VERSION ""

NS_ :

BS_:

BU_:

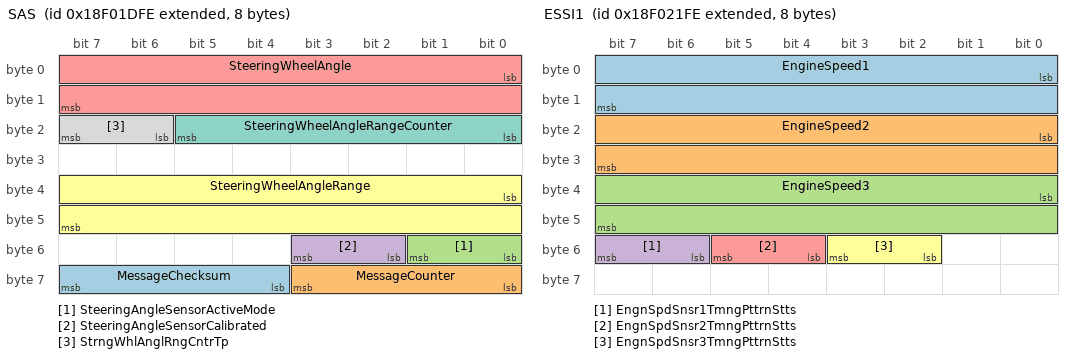
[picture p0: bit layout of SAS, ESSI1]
BO_ 2565873150 SAS: 8 Vector__XXX
 SG_ MessageChecksum : 60|4@1+ (1,0) [0|15] "count" Vector__XXX
 SG_ MessageCounter : 56|4@1+ (1,0) [0|15] "count" Vector__XXX
 SG_ SteeringAngleSensorActiveMode : 48|2@1+ (1,0) [0|3] "" Vector__XXX
 SG_ SteeringAngleSensorCalibrated : 50|2@1+ (1,0) [0|3] "" Vector__XXX
 SG_ SteeringWheelAngle : 0|16@1+ (0.0009765625,-31.374) [-31.374|31.374] "rad" Vector__XXX
 SG_ SteeringWheelAngleRange : 32|16@1+ (0.0009765625,-31.374) [-31.374|31.374] "rad" Vector__XXX
 SG_ SteeringWheelAngleRangeCounter : 16|6@1+ (1,-32) [-32|29] "range" Vector__XXX
 SG_ StrngWhlAnglRngCntrTp : 22|2@1+ (1,0) [0|3] "" Vector__XXX

BO_ 2565874174 ESSI1: 8 Vector__XXX
 SG_ EngineSpeed1 : 0|16@1+ (0.5,0) [0|32127.5] "rpm" Vector__XXX
 SG_ EngineSpeed2 : 16|16@1+ (0.5,0) [0|32127.5] "rpm" Vector__XXX
 SG_ EngineSpeed3 : 32|16@1+ (0.5,0) [0|32127.5] "rpm" Vector__XXX
 SG_ EngnSpdSnsr1TmngPttrnStts : 54|2@1+ (1,0) [0|3] "" Vector__XXX
 SG_ EngnSpdSnsr2TmngPttrnStts : 52|2@1+ (1,0) [0|3] "" Vector__XXX
 SG_ EngnSpdSnsr3TmngPttrnStts : 50|2@1+ (1,0) [0|3] "" Vector__XXX

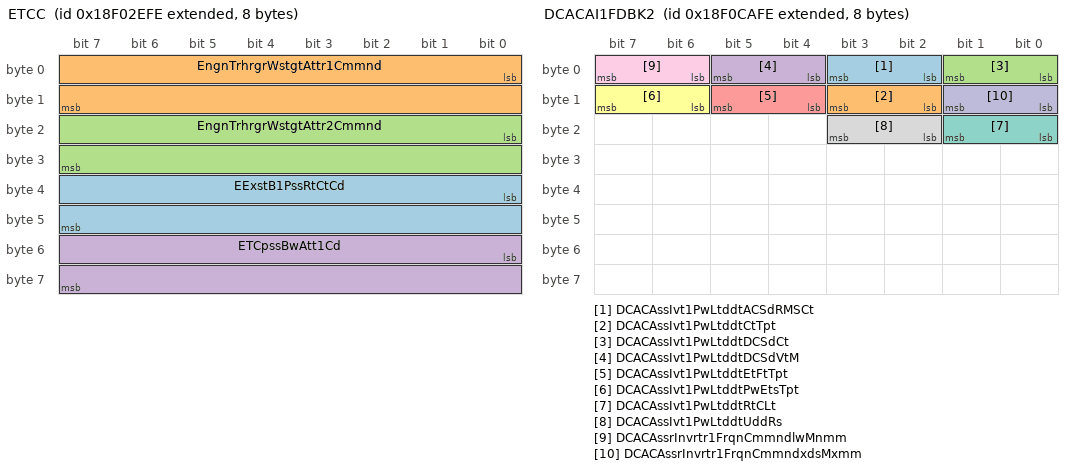
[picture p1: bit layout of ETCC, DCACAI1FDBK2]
BO_ 2565877502 ETCC: 8 Vector__XXX
 SG_ EExstB1PssRtCtCd : 32|16@1+ (0.0025,0) [0|160.6375] "%" Vector__XXX
 SG_ EngnTrhrgrWstgtAttr1Cmmnd : 0|16@1+ (0.0025,0) [0|160.6375] "%" Vector__XXX
 SG_ EngnTrhrgrWstgtAttr2Cmmnd : 16|16@1+ (0.0025,0) [0|160.6375] "%" Vector__XXX
 SG_ ETCpssBwAtt1Cd : 48|16@1+ (0.0025,0) [0|160.6375] "%" Vector__XXX

BO_ 2565917438 DCACAI1FDBK2: 8 Vector__XXX
 SG_ DCACAssIvt1PwLtddtACSdRMSCt : 2|2@1+ (1,0) [0|3] "" Vector__XXX
 SG_ DCACAssIvt1PwLtddtCtTpt : 10|2@1+ (1,0) [0|3] "" Vector__XXX
 SG_ DCACAssIvt1PwLtddtDCSdCt : 0|2@1+ (1,0) [0|3] "" Vector__XXX
 SG_ DCACAssIvt1PwLtddtDCSdVtM : 4|2@1+ (1,0) [0|3] "" Vector__XXX
 SG_ DCACAssIvt1PwLtddtEtFtTpt : 12|2@1+ (1,0) [0|3] "" Vector__XXX
 SG_ DCACAssIvt1PwLtddtPwEtsTpt : 14|2@1+ (1,0) [0|3] "" Vector__XXX
 SG_ DCACAssIvt1PwLtddtRtCLt : 16|2@1+ (1,0) [0|3] "" Vector__XXX
 SG_ DCACAssIvt1PwLtddtUddRs : 18|2@1+ (1,0) [0|3] "" Vector__XXX
 SG_ DCACAssrInvrtr1FrqnCmmndlwMnmm : 6|2@1+ (1,0) [0|3] "" Vector__XXX
 SG_ DCACAssrInvrtr1FrqnCmmndxdsMxmm : 8|2@1+ (1,0) [0|3] "" Vector__XXX

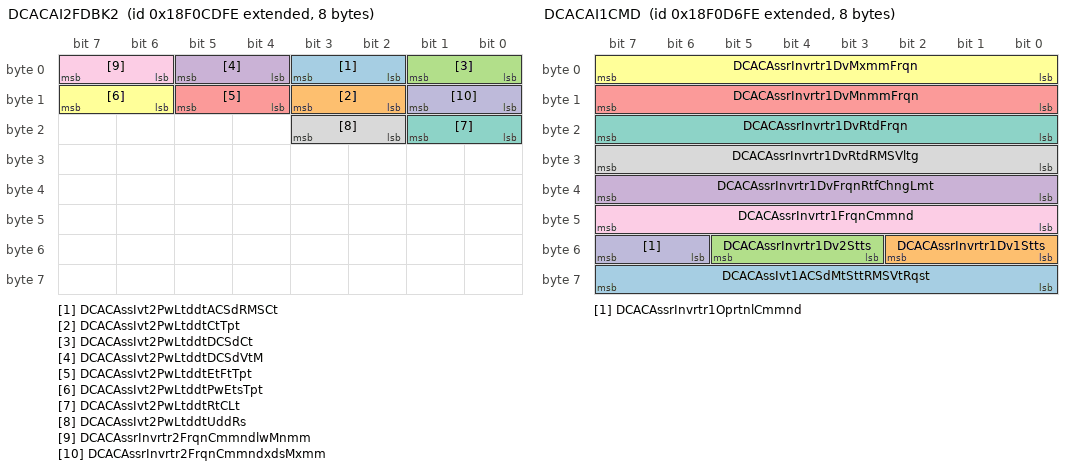
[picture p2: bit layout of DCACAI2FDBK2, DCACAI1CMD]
BO_ 2565918206 DCACAI2FDBK2: 8 Vector__XXX
 SG_ DCACAssIvt2PwLtddtACSdRMSCt : 2|2@1+ (1,0) [0|3] "" Vector__XXX
 SG_ DCACAssIvt2PwLtddtCtTpt : 10|2@1+ (1,0) [0|3] "" Vector__XXX
 SG_ DCACAssIvt2PwLtddtDCSdCt : 0|2@1+ (1,0) [0|3] "" Vector__XXX
 SG_ DCACAssIvt2PwLtddtDCSdVtM : 4|2@1+ (1,0) [0|3] "" Vector__XXX
 SG_ DCACAssIvt2PwLtddtEtFtTpt : 12|2@1+ (1,0) [0|3] "" Vector__XXX
 SG_ DCACAssIvt2PwLtddtPwEtsTpt : 14|2@1+ (1,0) [0|3] "" Vector__XXX
 SG_ DCACAssIvt2PwLtddtRtCLt : 16|2@1+ (1,0) [0|3] "" Vector__XXX
 SG_ DCACAssIvt2PwLtddtUddRs : 18|2@1+ (1,0) [0|3] "" Vector__XXX
 SG_ DCACAssrInvrtr2FrqnCmmndlwMnmm : 6|2@1+ (1,0) [0|3] "" Vector__XXX
 SG_ DCACAssrInvrtr2FrqnCmmndxdsMxmm : 8|2@1+ (1,0) [0|3] "" Vector__XXX

BO_ 2565920510 DCACAI1CMD: 8 Vector__XXX
 SG_ DCACAssIvt1ACSdMtSttRMSVtRqst : 56|8@1+ (2,0) [0|500] "V" Vector__XXX
 SG_ DCACAssrInvrtr1Dv1Stts : 48|3@1+ (1,0) [0|7] "" Vector__XXX
 SG_ DCACAssrInvrtr1Dv2Stts : 51|3@1+ (1,0) [0|7] "" Vector__XXX
 SG_ DCACAssrInvrtr1DvFrqnRtfChngLmt : 32|8@1+ (2,0) [0|500] "Hz/s" Vector__XXX
 SG_ DCACAssrInvrtr1DvMnmmFrqn : 8|8@1+ (1,0) [0|250] "Hz" Vector__XXX
 SG_ DCACAssrInvrtr1DvMxmmFrqn : 0|8@1+ (1,0) [0|250] "Hz" Vector__XXX
 SG_ DCACAssrInvrtr1DvRtdFrqn : 16|8@1+ (1,0) [0|250] "Hz" Vector__XXX
 SG_ DCACAssrInvrtr1DvRtdRMSVltg : 24|8@1+ (2,0) [0|500] "V" Vector__XXX
 SG_ DCACAssrInvrtr1FrqnCmmnd : 40|8@1+ (1,0) [0|250] "Hz" Vector__XXX
 SG_ DCACAssrInvrtr1OprtnlCmmnd : 54|2@1+ (1,0) [0|3] "" Vector__XXX

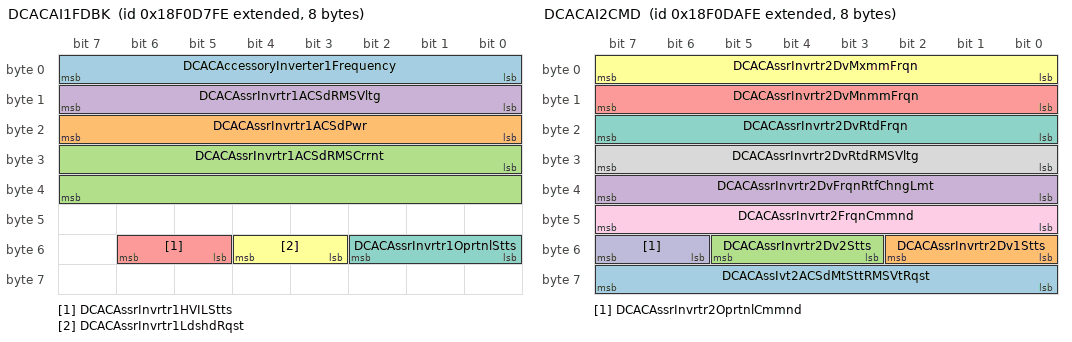
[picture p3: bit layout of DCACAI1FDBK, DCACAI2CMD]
BO_ 2565920766 DCACAI1FDBK: 8 Vector__XXX
 SG_ DCACAccessoryInverter1Frequency : 0|8@1+ (1,0) [0|250] "Hz" Vector__XXX
 SG_ DCACAssrInvrtr1ACSdPwr : 16|8@1+ (0.1,0) [0|25] "kW" Vector__XXX
 SG_ DCACAssrInvrtr1ACSdRMSCrrnt : 24|16@1+ (0.03125,0) [0|2007.96875] "A" Vector__XXX
 SG_ DCACAssrInvrtr1ACSdRMSVltg : 8|8@1+ (2,0) [0|500] "V" Vector__XXX
 SG_ DCACAssrInvrtr1HVILStts : 53|2@1+ (1,0) [0|3] "" Vector__XXX
 SG_ DCACAssrInvrtr1LdshdRqst : 51|2@1+ (1,0) [0|3] "" Vector__XXX
 SG_ DCACAssrInvrtr1OprtnlStts : 48|3@1+ (1,0) [0|7] "" Vector__XXX

BO_ 2565921534 DCACAI2CMD: 8 Vector__XXX
 SG_ DCACAssIvt2ACSdMtSttRMSVtRqst : 56|8@1+ (2,0) [0|500] "V" Vector__XXX
 SG_ DCACAssrInvrtr2Dv1Stts : 48|3@1+ (1,0) [0|7] "" Vector__XXX
 SG_ DCACAssrInvrtr2Dv2Stts : 51|3@1+ (1,0) [0|7] "" Vector__XXX
 SG_ DCACAssrInvrtr2DvFrqnRtfChngLmt : 32|8@1+ (2,0) [0|500] "Hz/s" Vector__XXX
 SG_ DCACAssrInvrtr2DvMnmmFrqn : 8|8@1+ (1,0) [0|250] "Hz" Vector__XXX
 SG_ DCACAssrInvrtr2DvMxmmFrqn : 0|8@1+ (1,0) [0|250] "Hz" Vector__XXX
 SG_ DCACAssrInvrtr2DvRtdFrqn : 16|8@1+ (1,0) [0|250] "Hz" Vector__XXX
 SG_ DCACAssrInvrtr2DvRtdRMSVltg : 24|8@1+ (2,0) [0|500] "V" Vector__XXX
 SG_ DCACAssrInvrtr2FrqnCmmnd : 40|8@1+ (1,0) [0|250] "Hz" Vector__XXX
 SG_ DCACAssrInvrtr2OprtnlCmmnd : 54|2@1+ (1,0) [0|3] "" Vector__XXX

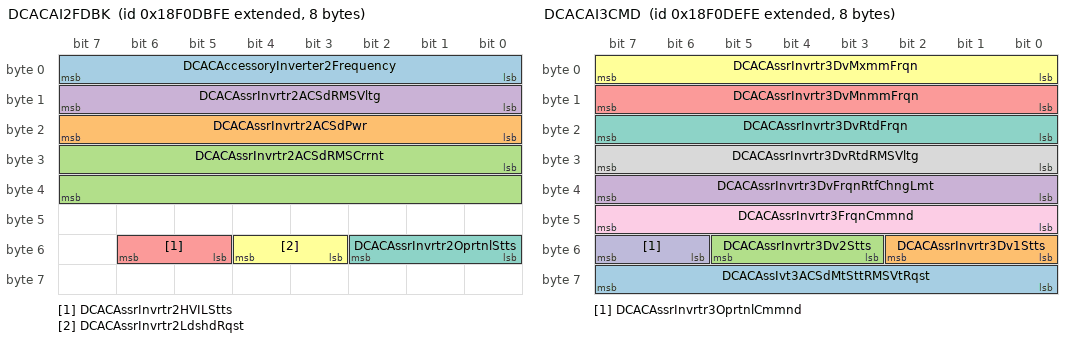
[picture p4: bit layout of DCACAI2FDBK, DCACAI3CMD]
BO_ 2565921790 DCACAI2FDBK: 8 Vector__XXX
 SG_ DCACAccessoryInverter2Frequency : 0|8@1+ (1,0) [0|250] "Hz" Vector__XXX
 SG_ DCACAssrInvrtr2ACSdPwr : 16|8@1+ (0.1,0) [0|25] "kW" Vector__XXX
 SG_ DCACAssrInvrtr2ACSdRMSCrrnt : 24|16@1+ (0.03125,0) [0|2007.96875] "A" Vector__XXX
 SG_ DCACAssrInvrtr2ACSdRMSVltg : 8|8@1+ (2,0) [0|500] "V" Vector__XXX
 SG_ DCACAssrInvrtr2HVILStts : 53|2@1+ (1,0) [0|3] "" Vector__XXX
 SG_ DCACAssrInvrtr2LdshdRqst : 51|2@1+ (1,0) [0|3] "" Vector__XXX
 SG_ DCACAssrInvrtr2OprtnlStts : 48|3@1+ (1,0) [0|7] "" Vector__XXX

BO_ 2565922558 DCACAI3CMD: 8 Vector__XXX
 SG_ DCACAssIvt3ACSdMtSttRMSVtRqst : 56|8@1+ (2,0) [0|500] "V" Vector__XXX
 SG_ DCACAssrInvrtr3Dv1Stts : 48|3@1+ (1,0) [0|7] "" Vector__XXX
 SG_ DCACAssrInvrtr3Dv2Stts : 51|3@1+ (1,0) [0|7] "" Vector__XXX
 SG_ DCACAssrInvrtr3DvFrqnRtfChngLmt : 32|8@1+ (2,0) [0|500] "Hz/s" Vector__XXX
 SG_ DCACAssrInvrtr3DvMnmmFrqn : 8|8@1+ (1,0) [0|250] "Hz" Vector__XXX
 SG_ DCACAssrInvrtr3DvMxmmFrqn : 0|8@1+ (1,0) [0|250] "Hz" Vector__XXX
 SG_ DCACAssrInvrtr3DvRtdFrqn : 16|8@1+ (1,0) [0|250] "Hz" Vector__XXX
 SG_ DCACAssrInvrtr3DvRtdRMSVltg : 24|8@1+ (2,0) [0|500] "V" Vector__XXX
 SG_ DCACAssrInvrtr3FrqnCmmnd : 40|8@1+ (1,0) [0|250] "Hz" Vector__XXX
 SG_ DCACAssrInvrtr3OprtnlCmmnd : 54|2@1+ (1,0) [0|3] "" Vector__XXX

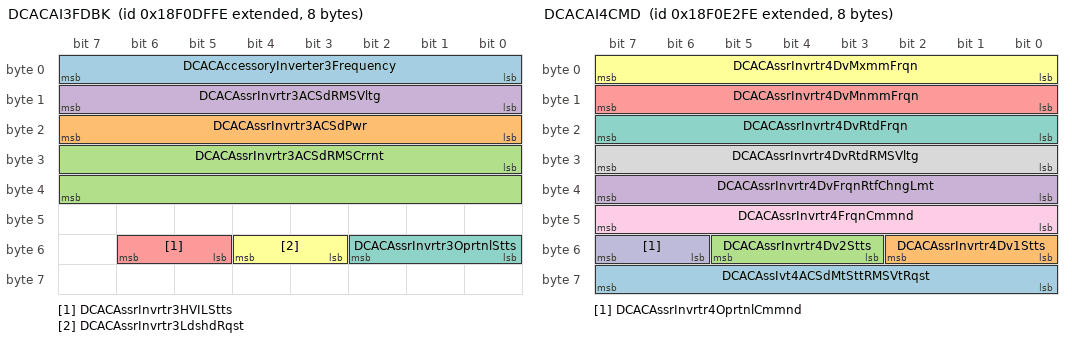
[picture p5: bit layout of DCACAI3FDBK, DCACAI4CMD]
BO_ 2565922814 DCACAI3FDBK: 8 Vector__XXX
 SG_ DCACAccessoryInverter3Frequency : 0|8@1+ (1,0) [0|250] "Hz" Vector__XXX
 SG_ DCACAssrInvrtr3ACSdPwr : 16|8@1+ (0.1,0) [0|25] "kW" Vector__XXX
 SG_ DCACAssrInvrtr3ACSdRMSCrrnt : 24|16@1+ (0.03125,0) [0|2007.96875] "A" Vector__XXX
 SG_ DCACAssrInvrtr3ACSdRMSVltg : 8|8@1+ (2,0) [0|500] "V" Vector__XXX
 SG_ DCACAssrInvrtr3HVILStts : 53|2@1+ (1,0) [0|3] "" Vector__XXX
 SG_ DCACAssrInvrtr3LdshdRqst : 51|2@1+ (1,0) [0|3] "" Vector__XXX
 SG_ DCACAssrInvrtr3OprtnlStts : 48|3@1+ (1,0) [0|7] "" Vector__XXX

BO_ 2565923582 DCACAI4CMD: 8 Vector__XXX
 SG_ DCACAssIvt4ACSdMtSttRMSVtRqst : 56|8@1+ (2,0) [0|500] "V" Vector__XXX
 SG_ DCACAssrInvrtr4Dv1Stts : 48|3@1+ (1,0) [0|7] "" Vector__XXX
 SG_ DCACAssrInvrtr4Dv2Stts : 51|3@1+ (1,0) [0|7] "" Vector__XXX
 SG_ DCACAssrInvrtr4DvFrqnRtfChngLmt : 32|8@1+ (2,0) [0|500] "Hz/s" Vector__XXX
 SG_ DCACAssrInvrtr4DvMnmmFrqn : 8|8@1+ (1,0) [0|250] "Hz" Vector__XXX
 SG_ DCACAssrInvrtr4DvMxmmFrqn : 0|8@1+ (1,0) [0|250] "Hz" Vector__XXX
 SG_ DCACAssrInvrtr4DvRtdFrqn : 16|8@1+ (1,0) [0|250] "Hz" Vector__XXX
 SG_ DCACAssrInvrtr4DvRtdRMSVltg : 24|8@1+ (2,0) [0|500] "V" Vector__XXX
 SG_ DCACAssrInvrtr4FrqnCmmnd : 40|8@1+ (1,0) [0|250] "Hz" Vector__XXX
 SG_ DCACAssrInvrtr4OprtnlCmmnd : 54|2@1+ (1,0) [0|3] "" Vector__XXX

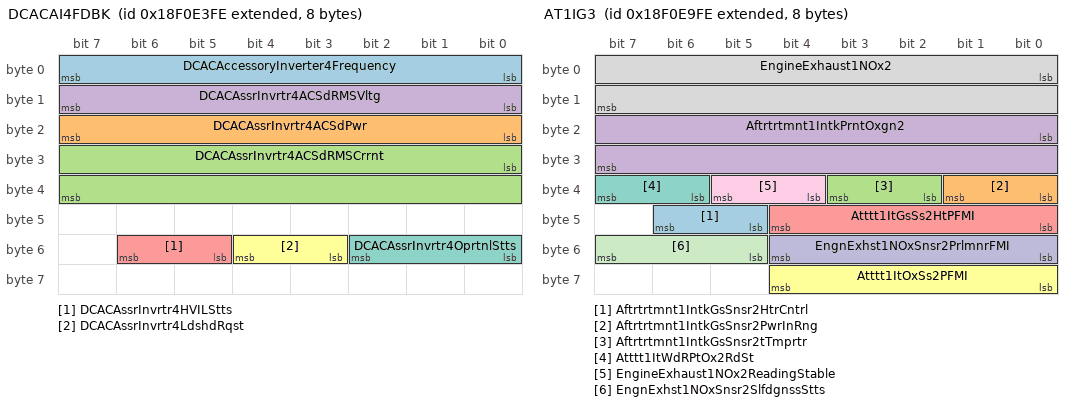
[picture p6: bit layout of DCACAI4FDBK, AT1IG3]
BO_ 2565923838 DCACAI4FDBK: 8 Vector__XXX
 SG_ DCACAccessoryInverter4Frequency : 0|8@1+ (1,0) [0|250] "Hz" Vector__XXX
 SG_ DCACAssrInvrtr4ACSdPwr : 16|8@1+ (0.1,0) [0|25] "kW" Vector__XXX
 SG_ DCACAssrInvrtr4ACSdRMSCrrnt : 24|16@1+ (0.03125,0) [0|2007.96875] "A" Vector__XXX
 SG_ DCACAssrInvrtr4ACSdRMSVltg : 8|8@1+ (2,0) [0|500] "V" Vector__XXX
 SG_ DCACAssrInvrtr4HVILStts : 53|2@1+ (1,0) [0|3] "" Vector__XXX
 SG_ DCACAssrInvrtr4LdshdRqst : 51|2@1+ (1,0) [0|3] "" Vector__XXX
 SG_ DCACAssrInvrtr4OprtnlStts : 48|3@1+ (1,0) [0|7] "" Vector__XXX

BO_ 2565925374 AT1IG3: 8 Vector__XXX
 SG_ Aftrtrtmnt1IntkGsSnsr2HtrCntrl : 45|2@1+ (1,0) [0|3] "" Vector__XXX
 SG_ Aftrtrtmnt1IntkGsSnsr2PwrInRng : 32|2@1+ (1,0) [0|3] "" Vector__XXX
 SG_ Aftrtrtmnt1IntkGsSnsr2tTmprtr : 34|2@1+ (1,0) [0|3] "" Vector__XXX
 SG_ Aftrtrtmnt1IntkPrntOxgn2 : 16|16@1+ (0.000514,-12) [-12|21.02707] "%" Vector__XXX
 SG_ Atttt1ItGsSs2HtPFMI : 40|5@1+ (1,0) [0|31] "binary" Vector__XXX
 SG_ Atttt1ItOxSs2PFMI : 56|5@1+ (1,0) [0|31] "binary" Vector__XXX
 SG_ Atttt1ItWdRPtOx2RdSt : 38|2@1+ (1,0) [0|3] "" Vector__XXX
 SG_ EngineExhaust1NOx2 : 0|16@1+ (0.05,-200) [-200|3012.75] "ppm" Vector__XXX
 SG_ EngineExhaust1NOx2ReadingStable : 36|2@1+ (1,0) [0|3] "" Vector__XXX
 SG_ EngnExhst1NOxSnsr2PrlmnrFMI : 48|5@1+ (1,0) [0|31] "binary" Vector__XXX
 SG_ EngnExhst1NOxSnsr2SlfdgnssStts : 53|3@1+ (1,0) [0|7] "" Vector__XXX

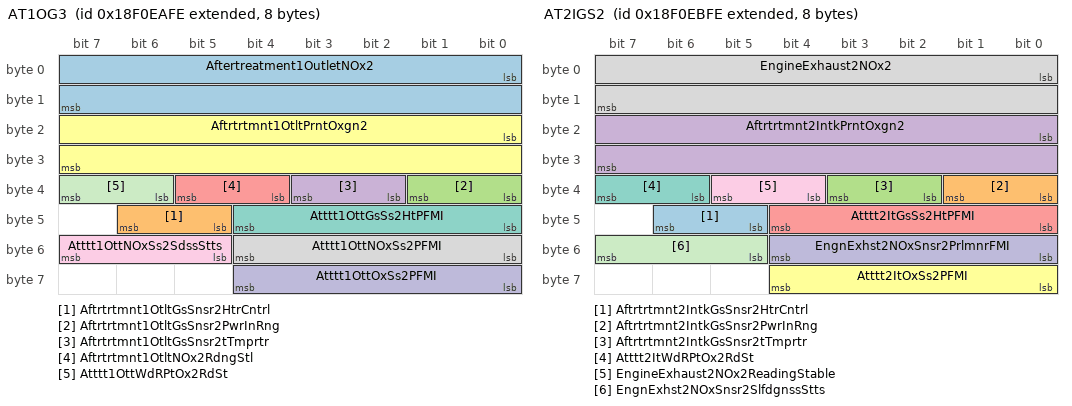
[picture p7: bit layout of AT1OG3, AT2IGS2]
BO_ 2565925630 AT1OG3: 8 Vector__XXX
 SG_ Aftertreatment1OutletNOx2 : 0|16@1+ (0.05,-200) [-200|3012.75] "ppm" Vector__XXX
 SG_ Aftrtrtmnt1OtltGsSnsr2HtrCntrl : 45|2@1+ (1,0) [0|3] "" Vector__XXX
 SG_ Aftrtrtmnt1OtltGsSnsr2PwrInRng : 32|2@1+ (1,0) [0|3] "" Vector__XXX
 SG_ Aftrtrtmnt1OtltGsSnsr2tTmprtr : 34|2@1+ (1,0) [0|3] "" Vector__XXX
 SG_ Aftrtrtmnt1OtltNOx2RdngStl : 36|2@1+ (1,0) [0|3] "" Vector__XXX
 SG_ Aftrtrtmnt1OtltPrntOxgn2 : 16|16@1+ (0.000514,-12) [-12|21.02707] "%" Vector__XXX
 SG_ Atttt1OttGsSs2HtPFMI : 40|5@1+ (1,0) [0|31] "binary" Vector__XXX
 SG_ Atttt1OttNOxSs2PFMI : 48|5@1+ (1,0) [0|31] "binary" Vector__XXX
 SG_ Atttt1OttNOxSs2SdssStts : 53|3@1+ (1,0) [0|7] "" Vector__XXX
 SG_ Atttt1OttOxSs2PFMI : 56|5@1+ (1,0) [0|31] "binary" Vector__XXX
 SG_ Atttt1OttWdRPtOx2RdSt : 38|2@1+ (1,0) [0|3] "" Vector__XXX

BO_ 2565925886 AT2IGS2: 8 Vector__XXX
 SG_ Aftrtrtmnt2IntkGsSnsr2HtrCntrl : 45|2@1+ (1,0) [0|3] "" Vector__XXX
 SG_ Aftrtrtmnt2IntkGsSnsr2PwrInRng : 32|2@1+ (1,0) [0|3] "" Vector__XXX
 SG_ Aftrtrtmnt2IntkGsSnsr2tTmprtr : 34|2@1+ (1,0) [0|3] "" Vector__XXX
 SG_ Aftrtrtmnt2IntkPrntOxgn2 : 16|16@1+ (0.000514,-12) [-12|21.02707] "%" Vector__XXX
 SG_ Atttt2ItGsSs2HtPFMI : 40|5@1+ (1,0) [0|31] "binary" Vector__XXX
 SG_ Atttt2ItOxSs2PFMI : 56|5@1+ (1,0) [0|31] "binary" Vector__XXX
 SG_ Atttt2ItWdRPtOx2RdSt : 38|2@1+ (1,0) [0|3] "" Vector__XXX
 SG_ EngineExhaust2NOx2 : 0|16@1+ (0.05,-200) [-200|3012.75] "ppm" Vector__XXX
 SG_ EngineExhaust2NOx2ReadingStable : 36|2@1+ (1,0) [0|3] "" Vector__XXX
 SG_ EngnExhst2NOxSnsr2PrlmnrFMI : 48|5@1+ (1,0) [0|31] "binary" Vector__XXX
 SG_ EngnExhst2NOxSnsr2SlfdgnssStts : 53|3@1+ (1,0) [0|7] "" Vector__XXX

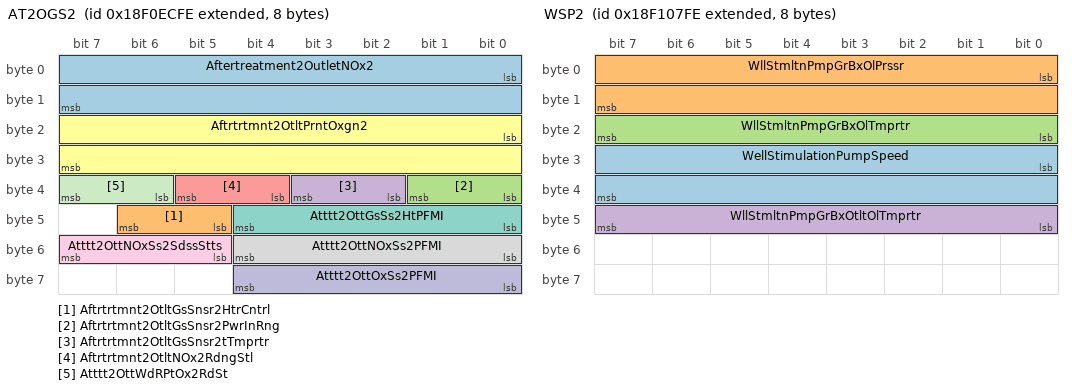
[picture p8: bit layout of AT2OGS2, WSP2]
BO_ 2565926142 AT2OGS2: 8 Vector__XXX
 SG_ Aftertreatment2OutletNOx2 : 0|16@1+ (0.05,-200) [-200|3012.75] "ppm" Vector__XXX
 SG_ Aftrtrtmnt2OtltGsSnsr2HtrCntrl : 45|2@1+ (1,0) [0|3] "" Vector__XXX
 SG_ Aftrtrtmnt2OtltGsSnsr2PwrInRng : 32|2@1+ (1,0) [0|3] "" Vector__XXX
 SG_ Aftrtrtmnt2OtltGsSnsr2tTmprtr : 34|2@1+ (1,0) [0|3] "" Vector__XXX
 SG_ Aftrtrtmnt2OtltNOx2RdngStl : 36|2@1+ (1,0) [0|3] "" Vector__XXX
 SG_ Aftrtrtmnt2OtltPrntOxgn2 : 16|16@1+ (0.000514,-12) [-12|21.02707] "%" Vector__XXX
 SG_ Atttt2OttGsSs2HtPFMI : 40|5@1+ (1,0) [0|31] "binary" Vector__XXX
 SG_ Atttt2OttNOxSs2PFMI : 48|5@1+ (1,0) [0|31] "binary" Vector__XXX
 SG_ Atttt2OttNOxSs2SdssStts : 53|3@1+ (1,0) [0|7] "" Vector__XXX
 SG_ Atttt2OttOxSs2PFMI : 56|5@1+ (1,0) [0|31] "binary" Vector__XXX
 SG_ Atttt2OttWdRPtOx2RdSt : 38|2@1+ (1,0) [0|3] "" Vector__XXX

BO_ 2565932286 ESSI2: 8 Vector__XXX
 SG_ EngineSpeed4 : 0|16@1+ (0.5,0) [0|32127.5] "rpm" Vector__XXX

BO_ 2565932798 WSP1: 8 Vector__XXX
 SG_ WllStmltnPmpDshrgPrssr : 16|16@1+ (5,0) [0|321275] "kPa" Vector__XXX
 SG_ WllStmltnPmpStnPrssr : 0|16@1+ (0.1,-3212.7) [-3212.7|3212.8] "kPa" Vector__XXX

BO_ 2565933054 WSP2: 8 Vector__XXX
 SG_ WellStimulationPumpSpeed : 24|16@1+ (0.125,0) [0|8031.875] "rpm" Vector__XXX
 SG_ WllStmltnPmpGrBxOlPrssr : 0|16@1+ (0.1,0) [0|6425.5] "kPa" Vector__XXX
 SG_ WllStmltnPmpGrBxOlTmprtr : 16|8@1+ (1,-40) [-40|210] "degC" Vector__XXX
 SG_ WllStmltnPmpGrBxOtltOlTmprtr : 40|8@1+ (1,-40) [-40|210] "degC" Vector__XXX

BO_ 2565934590 GFI6: 8 Vector__XXX
 SG_ EngnFlVlv2DffrntlPrssr : 0|16@1+ (0.1,0) [0|6425.5] "kPa" Vector__XXX

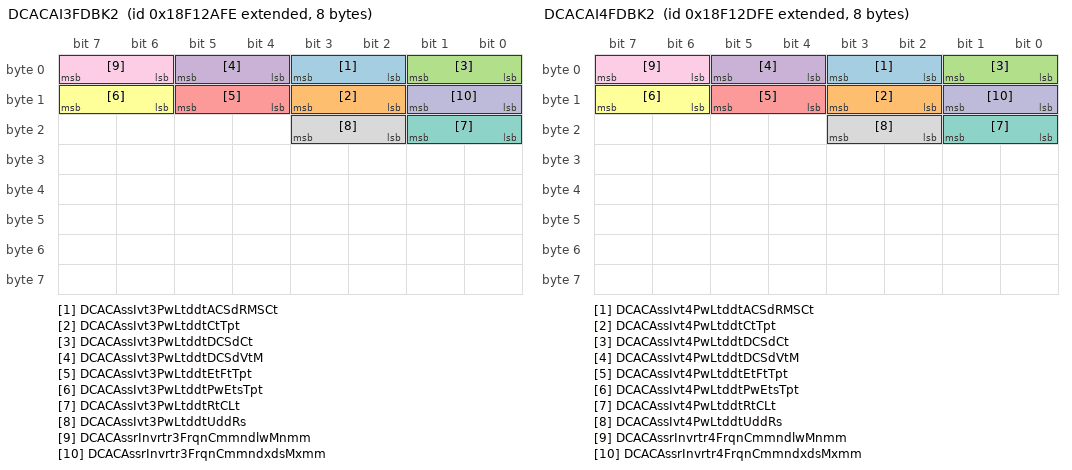
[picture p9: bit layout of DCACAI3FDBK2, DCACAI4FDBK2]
BO_ 2565942014 DCACAI3FDBK2: 8 Vector__XXX
 SG_ DCACAssIvt3PwLtddtACSdRMSCt : 2|2@1+ (1,0) [0|3] "" Vector__XXX
 SG_ DCACAssIvt3PwLtddtCtTpt : 10|2@1+ (1,0) [0|3] "" Vector__XXX
 SG_ DCACAssIvt3PwLtddtDCSdCt : 0|2@1+ (1,0) [0|3] "" Vector__XXX
 SG_ DCACAssIvt3PwLtddtDCSdVtM : 4|2@1+ (1,0) [0|3] "" Vector__XXX
 SG_ DCACAssIvt3PwLtddtEtFtTpt : 12|2@1+ (1,0) [0|3] "" Vector__XXX
 SG_ DCACAssIvt3PwLtddtPwEtsTpt : 14|2@1+ (1,0) [0|3] "" Vector__XXX
 SG_ DCACAssIvt3PwLtddtRtCLt : 16|2@1+ (1,0) [0|3] "" Vector__XXX
 SG_ DCACAssIvt3PwLtddtUddRs : 18|2@1+ (1,0) [0|3] "" Vector__XXX
 SG_ DCACAssrInvrtr3FrqnCmmndlwMnmm : 6|2@1+ (1,0) [0|3] "" Vector__XXX
 SG_ DCACAssrInvrtr3FrqnCmmndxdsMxmm : 8|2@1+ (1,0) [0|3] "" Vector__XXX

BO_ 2565942782 DCACAI4FDBK2: 8 Vector__XXX
 SG_ DCACAssIvt4PwLtddtACSdRMSCt : 2|2@1+ (1,0) [0|3] "" Vector__XXX
 SG_ DCACAssIvt4PwLtddtCtTpt : 10|2@1+ (1,0) [0|3] "" Vector__XXX
 SG_ DCACAssIvt4PwLtddtDCSdCt : 0|2@1+ (1,0) [0|3] "" Vector__XXX
 SG_ DCACAssIvt4PwLtddtDCSdVtM : 4|2@1+ (1,0) [0|3] "" Vector__XXX
 SG_ DCACAssIvt4PwLtddtEtFtTpt : 12|2@1+ (1,0) [0|3] "" Vector__XXX
 SG_ DCACAssIvt4PwLtddtPwEtsTpt : 14|2@1+ (1,0) [0|3] "" Vector__XXX
 SG_ DCACAssIvt4PwLtddtRtCLt : 16|2@1+ (1,0) [0|3] "" Vector__XXX
 SG_ DCACAssIvt4PwLtddtUddRs : 18|2@1+ (1,0) [0|3] "" Vector__XXX
 SG_ DCACAssrInvrtr4FrqnCmmndlwMnmm : 6|2@1+ (1,0) [0|3] "" Vector__XXX
 SG_ DCACAssrInvrtr4FrqnCmmndxdsMxmm : 8|2@1+ (1,0) [0|3] "" Vector__XXX

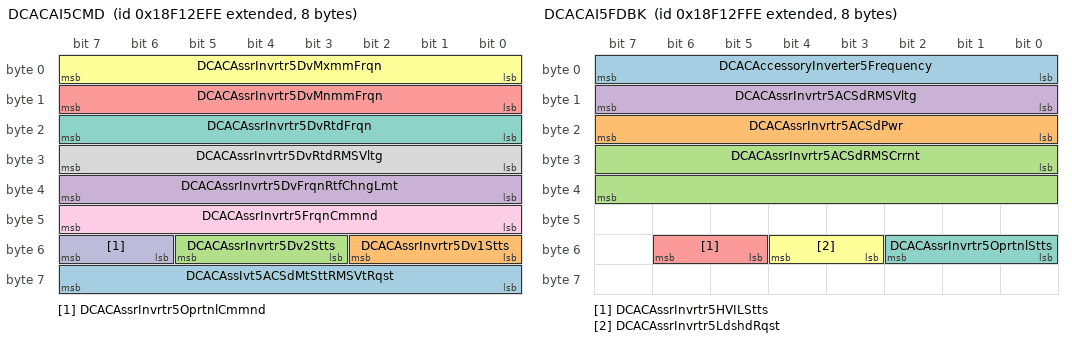
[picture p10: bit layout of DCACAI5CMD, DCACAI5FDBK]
BO_ 2565943038 DCACAI5CMD: 8 Vector__XXX
 SG_ DCACAssIvt5ACSdMtSttRMSVtRqst : 56|8@1+ (2,0) [0|500] "V" Vector__XXX
 SG_ DCACAssrInvrtr5Dv1Stts : 48|3@1+ (1,0) [0|7] "" Vector__XXX
 SG_ DCACAssrInvrtr5Dv2Stts : 51|3@1+ (1,0) [0|7] "" Vector__XXX
 SG_ DCACAssrInvrtr5DvFrqnRtfChngLmt : 32|8@1+ (2,0) [0|500] "Hz/s" Vector__XXX
 SG_ DCACAssrInvrtr5DvMnmmFrqn : 8|8@1+ (1,0) [0|250] "Hz" Vector__XXX
 SG_ DCACAssrInvrtr5DvMxmmFrqn : 0|8@1+ (1,0) [0|250] "Hz" Vector__XXX
 SG_ DCACAssrInvrtr5DvRtdFrqn : 16|8@1+ (1,0) [0|250] "Hz" Vector__XXX
 SG_ DCACAssrInvrtr5DvRtdRMSVltg : 24|8@1+ (2,0) [0|500] "V" Vector__XXX
 SG_ DCACAssrInvrtr5FrqnCmmnd : 40|8@1+ (1,0) [0|250] "Hz" Vector__XXX
 SG_ DCACAssrInvrtr5OprtnlCmmnd : 54|2@1+ (1,0) [0|3] "" Vector__XXX

BO_ 2565943294 DCACAI5FDBK: 8 Vector__XXX
 SG_ DCACAccessoryInverter5Frequency : 0|8@1+ (1,0) [0|250] "Hz" Vector__XXX
 SG_ DCACAssrInvrtr5ACSdPwr : 16|8@1+ (0.1,0) [0|25] "kW" Vector__XXX
 SG_ DCACAssrInvrtr5ACSdRMSCrrnt : 24|16@1+ (0.03125,0) [0|2007.96875] "A" Vector__XXX
 SG_ DCACAssrInvrtr5ACSdRMSVltg : 8|8@1+ (2,0) [0|500] "V" Vector__XXX
 SG_ DCACAssrInvrtr5HVILStts : 53|2@1+ (1,0) [0|3] "" Vector__XXX
 SG_ DCACAssrInvrtr5LdshdRqst : 51|2@1+ (1,0) [0|3] "" Vector__XXX
 SG_ DCACAssrInvrtr5OprtnlStts : 48|3@1+ (1,0) [0|7] "" Vector__XXX

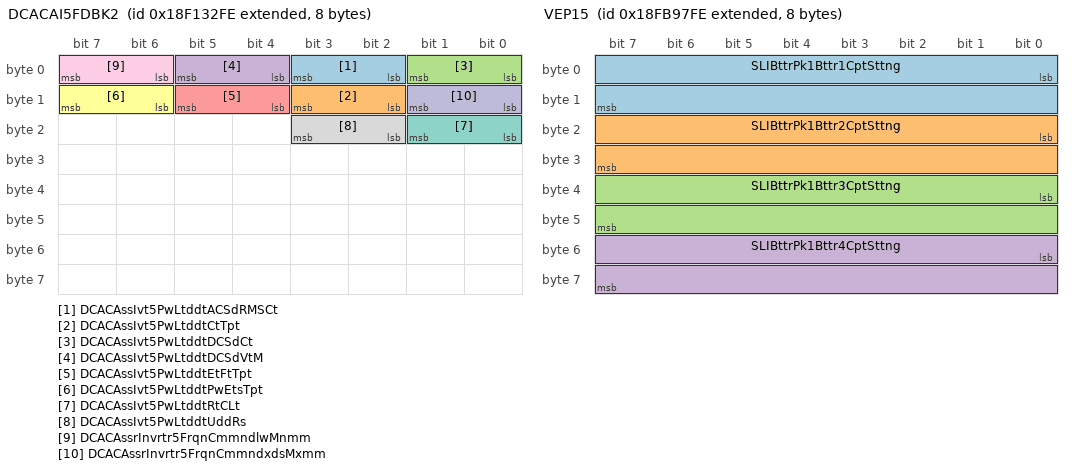
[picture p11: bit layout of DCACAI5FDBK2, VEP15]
BO_ 2565944062 DCACAI5FDBK2: 8 Vector__XXX
 SG_ DCACAssIvt5PwLtddtACSdRMSCt : 2|2@1+ (1,0) [0|3] "" Vector__XXX
 SG_ DCACAssIvt5PwLtddtCtTpt : 10|2@1+ (1,0) [0|3] "" Vector__XXX
 SG_ DCACAssIvt5PwLtddtDCSdCt : 0|2@1+ (1,0) [0|3] "" Vector__XXX
 SG_ DCACAssIvt5PwLtddtDCSdVtM : 4|2@1+ (1,0) [0|3] "" Vector__XXX
 SG_ DCACAssIvt5PwLtddtEtFtTpt : 12|2@1+ (1,0) [0|3] "" Vector__XXX
 SG_ DCACAssIvt5PwLtddtPwEtsTpt : 14|2@1+ (1,0) [0|3] "" Vector__XXX
 SG_ DCACAssIvt5PwLtddtRtCLt : 16|2@1+ (1,0) [0|3] "" Vector__XXX
 SG_ DCACAssIvt5PwLtddtUddRs : 18|2@1+ (1,0) [0|3] "" Vector__XXX
 SG_ DCACAssrInvrtr5FrqnCmmndlwMnmm : 6|2@1+ (1,0) [0|3] "" Vector__XXX
 SG_ DCACAssrInvrtr5FrqnCmmndxdsMxmm : 8|2@1+ (1,0) [0|3] "" Vector__XXX

BO_ 2566624510 EEC22: 8 Vector__XXX
 SG_ EngnExhstGsRrltn1ClrIntkPrssr : 0|16@1+ (5,0) [0|321275] "kPa" Vector__XXX

BO_ 2566624766 HOURS2: 8 Vector__XXX
 SG_ EngnIdlMngmntAtvTtlTm : 0|32@1+ (0.05,0) [0|210554060.75] "h" Vector__XXX

BO_ 2566625022 EI3: 8 Vector__XXX
 SG_ InstntnsEstmtdEngnPwrRtLmt : 0|16@1+ (0.125,0) [0|8031.875] "kW/s" Vector__XXX

BO_ 2566625278 VEP15: 8 Vector__XXX
 SG_ SLIBttrPk1Bttr1CptSttng : 0|16@1+ (1,0) [0|64255] "Ah" Vector__XXX
 SG_ SLIBttrPk1Bttr2CptSttng : 16|16@1+ (1,0) [0|64255] "Ah" Vector__XXX
 SG_ SLIBttrPk1Bttr3CptSttng : 32|16@1+ (1,0) [0|64255] "Ah" Vector__XXX
 SG_ SLIBttrPk1Bttr4CptSttng : 48|16@1+ (1,0) [0|64255] "Ah" Vector__XXX

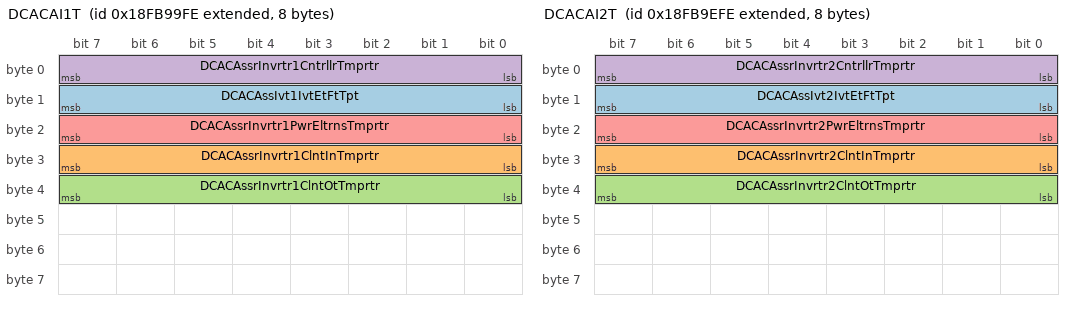
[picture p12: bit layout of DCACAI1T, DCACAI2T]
BO_ 2566625790 DCACAI1T: 8 Vector__XXX
 SG_ DCACAssIvt1IvtEtFtTpt : 8|8@1+ (1,-40) [-40|210] "degC" Vector__XXX
 SG_ DCACAssrInvrtr1ClntInTmprtr : 24|8@1+ (1,-40) [-40|210] "degC" Vector__XXX
 SG_ DCACAssrInvrtr1ClntOtTmprtr : 32|8@1+ (1,-40) [-40|210] "degC" Vector__XXX
 SG_ DCACAssrInvrtr1CntrllrTmprtr : 0|8@1+ (1,-40) [-40|210] "degC" Vector__XXX
 SG_ DCACAssrInvrtr1PwrEltrnsTmprtr : 16|8@1+ (1,-40) [-40|210] "degC" Vector__XXX

BO_ 2566626558 DCACAI1CFG1: 13 Vector__XXX
 SG_ DCACAssIvt1ACSdDtFqCdStt : 96|8@1+ (1,0) [0|250] "Hz" Vector__XXX
 SG_ DCACAssIvt1ACSdRMSCtMxLtStt : 48|16@1+ (0.03125,0) [0|2007.96875] "A" Vector__XXX
 SG_ DCACAssIvt1ACSdRMSVtMxLtStt : 32|16@1+ (0.03125,0) [0|2007.96875] "V" Vector__XXX
 SG_ DCACAssIvt1DCSdCtMLtStt : 80|16@1+ (0.05,-3212.75) [-3212.75|0] "A" Vector__XXX
 SG_ DCACAssIvt1DCSdCtMxLtStt : 16|16@1+ (0.05,0) [0|3212.75] "A" Vector__XXX
 SG_ DCACAssIvt1DCSdVtMLtStt : 0|16@1+ (0.05,0) [0|3212.75] "V" Vector__XXX
 SG_ DCACAssIvt1DCSdVtMxLtStt : 64|16@1+ (0.05,0) [0|3212.75] "V" Vector__XXX

BO_ 2566626814 DCACAI1LD: 8 Vector__XXX
 SG_ DCACAssrInvrtr1TtlDCInptChrg : 0|32@1+ (100,0) [0|421108121500] "Ah" Vector__XXX
 SG_ DCACAssrInvrtr1TtlDCInptEnrg : 32|32@1+ (100,0) [0|421108121500] "Watt-hour" Vector__XXX

BO_ 2566627070 DCACAI2T: 8 Vector__XXX
 SG_ DCACAssIvt2IvtEtFtTpt : 8|8@1+ (1,-40) [-40|210] "degC" Vector__XXX
 SG_ DCACAssrInvrtr2ClntInTmprtr : 24|8@1+ (1,-40) [-40|210] "degC" Vector__XXX
 SG_ DCACAssrInvrtr2ClntOtTmprtr : 32|8@1+ (1,-40) [-40|210] "degC" Vector__XXX
 SG_ DCACAssrInvrtr2CntrllrTmprtr : 0|8@1+ (1,-40) [-40|210] "degC" Vector__XXX
 SG_ DCACAssrInvrtr2PwrEltrnsTmprtr : 16|8@1+ (1,-40) [-40|210] "degC" Vector__XXX

BO_ 2566627838 DCACAI2CFG1: 13 Vector__XXX
 SG_ DCACAssIvt2ACSdDtFqCdStt : 96|8@1+ (1,0) [0|250] "Hz" Vector__XXX
 SG_ DCACAssIvt2ACSdRMSCtMxLtStt : 48|16@1+ (0.03125,0) [0|2007.96875] "A" Vector__XXX
 SG_ DCACAssIvt2ACSdRMSVtMxLtStt : 32|16@1+ (0.03125,0) [0|2007.96875] "V" Vector__XXX
 SG_ DCACAssIvt2DCSdCtMLtStt : 80|16@1+ (0.05,-3212.75) [-3212.75|0] "A" Vector__XXX
 SG_ DCACAssIvt2DCSdCtMxLtStt : 16|16@1+ (0.05,0) [0|3212.75] "A" Vector__XXX
 SG_ DCACAssIvt2DCSdVtMLtStt : 0|16@1+ (0.05,0) [0|3212.75] "V" Vector__XXX
 SG_ DCACAssIvt2DCSdVtMxLtStt : 64|16@1+ (0.05,0) [0|3212.75] "V" Vector__XXX

BO_ 2566628094 DCACAI2LD: 8 Vector__XXX
 SG_ DCACAssrInvrtr2TtlDCInptChrg : 0|32@1+ (100,0) [0|421108121500] "Ah" Vector__XXX
 SG_ DCACAssrInvrtr2TtlDCInptEnrg : 32|32@1+ (100,0) [0|421108121500] "Watt-hour" Vector__XXX

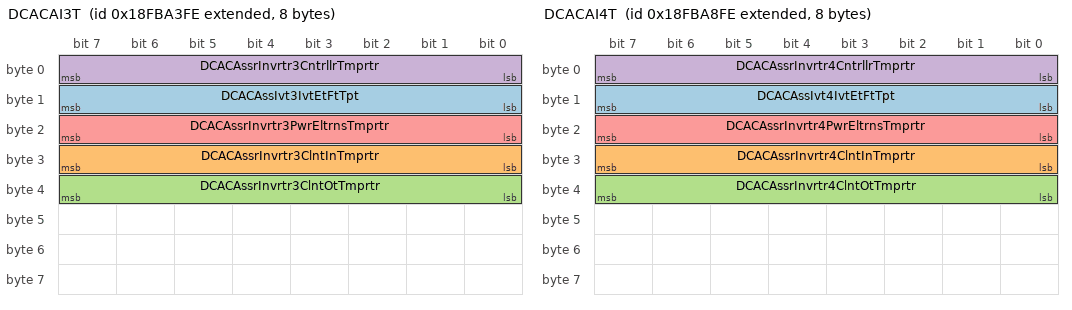
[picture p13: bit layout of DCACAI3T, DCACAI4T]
BO_ 2566628350 DCACAI3T: 8 Vector__XXX
 SG_ DCACAssIvt3IvtEtFtTpt : 8|8@1+ (1,-40) [-40|210] "degC" Vector__XXX
 SG_ DCACAssrInvrtr3ClntInTmprtr : 24|8@1+ (1,-40) [-40|210] "degC" Vector__XXX
 SG_ DCACAssrInvrtr3ClntOtTmprtr : 32|8@1+ (1,-40) [-40|210] "degC" Vector__XXX
 SG_ DCACAssrInvrtr3CntrllrTmprtr : 0|8@1+ (1,-40) [-40|210] "degC" Vector__XXX
 SG_ DCACAssrInvrtr3PwrEltrnsTmprtr : 16|8@1+ (1,-40) [-40|210] "degC" Vector__XXX

BO_ 2566629118 DCACAI3CFG1: 13 Vector__XXX
 SG_ DCACAssIvt3ACSdDtFqCdStt : 96|8@1+ (1,0) [0|250] "Hz" Vector__XXX
 SG_ DCACAssIvt3ACSdRMSCtMxLtStt : 48|16@1+ (0.03125,0) [0|2007.96875] "A" Vector__XXX
 SG_ DCACAssIvt3ACSdRMSVtMxLtStt : 32|16@1+ (0.03125,0) [0|2007.96875] "V" Vector__XXX
 SG_ DCACAssIvt3DCSdCtMLtStt : 80|16@1+ (0.05,-3212.75) [-3212.75|0] "A" Vector__XXX
 SG_ DCACAssIvt3DCSdCtMxLtStt : 16|16@1+ (0.05,0) [0|3212.75] "A" Vector__XXX
 SG_ DCACAssIvt3DCSdVtMLtStt : 0|16@1+ (0.05,0) [0|3212.75] "V" Vector__XXX
 SG_ DCACAssIvt3DCSdVtMxLtStt : 64|16@1+ (0.05,0) [0|3212.75] "V" Vector__XXX

BO_ 2566629374 DCACAI3LD: 8 Vector__XXX
 SG_ DCACAssrInvrtr3TtlDCInptChrg : 0|32@1+ (100,0) [0|421108121500] "Ah" Vector__XXX
 SG_ DCACAssrInvrtr3TtlDCInptEnrg : 32|32@1+ (100,0) [0|421108121500] "Watt-hour" Vector__XXX

BO_ 2566629630 DCACAI4T: 8 Vector__XXX
 SG_ DCACAssIvt4IvtEtFtTpt : 8|8@1+ (1,-40) [-40|210] "degC" Vector__XXX
 SG_ DCACAssrInvrtr4ClntInTmprtr : 24|8@1+ (1,-40) [-40|210] "degC" Vector__XXX
 SG_ DCACAssrInvrtr4ClntOtTmprtr : 32|8@1+ (1,-40) [-40|210] "degC" Vector__XXX
 SG_ DCACAssrInvrtr4CntrllrTmprtr : 0|8@1+ (1,-40) [-40|210] "degC" Vector__XXX
 SG_ DCACAssrInvrtr4PwrEltrnsTmprtr : 16|8@1+ (1,-40) [-40|210] "degC" Vector__XXX

BO_ 2566630398 DCACAI4CFG1: 13 Vector__XXX
 SG_ DCACAssIvt4ACSdDtFqCdStt : 96|8@1+ (1,0) [0|250] "Hz" Vector__XXX
 SG_ DCACAssIvt4ACSdRMSCtMxLtStt : 48|16@1+ (0.03125,0) [0|2007.96875] "A" Vector__XXX
 SG_ DCACAssIvt4ACSdRMSVtMxLtStt : 32|16@1+ (0.03125,0) [0|2007.96875] "V" Vector__XXX
 SG_ DCACAssIvt4DCSdCtMLtStt : 80|16@1+ (0.05,-3212.75) [-3212.75|0] "A" Vector__XXX
 SG_ DCACAssIvt4DCSdCtMxLtStt : 16|16@1+ (0.05,0) [0|3212.75] "A" Vector__XXX
 SG_ DCACAssIvt4DCSdVtMLtStt : 0|16@1+ (0.05,0) [0|3212.75] "V" Vector__XXX
 SG_ DCACAssIvt4DCSdVtMxLtStt : 64|16@1+ (0.05,0) [0|3212.75] "V" Vector__XXX

BO_ 2566630654 DCACAI4LD: 8 Vector__XXX
 SG_ DCACAssrInvrtr4TtlDCInptChrg : 0|32@1+ (100,0) [0|421108121500] "Ah" Vector__XXX
 SG_ DCACAssrInvrtr4TtlDCInptEnrg : 32|32@1+ (100,0) [0|421108121500] "Watt-hour" Vector__XXX

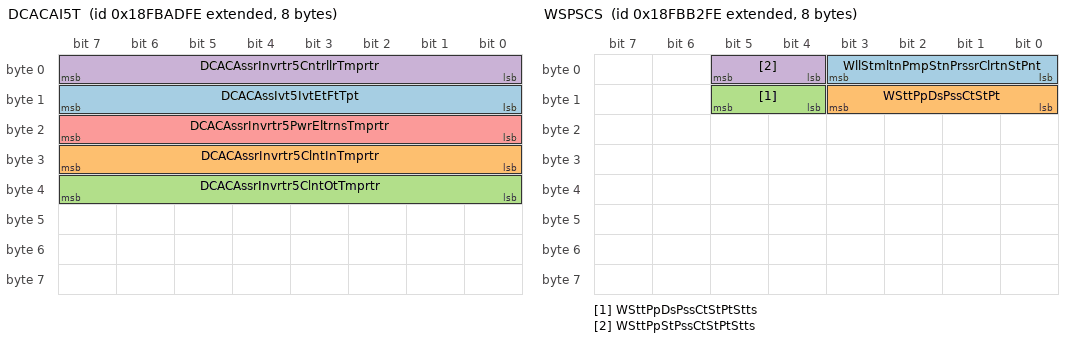
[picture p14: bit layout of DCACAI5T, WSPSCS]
BO_ 2566630910 DCACAI5T: 8 Vector__XXX
 SG_ DCACAssIvt5IvtEtFtTpt : 8|8@1+ (1,-40) [-40|210] "degC" Vector__XXX
 SG_ DCACAssrInvrtr5ClntInTmprtr : 24|8@1+ (1,-40) [-40|210] "degC" Vector__XXX
 SG_ DCACAssrInvrtr5ClntOtTmprtr : 32|8@1+ (1,-40) [-40|210] "degC" Vector__XXX
 SG_ DCACAssrInvrtr5CntrllrTmprtr : 0|8@1+ (1,-40) [-40|210] "degC" Vector__XXX
 SG_ DCACAssrInvrtr5PwrEltrnsTmprtr : 16|8@1+ (1,-40) [-40|210] "degC" Vector__XXX

BO_ 2566631678 DCACAI5CFG1: 13 Vector__XXX
 SG_ DCACAssIvt5ACSdDtFqCdStt : 96|8@1+ (1,0) [0|250] "Hz" Vector__XXX
 SG_ DCACAssIvt5ACSdRMSCtMxLtStt : 48|16@1+ (0.03125,0) [0|2007.96875] "A" Vector__XXX
 SG_ DCACAssIvt5ACSdRMSVtMxLtStt : 32|16@1+ (0.03125,0) [0|2007.96875] "V" Vector__XXX
 SG_ DCACAssIvt5DCSdCtMLtStt : 80|16@1+ (0.05,-3212.75) [-3212.75|0] "A" Vector__XXX
 SG_ DCACAssIvt5DCSdCtMxLtStt : 16|16@1+ (0.05,0) [0|3212.75] "A" Vector__XXX
 SG_ DCACAssIvt5DCSdVtMLtStt : 0|16@1+ (0.05,0) [0|3212.75] "V" Vector__XXX
 SG_ DCACAssIvt5DCSdVtMxLtStt : 64|16@1+ (0.05,0) [0|3212.75] "V" Vector__XXX

BO_ 2566631934 DCACAI5LD: 8 Vector__XXX
 SG_ DCACAssrInvrtr5TtlDCInptChrg : 0|32@1+ (100,0) [0|421108121500] "Ah" Vector__XXX
 SG_ DCACAssrInvrtr5TtlDCInptEnrg : 32|32@1+ (100,0) [0|421108121500] "Watt-hour" Vector__XXX

BO_ 2566632190 WSPSCS: 8 Vector__XXX
 SG_ WllStmltnPmpStnPrssrClrtnStPnt : 0|4@1+ (1,0) [0|15] "" Vector__XXX
 SG_ WSttPpDsPssCtStPt : 8|4@1+ (1,0) [0|15] "" Vector__XXX
 SG_ WSttPpDsPssCtStPtStts : 12|2@1+ (1,0) [0|3] "" Vector__XXX
 SG_ WSttPpStPssCtStPtStts : 4|2@1+ (1,0) [0|3] "" Vector__XXX

BO_ 2566632446 WSPFV: 8 Vector__XXX
 SG_ WllStmltnPmpTrpFldPmpd : 32|32@1+ (0.5,0) [0|2105540607.5] "l" Vector__XXX
 SG_ WllStmltnPmpTtlFldPmpd : 0|32@1+ (0.5,0) [0|2105540607.5] "l" Vector__XXX

BO_ 2566632702 WSPSN: 200 Vector__XXX
 SG_ WllStmltnPmpFldEndSrlNmr : 8|8@1+ (1,0) [0|255] "ASCII" Vector__XXX
 SG_ WllStmltnPmpPwrEndSrlNmr : 0|8@1+ (1,0) [0|255] "ASCII" Vector__XXX

BO_ 2566632958 WSPH2: 8 Vector__XXX
 SG_ WllStmltnPmpFldEndTrpHrs : 0|32@1+ (1,0) [0|4211081215] "s" Vector__XXX
 SG_ WllStmltnPmpPwrEndTrpHrs : 32|32@1+ (1,0) [0|4211081215] "s" Vector__XXX

BO_ 2566633214 AT1OG4: 8 Vector__XXX
 SG_ Aftrtrtmnt1OtltOxgnPmpngCrrnt : 0|16@1+ (0.001,-32.127) [-32.127|32.128] "mA" Vector__XXX
 SG_ Atttt1OttNOxSsPttAPssAst : 16|16@1+ (0.1,0) [0|6425.5] "kPa" Vector__XXX

BO_ 2566633470 AT1IG4: 8 Vector__XXX
 SG_ Aftrtrtmnt1IntkOxgnPmpngCrrnt : 0|16@1+ (0.001,-32.127) [-32.127|32.128] "mA" Vector__XXX
 SG_ Atttt1ItNOxSsPttAPssAst : 16|16@1+ (0.1,0) [0|6425.5] "kPa" Vector__XXX

BO_ 2566633726 DCDC4LD: 16 Vector__XXX
 SG_ DCDC4TotalHighSideCharge : 64|32@1+ (100,0) [0|421108121500] "Ah" Vector__XXX
 SG_ DCDC4TotalHighSideEnergy : 0|32@1+ (100,0) [0|421108121500] "Watt-hour" Vector__XXX
 SG_ DCDC4TotalLowSideCharge : 96|32@1+ (100,0) [0|421108121500] "Ah" Vector__XXX
 SG_ DCDC4TotalLowSideEnergy : 32|32@1+ (100,0) [0|421108121500] "Watt-hour" Vector__XXX

BO_ 2566633982 DCDC4CFG1: 19 Vector__XXX
 SG_ DCDC4HghSdCrrntMxmmLmtSttng : 32|16@1+ (0.05,0) [0|3212.75] "A" Vector__XXX
 SG_ DCDC4HghSdVltgMnmmLmtSttng : 0|16@1+ (0.05,0) [0|3212.75] "V" Vector__XXX
 SG_ DCDC4HghSdVltgMxmmLmtSttng : 16|16@1+ (0.05,0) [0|3212.75] "V" Vector__XXX
 SG_ DCDC4LwSdCrrntMxmmLmtSttng : 80|16@1+ (0.05,0) [0|3212.75] "A" Vector__XXX
 SG_ DCDC4LwSdVltgBkDfltSttng : 136|16@1+ (0.01,0) [0|642.55] "V" Vector__XXX
 SG_ DCDC4LwSdVltgMnmmLmtSttng : 48|16@1+ (0.01,0) [0|642.55] "V" Vector__XXX
 SG_ DCDC4LwSdVltgMxmmLmtSttng : 64|16@1+ (0.01,0) [0|642.55] "V" Vector__XXX
 SG_ DCDC4SLIBttrTmprtrMxmmLmtSttng : 128|8@1+ (1,-40) [-40|210] "degC" Vector__XXX
 SG_ DCDC4SLIBttTCCtMxLtStt : 112|16@1+ (0.05,0) [0|3212.75] "A" Vector__XXX
 SG_ DCDC4SLIBttTVtMxLtStt : 96|16@1+ (0.01,0) [0|642.55] "V" Vector__XXX

BO_ 2566635262 DCDC3LD: 16 Vector__XXX
 SG_ DCDC3TotalHighSideCharge : 64|32@1+ (100,0) [0|421108121500] "Ah" Vector__XXX
 SG_ DCDC3TotalHighSideEnergy : 0|32@1+ (100,0) [0|421108121500] "Watt-hour" Vector__XXX
 SG_ DCDC3TotalLowSideCharge : 96|32@1+ (100,0) [0|421108121500] "Ah" Vector__XXX
 SG_ DCDC3TotalLowSideEnergy : 32|32@1+ (100,0) [0|421108121500] "Watt-hour" Vector__XXX

BO_ 2566635518 DCDC3CFG1: 19 Vector__XXX
 SG_ DCDC3HghSdCrrntMxmmLmtSttng : 32|16@1+ (0.05,0) [0|3212.75] "A" Vector__XXX
 SG_ DCDC3HghSdVltgMnmmLmtSttng : 0|16@1+ (0.05,0) [0|3212.75] "V" Vector__XXX
 SG_ DCDC3HghSdVltgMxmmLmtSttng : 16|16@1+ (0.05,0) [0|3212.75] "V" Vector__XXX
 SG_ DCDC3LwSdCrrntMxmmLmtSttng : 80|16@1+ (0.05,0) [0|3212.75] "A" Vector__XXX
 SG_ DCDC3LwSdVltgBkDfltSttng : 136|16@1+ (0.01,0) [0|642.55] "V" Vector__XXX
 SG_ DCDC3LwSdVltgMnmmLmtSttng : 48|16@1+ (0.01,0) [0|642.55] "V" Vector__XXX
 SG_ DCDC3LwSdVltgMxmmLmtSttng : 64|16@1+ (0.01,0) [0|642.55] "V" Vector__XXX
 SG_ DCDC3SLIBttrTmprtrMxmmLmtSttng : 128|8@1+ (1,-40) [-40|210] "degC" Vector__XXX
 SG_ DCDC3SLIBttTCCtMxLtStt : 112|16@1+ (0.05,0) [0|3212.75] "A" Vector__XXX
 SG_ DCDC3SLIBttTVtMxLtStt : 96|16@1+ (0.01,0) [0|642.55] "V" Vector__XXX

BO_ 2566636798 DCDC2LD: 16 Vector__XXX
 SG_ DCDC2TotalHighSideCharge : 64|32@1+ (100,0) [0|421108121500] "Ah" Vector__XXX
 SG_ DCDC2TotalHighSideEnergy : 0|32@1+ (100,0) [0|421108121500] "Watt-hour" Vector__XXX
 SG_ DCDC2TotalLowSideCharge : 96|32@1+ (100,0) [0|421108121500] "Ah" Vector__XXX
 SG_ DCDC2TotalLowSideEnergy : 32|32@1+ (100,0) [0|421108121500] "Watt-hour" Vector__XXX

BO_ 2566637054 DCDC2CFG1: 19 Vector__XXX
 SG_ DCDC2HghSdCrrntMxmmLmtSttng : 32|16@1+ (0.05,0) [0|3212.75] "A" Vector__XXX
 SG_ DCDC2HghSdVltgMnmmLmtSttng : 0|16@1+ (0.05,0) [0|3212.75] "V" Vector__XXX
 SG_ DCDC2HghSdVltgMxmmLmtSttng : 16|16@1+ (0.05,0) [0|3212.75] "V" Vector__XXX
 SG_ DCDC2LwSdCrrntMxmmLmtSttng : 80|16@1+ (0.05,0) [0|3212.75] "A" Vector__XXX
 SG_ DCDC2LwSdVltgBkDfltSttng : 136|16@1+ (0.01,0) [0|642.55] "V" Vector__XXX
 SG_ DCDC2LwSdVltgMnmmLmtSttng : 48|16@1+ (0.01,0) [0|642.55] "V" Vector__XXX
 SG_ DCDC2LwSdVltgMxmmLmtSttng : 64|16@1+ (0.01,0) [0|642.55] "V" Vector__XXX
 SG_ DCDC2SLIBttrTmprtrMxmmLmtSttng : 128|8@1+ (1,-40) [-40|210] "degC" Vector__XXX
 SG_ DCDC2SLIBttTCCtMxLtStt : 112|16@1+ (0.05,0) [0|3212.75] "A" Vector__XXX
 SG_ DCDC2SLIBttTVtMxLtStt : 96|16@1+ (0.01,0) [0|642.55] "V" Vector__XXX

BO_ 2566638590 EEPCSI: 8 Vector__XXX
 SG_ ExhstPrtltCntrlSstmDgnstCnt : 32|32@1+ (1,0) [0|4211081215] "count" Vector__XXX
 SG_ ExhstPrtltCntrlSstmDgnstTm : 0|32@1+ (1,0) [0|4211081215] "s" Vector__XXX

BO_ 2566638846 WSPH: 16 Vector__XXX
 SG_ WllStmltnPmpMntnnIntrvlHrs : 0|32@1+ (1,0) [0|4211081215] "s" Vector__XXX
 SG_ WllStmltnPmpPkngOprtnHrs : 64|32@1+ (1,0) [0|4211081215] "s" Vector__XXX
 SG_ WllStmltnPmpVlvOprtnHrs : 32|32@1+ (1,0) [0|4211081215] "s" Vector__XXX
 SG_ WllStmltnPmpVlvStOprtnHrs : 96|32@1+ (1,0) [0|4211081215] "s" Vector__XXX

BO_ 2566639102 WSPT2: 19 Vector__XXX
 SG_ WllStmltnPmpPlngrFrngOrdrSttng : 144|4@1+ (1,0) [0|15] "" Vector__XXX
 SG_ WllStmltnPmpRdLdHghThrshldSttng : 128|16@1+ (5,0) [0|321275] "kN" Vector__XXX
 SG_ WSttPpCstSpdHTsdStt : 112|16@1+ (0.125,0) [0|8031.875] "rpm" Vector__XXX
 SG_ WSttPpCstSpdLwTsdStt : 96|16@1+ (0.125,0) [0|8031.875] "rpm" Vector__XXX
 SG_ WSttPpDsPssHTsdStt : 80|16@1+ (5,0) [0|321275] "kPa" Vector__XXX
 SG_ WSttPpGBxOPssHTsdStt : 16|16@1+ (0.1,0) [0|6425.5] "kPa" Vector__XXX
 SG_ WSttPpGBxOPssLwTsdStt : 0|16@1+ (0.1,0) [0|6425.5] "kPa" Vector__XXX
 SG_ WSttPpGBxOTptHTsdStt : 40|8@1+ (1,-40) [-40|210] "degC" Vector__XXX
 SG_ WSttPpGBxOTptLwTsdStt : 32|8@1+ (1,-40) [-40|210] "degC" Vector__XXX
 SG_ WSttPpStPssHTsdStt : 64|16@1+ (0.1,-3212.7) [-3212.7|3212.8] "kPa" Vector__XXX
 SG_ WSttPpStPssLwTsdStt : 48|16@1+ (0.1,-3212.7) [-3212.7|3212.8] "kPa" Vector__XXX

BO_ 2566639614 DCDC1LD: 16 Vector__XXX
 SG_ DCDC1TotalHighSideCharge : 64|32@1+ (100,0) [0|421108121500] "Ah" Vector__XXX
 SG_ DCDC1TotalHighSideEnergy : 0|32@1+ (100,0) [0|421108121500] "Watt-hour" Vector__XXX
 SG_ DCDC1TotalLowSideCharge : 96|32@1+ (100,0) [0|421108121500] "Ah" Vector__XXX
 SG_ DCDC1TotalLowSideEnergy : 32|32@1+ (100,0) [0|421108121500] "Watt-hour" Vector__XXX

BO_ 2566639870 DCDC1CFG1: 19 Vector__XXX
 SG_ DCDC1HghSdCrrntMxmmLmtSttng : 32|16@1+ (0.05,0) [0|3212.75] "A" Vector__XXX
 SG_ DCDC1HghSdVltgMnmmLmtSttng : 0|16@1+ (0.05,0) [0|3212.75] "V" Vector__XXX
 SG_ DCDC1HghSdVltgMxmmLmtSttng : 16|16@1+ (0.05,0) [0|3212.75] "V" Vector__XXX
 SG_ DCDC1LwSdCrrntMxmmLmtSttng : 80|16@1+ (0.05,0) [0|3212.75] "A" Vector__XXX
 SG_ DCDC1LwSdVltgBkDfltSttng : 136|16@1+ (0.01,0) [0|642.55] "V" Vector__XXX
 SG_ DCDC1LwSdVltgMnmmLmtSttng : 48|16@1+ (0.01,0) [0|642.55] "V" Vector__XXX
 SG_ DCDC1LwSdVltgMxmmLmtSttng : 64|16@1+ (0.01,0) [0|642.55] "V" Vector__XXX
 SG_ DCDC1SLIBttrTmprtrMxmmLmtSttng : 128|8@1+ (1,-40) [-40|210] "degC" Vector__XXX
 SG_ DCDC1SLIBttTCCtMxLtStt : 112|16@1+ (0.05,0) [0|3212.75] "A" Vector__XXX
 SG_ DCDC1SLIBttTVtMxLtStt : 96|16@1+ (0.01,0) [0|642.55] "V" Vector__XXX

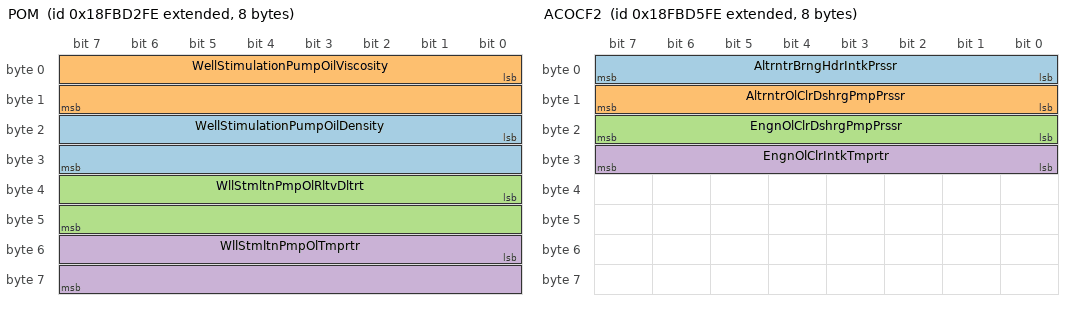
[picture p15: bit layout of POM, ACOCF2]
BO_ 2566640382 POM: 8 Vector__XXX
 SG_ WellStimulationPumpOilDensity : 16|16@1+ (0.00003052,0) [0|1.961] "g/cc" Vector__XXX
 SG_ WellStimulationPumpOilViscosity : 0|16@1+ (0.015625,0) [0|1003.984375] "Cp" Vector__XXX
 SG_ WllStmltnPmpOlRltvDltrt : 32|16@1+ (0.0001220703125,0) [0|7.844] "" Vector__XXX
 SG_ WllStmltnPmpOlTmprtr : 48|16@1+ (0.03125,-273) [-273|1734.96875] "degC" Vector__XXX

BO_ 2566641150 ACOCF2: 8 Vector__XXX
 SG_ AltrntrBrngHdrIntkPrssr : 0|8@1+ (2,0) [0|500] "kPa" Vector__XXX
 SG_ AltrntrOlClrDshrgPmpPrssr : 8|8@1+ (2,0) [0|500] "kPa" Vector__XXX
 SG_ EngnOlClrDshrgPmpPrssr : 16|8@1+ (2,0) [0|500] "kPa" Vector__XXX
 SG_ EngnOlClrIntkTmprtr : 24|8@1+ (1,-40) [-40|210] "degC" Vector__XXX

BO_ 2566641406 EEC21: 8 Vector__XXX
 SG_ EngnExhstMnfldAsltPrssr1 : 0|16@1+ (0.1,0) [0|6425.5] "kPa" Vector__XXX
 SG_ EngnExhstMnfldAsltPrssr2 : 16|16@1+ (0.1,0) [0|6425.5] "kPa" Vector__XXX

BO_ 2566642942 DC4: 8 Vector__XXX
 SG_ EnableStatusofDoor21 : 4|2@1+ (1,0) [0|3] "" Vector__XXX
 SG_ EnableStatusofDoor22 : 10|2@1+ (1,0) [0|3] "" Vector__XXX
 SG_ EnableStatusofDoor23 : 16|2@1+ (1,0) [0|3] "" Vector__XXX
 SG_ EnableStatusofDoor24 : 22|2@1+ (1,0) [0|3] "" Vector__XXX
 SG_ EnableStatusofDoor25 : 28|2@1+ (1,0) [0|3] "" Vector__XXX
 SG_ EnableStatusofDoor26 : 34|2@1+ (1,0) [0|3] "" Vector__XXX
 SG_ EnableStatusofDoor27 : 40|2@1+ (1,0) [0|3] "" Vector__XXX
 SG_ EnableStatusofDoor28 : 46|2@1+ (1,0) [0|3] "" Vector__XXX
 SG_ EnableStatusofDoor29 : 52|2@1+ (1,0) [0|3] "" Vector__XXX
 SG_ EnableStatusofDoor30 : 58|2@1+ (1,0) [0|3] "" Vector__XXX
 SG_ LockStatusofDoor21 : 0|2@1+ (1,0) [0|3] "" Vector__XXX
 SG_ LockStatusofDoor22 : 6|2@1+ (1,0) [0|3] "" Vector__XXX
 SG_ LockStatusofDoor23 : 12|2@1+ (1,0) [0|3] "" Vector__XXX
 SG_ LockStatusofDoor24 : 18|2@1+ (1,0) [0|3] "" Vector__XXX
 SG_ LockStatusofDoor25 : 24|2@1+ (1,0) [0|3] "" Vector__XXX
 SG_ LockStatusofDoor26 : 30|2@1+ (1,0) [0|3] "" Vector__XXX
 SG_ LockStatusofDoor27 : 36|2@1+ (1,0) [0|3] "" Vector__XXX
 SG_ LockStatusofDoor28 : 42|2@1+ (1,0) [0|3] "" Vector__XXX
 SG_ LockStatusofDoor29 : 48|2@1+ (1,0) [0|3] "" Vector__XXX
 SG_ LockStatusofDoor30 : 54|2@1+ (1,0) [0|3] "" Vector__XXX
 SG_ OpenStatusofDoor21 : 2|2@1+ (1,0) [0|3] "" Vector__XXX
 SG_ OpenStatusofDoor22 : 8|2@1+ (1,0) [0|3] "" Vector__XXX
 SG_ OpenStatusofDoor23 : 14|2@1+ (1,0) [0|3] "" Vector__XXX
 SG_ OpenStatusofDoor24 : 20|2@1+ (1,0) [0|3] "" Vector__XXX
 SG_ OpenStatusofDoor25 : 26|2@1+ (1,0) [0|3] "" Vector__XXX
 SG_ OpenStatusofDoor26 : 32|2@1+ (1,0) [0|3] "" Vector__XXX
 SG_ OpenStatusofDoor27 : 38|2@1+ (1,0) [0|3] "" Vector__XXX
 SG_ OpenStatusofDoor28 : 44|2@1+ (1,0) [0|3] "" Vector__XXX
 SG_ OpenStatusofDoor29 : 50|2@1+ (1,0) [0|3] "" Vector__XXX
 SG_ OpenStatusofDoor30 : 56|2@1+ (1,0) [0|3] "" Vector__XXX

BO_ 2566643198 DC3: 8 Vector__XXX
 SG_ EnableStatusofDoor11 : 4|2@1+ (1,0) [0|3] "" Vector__XXX
 SG_ EnableStatusofDoor12 : 10|2@1+ (1,0) [0|3] "" Vector__XXX
 SG_ EnableStatusofDoor13 : 16|2@1+ (1,0) [0|3] "" Vector__XXX
 SG_ EnableStatusofDoor14 : 22|2@1+ (1,0) [0|3] "" Vector__XXX
 SG_ EnableStatusofDoor15 : 28|2@1+ (1,0) [0|3] "" Vector__XXX
 SG_ EnableStatusofDoor16 : 34|2@1+ (1,0) [0|3] "" Vector__XXX
 SG_ EnableStatusofDoor17 : 40|2@1+ (1,0) [0|3] "" Vector__XXX
 SG_ EnableStatusofDoor18 : 46|2@1+ (1,0) [0|3] "" Vector__XXX
 SG_ EnableStatusofDoor19 : 52|2@1+ (1,0) [0|3] "" Vector__XXX
 SG_ EnableStatusofDoor20 : 58|2@1+ (1,0) [0|3] "" Vector__XXX
 SG_ LockStatusofDoor11 : 0|2@1+ (1,0) [0|3] "" Vector__XXX
 SG_ LockStatusofDoor12 : 6|2@1+ (1,0) [0|3] "" Vector__XXX
 SG_ LockStatusofDoor13 : 12|2@1+ (1,0) [0|3] "" Vector__XXX
 SG_ LockStatusofDoor14 : 18|2@1+ (1,0) [0|3] "" Vector__XXX
 SG_ LockStatusofDoor15 : 24|2@1+ (1,0) [0|3] "" Vector__XXX
 SG_ LockStatusofDoor16 : 30|2@1+ (1,0) [0|3] "" Vector__XXX
 SG_ LockStatusofDoor17 : 36|2@1+ (1,0) [0|3] "" Vector__XXX
 SG_ LockStatusofDoor18 : 42|2@1+ (1,0) [0|3] "" Vector__XXX
 SG_ LockStatusofDoor19 : 48|2@1+ (1,0) [0|3] "" Vector__XXX
 SG_ LockStatusofDoor20 : 54|2@1+ (1,0) [0|3] "" Vector__XXX
 SG_ OpenStatusofDoor11 : 2|2@1+ (1,0) [0|3] "" Vector__XXX
 SG_ OpenStatusofDoor12 : 8|2@1+ (1,0) [0|3] "" Vector__XXX
 SG_ OpenStatusofDoor13 : 14|2@1+ (1,0) [0|3] "" Vector__XXX
 SG_ OpenStatusofDoor14 : 20|2@1+ (1,0) [0|3] "" Vector__XXX
 SG_ OpenStatusofDoor15 : 26|2@1+ (1,0) [0|3] "" Vector__XXX
 SG_ OpenStatusofDoor16 : 32|2@1+ (1,0) [0|3] "" Vector__XXX
 SG_ OpenStatusofDoor17 : 38|2@1+ (1,0) [0|3] "" Vector__XXX
 SG_ OpenStatusofDoor18 : 44|2@1+ (1,0) [0|3] "" Vector__XXX
 SG_ OpenStatusofDoor19 : 50|2@1+ (1,0) [0|3] "" Vector__XXX
 SG_ OpenStatusofDoor20 : 56|2@1+ (1,0) [0|3] "" Vector__XXX

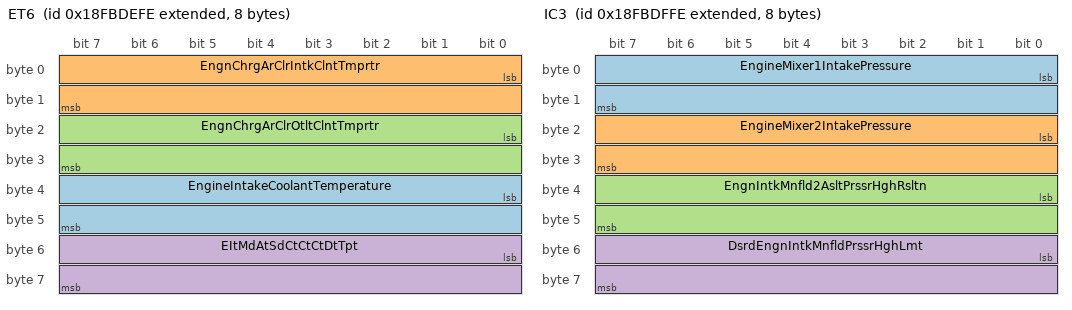
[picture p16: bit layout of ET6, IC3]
BO_ 2566643454 ET6: 8 Vector__XXX
 SG_ EngineIntakeCoolantTemperature : 32|16@1+ (0.03125,-273) [-273|1734.96875] "degC" Vector__XXX
 SG_ EngnChrgArClrIntkClntTmprtr : 0|16@1+ (0.03125,-273) [-273|1734.96875] "degC" Vector__XXX
 SG_ EngnChrgArClrOtltClntTmprtr : 16|16@1+ (0.03125,-273) [-273|1734.96875] "degC" Vector__XXX
 SG_ EItMdAtSdCtCtCtDtTpt : 48|16@1+ (0.03125,-273) [-273|1734.96875] "degC" Vector__XXX

BO_ 2566643710 IC3: 8 Vector__XXX
 SG_ EngineMixer1IntakePressure : 0|16@1+ (0.1,0) [0|6425.5] "kPa" Vector__XXX
 SG_ EngineMixer2IntakePressure : 16|16@1+ (0.1,0) [0|6425.5] "kPa" Vector__XXX
 SG_ EngnIntkMnfld2AsltPrssrHghRsltn : 32|16@1+ (0.1,0) [0|6425.5] "kPa" Vector__XXX
 SG_ DsrdEngnIntkMnfldPrssrHghLmt : 48|16@1+ (0.1,0) [0|6425.5] "kPa" Vector__XXX

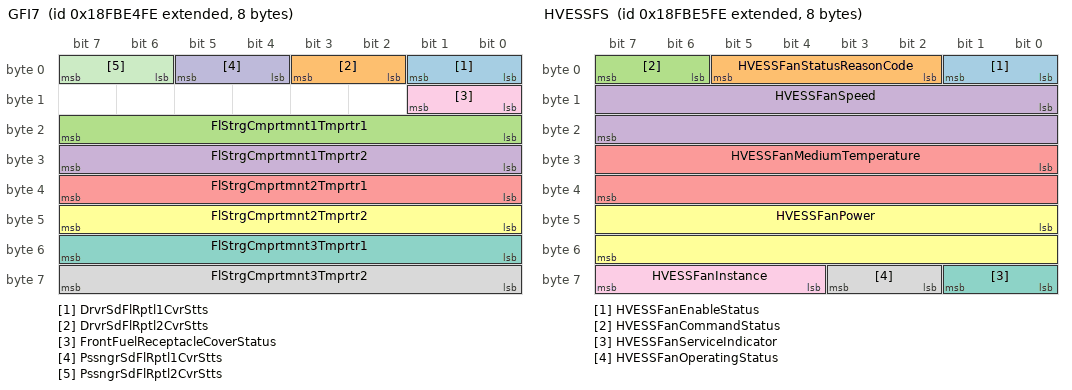
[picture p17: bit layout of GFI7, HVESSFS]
BO_ 2566644990 GFI7: 8 Vector__XXX
 SG_ DrvrSdFlRptl1CvrStts : 0|2@1+ (1,0) [0|3] "" Vector__XXX
 SG_ DrvrSdFlRptl2CvrStts : 2|2@1+ (1,0) [0|3] "" Vector__XXX
 SG_ FlStrgCmprtmnt1Tmprtr1 : 16|8@1+ (1,-40) [-40|210] "degC" Vector__XXX
 SG_ FlStrgCmprtmnt1Tmprtr2 : 24|8@1+ (1,-40) [-40|210] "degC" Vector__XXX
 SG_ FlStrgCmprtmnt2Tmprtr1 : 32|8@1+ (1,-40) [-40|210] "degC" Vector__XXX
 SG_ FlStrgCmprtmnt2Tmprtr2 : 40|8@1+ (1,-40) [-40|210] "degC" Vector__XXX
 SG_ FlStrgCmprtmnt3Tmprtr1 : 48|8@1+ (1,-40) [-40|210] "degC" Vector__XXX
 SG_ FlStrgCmprtmnt3Tmprtr2 : 56|8@1+ (1,-40) [-40|210] "degC" Vector__XXX
 SG_ FrontFuelReceptacleCoverStatus : 8|2@1+ (1,0) [0|3] "" Vector__XXX
 SG_ PssngrSdFlRptl1CvrStts : 4|2@1+ (1,0) [0|3] "" Vector__XXX
 SG_ PssngrSdFlRptl2CvrStts : 6|2@1+ (1,0) [0|3] "" Vector__XXX

BO_ 2566645246 HVESSFS: 8 Vector__XXX
 SG_ HVESSFanEnableStatus : 0|2@1+ (1,0) [0|3] "" Vector__XXX
 SG_ HVESSFanStatusReasonCode : 2|4@1+ (1,0) [0|15] "" Vector__XXX
 SG_ HVESSFanCommandStatus : 6|2@1+ (1,0) [0|3] "" Vector__XXX
 SG_ HVESSFanSpeed : 8|16@1+ (0.5,0) [0|32127.5] "rpm" Vector__XXX
 SG_ HVESSFanMediumTemperature : 24|16@1+ (0.03125,-273) [-273|1734.96875] "degC" Vector__XXX
 SG_ HVESSFanPower : 40|16@1+ (0.5,0) [0|32127.5] "W" Vector__XXX
 SG_ HVESSFanServiceIndicator : 56|2@1+ (1,0) [0|3] "" Vector__XXX
 SG_ HVESSFanOperatingStatus : 58|2@1+ (1,0) [0|3] "" Vector__XXX
 SG_ HVESSFanInstance : 60|4@1+ (1,0) [0|15] "" Vector__XXX

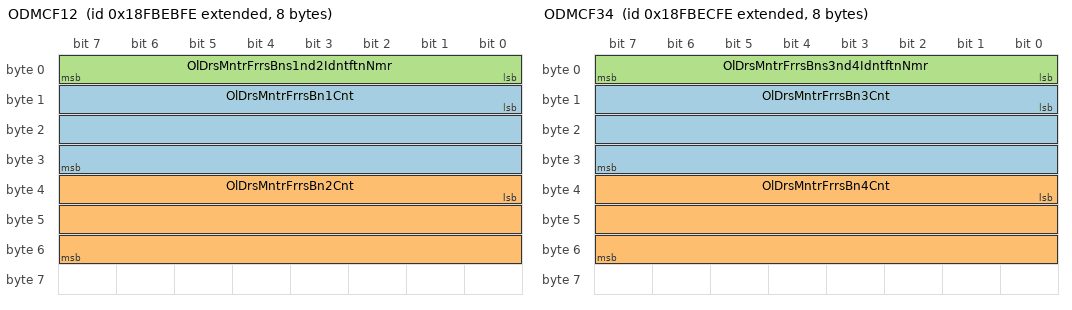
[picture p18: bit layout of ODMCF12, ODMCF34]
BO_ 2566646782 ODMCF12: 8 Vector__XXX
 SG_ OlDrsMntrFrrsBn1Cnt : 8|24@1+ (1,0) [0|16449535] "count" Vector__XXX
 SG_ OlDrsMntrFrrsBn2Cnt : 32|24@1+ (1,0) [0|16449535] "count" Vector__XXX
 SG_ OlDrsMntrFrrsBns1nd2IdntftnNmr : 0|8@1+ (1,0) [0|250] "count" Vector__XXX

BO_ 2566647038 ODMCF34: 8 Vector__XXX
 SG_ OlDrsMntrFrrsBn3Cnt : 8|24@1+ (1,0) [0|16449535] "count" Vector__XXX
 SG_ OlDrsMntrFrrsBn4Cnt : 32|24@1+ (1,0) [0|16449535] "count" Vector__XXX
 SG_ OlDrsMntrFrrsBns3nd4IdntftnNmr : 0|8@1+ (1,0) [0|250] "count" Vector__XXX

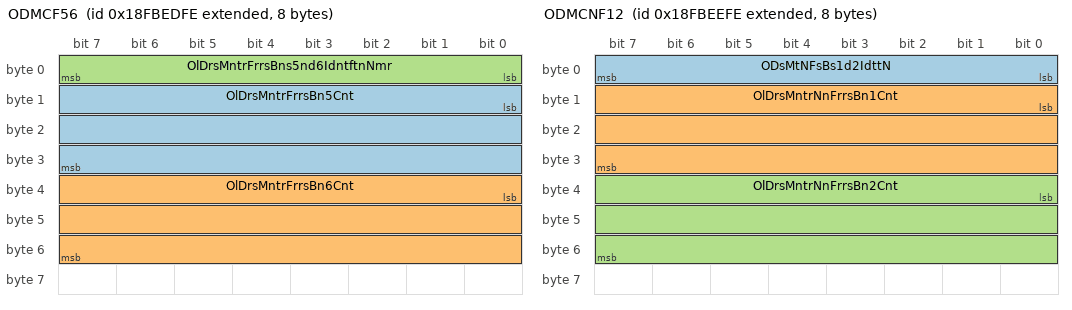
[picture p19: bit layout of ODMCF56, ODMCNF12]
BO_ 2566647294 ODMCF56: 8 Vector__XXX
 SG_ OlDrsMntrFrrsBn5Cnt : 8|24@1+ (1,0) [0|16449535] "count" Vector__XXX
 SG_ OlDrsMntrFrrsBn6Cnt : 32|24@1+ (1,0) [0|16449535] "count" Vector__XXX
 SG_ OlDrsMntrFrrsBns5nd6IdntftnNmr : 0|8@1+ (1,0) [0|250] "count" Vector__XXX

BO_ 2566647550 ODMCNF12: 8 Vector__XXX
 SG_ ODsMtNFsBs1d2IdttN : 0|8@1+ (1,0) [0|250] "count" Vector__XXX
 SG_ OlDrsMntrNnFrrsBn1Cnt : 8|24@1+ (1,0) [0|16449535] "count" Vector__XXX
 SG_ OlDrsMntrNnFrrsBn2Cnt : 32|24@1+ (1,0) [0|16449535] "count" Vector__XXX

BO_ 2566647806 ODMCNF34: 8 Vector__XXX
 SG_ ODsMtNFsBs3d4IdttN : 0|8@1+ (1,0) [0|250] "count" Vector__XXX
 SG_ OlDrsMntrNnFrrsBn3Cnt : 8|24@1+ (1,0) [0|16449535] "count" Vector__XXX
 SG_ OlDrsMntrNnFrrsBn4Cnt : 32|24@1+ (1,0) [0|16449535] "count" Vector__XXX

BO_ 2566648062 ODMCNF56: 8 Vector__XXX
 SG_ ODsMtNFsBs5d6IdttN : 0|8@1+ (1,0) [0|250] "count" Vector__XXX
 SG_ OlDrsMntrNnFrrsBn5Cnt : 8|24@1+ (1,0) [0|16449535] "count" Vector__XXX
 SG_ OlDrsMntrNnFrrsBn6Cnt : 32|24@1+ (1,0) [0|16449535] "count" Vector__XXX

CM_ BO_ 2565873150 "Steering Angle Sensor Information";
CM_ SG_ 2565873150 MessageChecksum "Message Checksum: The message checksum is used to verify the signal path from the demanding device to the steering controller.  The support of this parameter is mandatory if PGN 61469 is supported as there is no means to indicate not available.The 4 ...";
CM_ SG_ 2565873150 MessageCounter "Message Counter: The message counter is to verify the signal path from the demanding device to the steering controller.  The support of this parameter is mandatory.Note:  The initial value of the 4 bit message counter for the first message during a d...";
CM_ SG_ 2565873150 SteeringAngleSensorActiveMode "Steering Angle Sensor Active Mode: This signal indicates the operational mode of the steering angle sensor.00b = Programming mode active01b = Normal mode active10b = Reserved11b = Not available";
CM_ SG_ 2565873150 SteeringAngleSensorCalibrated "Steering Angle Sensor Calibrated: This signal indicates the calibration status of the steering angle sensor.00b = SAS not calibrated01b = SAS calibrated10b = Reserved11b = Not available";
CM_ SG_ 2565873150 SteeringWheelAngle "Steering Wheel Angle: The main operator`s steering wheel angle (on the steering column, not the actual wheel angle). The vehicle being steered to the left (counterclockwise) results in a positive steering wheel angle.  This is the yaw angle of the st...";
CM_ SG_ 2565873150 SteeringWheelAngleRange "Steering Wheel Angle Range: The signal indicates the range of  the steering wheel angle the sensor element is capable to measure. The steering wheel angle signal ranges between the negative and the positive value of the steering wheel angle range.For...";
CM_ SG_ 2565873150 SteeringWheelAngleRangeCounter "Steering Wheel Angle Range Counter: The signal indicates the number of steering wheel angle range overflows if the operating range of steering wheel is greater than the measuring range of sensor element. Positive values indicate left turns (countercl...";
CM_ SG_ 2565873150 StrngWhlAnglRngCntrTp "Steering Wheel Angle Range Counter Type: The signal indicates whether the steering wheel angle sensor is capable of absolute measuring of the number of steering wheel angle ranges or not.  Absolute measuring means that the steering wheel angle range ...";
CM_ BO_ 2565874174 "Engine Speed Sensor Information 1";
CM_ SG_ 2565874174 EngineSpeed1 "Engine Speed 1: The engine speed as measured by speed sensor 1.Note:  This is for the engine speed from the 1st engine speed sensor.  This may be different than SPN 190 when used in multiple engine speed sensor configurations.   In an application wit...";
CM_ SG_ 2565874174 EngineSpeed2 "Engine Speed 2: The engine speed as measured by speed sensor 2Note:  This is for the engine speed from the 2nd engine speed sensor.  This may be different than SPN 190 when used in multiple engine speed sensor configurations.   In an application with...";
CM_ SG_ 2565874174 EngineSpeed3 "Engine Speed 3: The engine speed as measured by speed sensor 3.Note:  This is for the engine speed from the 3rd engine speed sensor.  This may be different than SPN 190 when used in multiple engine speed sensor configurations.   In an application wit...";
CM_ SG_ 2565874174 EngnSpdSnsr1TmngPttrnStts "Engine Speed Sensor 1 Timing Pattern Status: This is the timing pattern status of the engine speed sensor signal for sensor 1.   The sensor may be sending a speed signal but the pattern may not be valid.  Since the speed is considered valid, the erro...";
CM_ SG_ 2565874174 EngnSpdSnsr2TmngPttrnStts "Engine Speed Sensor 2 Timing Pattern Status: This is the timing pattern status of the engine speed sensor signal for sensor 2.  The sensor may be sending a speed signal but the pattern may not be valid.  Since the speed is considered valid, the error...";
CM_ SG_ 2565874174 EngnSpdSnsr3TmngPttrnStts "Engine Speed Sensor 3 Timing Pattern Status: This is the timing pattern status of the engine speed sensor signal for sensor 3.  The sensor may be sending a speed signal but the pattern may not be valid.  Since the speed is considered valid, the error...";
CM_ BO_ 2565877502 "Engine Turbocharger Control";
CM_ SG_ 2565877502 EExstB1PssRtCtCd "Engine Exhaust Bank 1 Pressure Regulator Control Command: The control command to the Engine Exhaust Pressure Regulator in bank 1, normalized to percent.  100 percent means the regulator is fully closed, providing the maximum restriction to exhaust ga...";
CM_ SG_ 2565877502 EngnTrhrgrWstgtAttr1Cmmnd "Engine Turbocharger Wastegate Actuator 1 Command: The command to a Turbocharger Wastegate actuator 1, normalized to percent, where 0% nominally represents fully closed (No Flow) and 100% represents fully open (Max Flow).FB00h - FB64h is sent to calib...";
CM_ SG_ 2565877502 EngnTrhrgrWstgtAttr2Cmmnd "Engine Turbocharger Wastegate Actuator 2 Command: The command to a Turbocharger Wastegate actuator 2, normalized to percent, where 0% nominally represents fully closed (No Flow) and 100% represents fully open (Max Flow).";
CM_ SG_ 2565877502 ETCpssBwAtt1Cd "Engine Turbocharger Compressor Blowoff Actuator 1 Command: The command to blow off actuator 1, normalized to percent, where 0% nominally represents fully closed (No Flow) and 100% represents fully open (Max Flow). The purpose of Blow-off value is sim...";
CM_ BO_ 2565917438 "DC/AC Accessory Inverter 1 Feedback 2";
CM_ SG_ 2565917438 DCACAssIvt1PwLtddtACSdRMSCt "DC/AC Accessory Inverter 1 Power Limited due to AC Side RMS Current: AC Side Output power is being limited due to AC Side output RMS current (see SPN 9200) approaching or exceeding the maximum limit (See SPN 9228).00b = No power limit for this reason...";
CM_ SG_ 2565917438 DCACAssIvt1PwLtddtCtTpt "DC/AC Accessory Inverter 1 Power Limited due to Controller Temperature: Output power is being limited due to the controller temperature (see SPN 9204) approaching or exceeding the maximum limit.00b = No power limit for this reason01b = Power limited ...";
CM_ SG_ 2565917438 DCACAssIvt1PwLtddtDCSdCt "DC/AC Accessory Inverter 1 Power Limited due to DC Side Current: Output power is being limited due to DC Side input current (see SPN 8891) approaching or exceeding the maximum limit (See SPN 9226).00b = No power limit for this reason01b = Power limit...";
CM_ SG_ 2565917438 DCACAssIvt1PwLtddtDCSdVtM "DC/AC Accessory Inverter 1 Power Limited due to DC Side Voltage Minimum: Output power is being limited due to DC Side input voltage (see SPN 8890) approaching or falling below the minimum limit (SPN 9225).00b = No power limit for this reason01b = Pow...";
CM_ SG_ 2565917438 DCACAssIvt1PwLtddtEtFtTpt "DC/AC Accessory Inverter 1 Power Limited due to Electronic Filter Temperature: Output power is being limited due to electronic filter temperature (see SPN 9205) approaching or exceeding the maximum limit.00b = No power limit for this reason01b = Powe...";
CM_ SG_ 2565917438 DCACAssIvt1PwLtddtPwEtsTpt "DC/AC Accessory Inverter 1 Power Limited due to Power Electronics Temperature: Output power is being limited due to power electronics temperature (see SPN 9206) approaching or exceeding the maximum limit.00b = No power limit for this reason01b = Powe...";
CM_ SG_ 2565917438 DCACAssIvt1PwLtddtRtCLt "DC/AC Accessory Inverter 1 Power Limited due to Rate of Change Limit: Output power is being limited due to the frequency approaching or exceeding the rate of change limit (see SPN 8332).00b = No power limit for this reason01b = Power limited for this...";
CM_ SG_ 2565917438 DCACAssIvt1PwLtddtUddRs "DC/AC Accessory Inverter 1 Power Limited due to Undefined Reason: Output power is being limited due to an undefined reason.00b = No power limit for this reason01b = Power limited for this reason10b = Error11b = Not Available";
CM_ SG_ 2565917438 DCACAssrInvrtr1FrqnCmmndlwMnmm "DC/AC Accessory Inverter 1 Frequency Command below Minimum: Output frequency is being limited due to frequency command (see SPN 8333) approaching or falling below the minimum limit (SPN 8329).00b = No frequency limit for this reason01b = Frequency li...";
CM_ SG_ 2565917438 DCACAssrInvrtr1FrqnCmmndxdsMxmm "DC/AC Accessory Inverter 1 Frequency Command exceeds Maximum: Output frequency is being limited due to frequency command (see SPN 8333) approaching or exceeding the maximum limit (SPN 8328).00b = No frequency limit for this reason01b = Frequency limi...";
CM_ BO_ 2565918206 "DC/AC Accessory Inverter 2 Feedback 2";
CM_ SG_ 2565918206 DCACAssIvt2PwLtddtACSdRMSCt "DC/AC Accessory Inverter 2 Power Limited due to AC Side RMS Current: AC Side Output power is being limited due to AC Side output RMS current (see SPN 9201) approaching or exceeding the maximum limit (See SPN 9258).00b = No power limit for this reason...";
CM_ SG_ 2565918206 DCACAssIvt2PwLtddtCtTpt "DC/AC Accessory Inverter 2 Power Limited due to Controller Temperature: Output power is being limited due to the controller temperature (see SPN 9231) approaching or exceeding the maximum limit.00b = No power limit for this reason01b = Power limited ...";
CM_ SG_ 2565918206 DCACAssIvt2PwLtddtDCSdCt "DC/AC Accessory Inverter 2 Power Limited due to DC Side Current: Output power is being limited due to DC Side input current (see SPN 9238) approaching or exceeding the maximum limit (See SPN 9256).00b = No power limit for this reason01b = Power limit...";
CM_ SG_ 2565918206 DCACAssIvt2PwLtddtDCSdVtM "DC/AC Accessory Inverter 2 Power Limited due to DC Side Voltage Minimum: Output power is being limited due to DC Side input voltage (see SPN 9237) approaching or falling below the minimum limit (SPN 9255).00b = No power limit for this reason01b = Pow...";
CM_ SG_ 2565918206 DCACAssIvt2PwLtddtEtFtTpt "DC/AC Accessory Inverter 2 Power Limited due to Electronic Filter Temperature: Output power is being limited due to electronic filter temperature (see SPN 9232) approaching or exceeding the maximum limit.00b = No power limit for this reason01b = Powe...";
CM_ SG_ 2565918206 DCACAssIvt2PwLtddtPwEtsTpt "DC/AC Accessory Inverter 2 Power Limited due to Power Electronics Temperature: Output power is being limited due to power electronics temperature (see SPN 9233) approaching or exceeding the maximum limit.00b = No power limit for this reason01b = Powe...";
CM_ SG_ 2565918206 DCACAssIvt2PwLtddtRtCLt "DC/AC Accessory Inverter 2 Power Limited due to Rate of Change Limit: Output power is being limited due to the frequency approaching or exceeding the rate of change limit (see SPN 8346).00b = No power limit for this reason01b = Power limited for this...";
CM_ SG_ 2565918206 DCACAssIvt2PwLtddtUddRs "DC/AC Accessory Inverter 2 Power Limited due to Undefined Reason: Output power is being limited due to an undefined reason.00b = No power limit for this reason01b = Power limited for this reason10b = Error11b = Not Available";
CM_ SG_ 2565918206 DCACAssrInvrtr2FrqnCmmndlwMnmm "DC/AC Accessory Inverter 2 Frequency Command below Minimum: Output frequency is being limited due to frequency command (see SPN 8347) approaching or falling below the minimum limit (SPN 8343).00b = No frequency limit for this reason01b = Frequency li...";
CM_ SG_ 2565918206 DCACAssrInvrtr2FrqnCmmndxdsMxmm "DC/AC Accessory Inverter 2 Frequency Command exceeds Maximum: Output frequency is being limited due to frequency command (see SPN 8347) approaching or exceeding the maximum limit (SPN 8342).00b = No frequency limit for this reason01b = Frequency limi...";
CM_ BO_ 2565920510 "DC/AC Accessory Inverter 1 Command";
CM_ SG_ 2565920510 DCACAssIvt1ACSdMtSttRMSVtRqst "DC/AC Accessory Inverter 1 AC Side Motor Starting RMS Voltage Request: Signal to the DC/AC Accessory Inverter indicating the requested AC side RMS voltage for starting the attached accessory motor.   In a V/Hz variable speed motor control application...";
CM_ SG_ 2565920510 DCACAssrInvrtr1Dv1Stts "DC/AC Accessory Inverter 1 Device 1 Status: Signal to the DC/AC Accessory Inverter indicating the state of the device attached to the inverter output.  Each output may control multiple devices (e.g. electric motors) if they all operate at the same fr...";
CM_ SG_ 2565920510 DCACAssrInvrtr1Dv2Stts "DC/AC Accessory Inverter 1 Device 2 Status: Signal to the DC/AC Accessory Inverter indicating the state of the device attached to the inverter output.  Each output may control multiple devices (e.g. electric motors) if they all operate at the same fr...";
CM_ SG_ 2565920510 DCACAssrInvrtr1DvFrqnRtfChngLmt "DC/AC Accessory Inverter 1 Device Frequency Rate of Change Limit: Signal to the DC/AC Accessory Inverter indicating the frequency rate of change limit of the device(s) attached to the inverter output (Note: Increasing and decreasing rates can be cont...";
CM_ SG_ 2565920510 DCACAssrInvrtr1DvMnmmFrqn "DC/AC Accessory Inverter 1 Device Minimum Frequency: Signal to the DC/AC Accessory Inverter indicating the minimum frequency of the device(s) attached to the inverter output.  Each output may control multiple devices (e.g. electric motors) if they al...";
CM_ SG_ 2565920510 DCACAssrInvrtr1DvMxmmFrqn "DC/AC Accessory Inverter 1 Device Maximum Frequency: Signal to the DC/AC Accessory Inverter indicating the maximum frequency of the devices(s) attached to the inverter output.  Each output may control multiple devices (e.g. electric motors) if they a...";
CM_ SG_ 2565920510 DCACAssrInvrtr1DvRtdFrqn "DC/AC Accessory Inverter 1 Device Rated Frequency: Signal to the DC/AC Accessory Inverter indicating the rated frequency of the device(s) attached to the inverter output.  Each output may control multiple devices (e.g. electric motors) if they all op...";
CM_ SG_ 2565920510 DCACAssrInvrtr1DvRtdRMSVltg "DC/AC Accessory Inverter 1 Device Rated RMS Voltage: Signal to the DC/AC Accessory Inverter indicating the rated RMS voltage of the device(s) attached to the inverter output.   Each output may control multiple devices (e.g. electric motors) if they a...";
CM_ SG_ 2565920510 DCACAssrInvrtr1FrqnCmmnd "DC/AC Accessory Inverter 1 Frequency Command: Command to the DC/AC Accessory Inverter indicating the Inverter frequency desired for the device(s) attached to the inverter output.  Each output may control multiple devices (e.g. electric motors) if the...";
CM_ SG_ 2565920510 DCACAssrInvrtr1OprtnlCmmnd "DC/AC Accessory Inverter 1 Operational Command: Command to the DC/AC Accessory Inverter to enable this output.  Each output may control multiple devices (e.g. electric motors) if they all operate at the same frequency.00b = Disable DC/AC Accessory In...";
CM_ BO_ 2565920766 "DC/AC Accessory Inverter 1 Feedback";
CM_ SG_ 2565920766 DCACAccessoryInverter1Frequency "DC/AC Accessory Inverter 1 Frequency: Present operating frequency of this DC/AC Accessory Inverter output.";
CM_ SG_ 2565920766 DCACAssrInvrtr1ACSdPwr "DC/AC Accessory Inverter 1 AC Side Power: Present operating AC Side power of this DC/AC Accessory Inverter output.";
CM_ SG_ 2565920766 DCACAssrInvrtr1ACSdRMSCrrnt "DC/AC Accessory Inverter 1 AC Side RMS Current: Present operating AC Side output RMS line Current of this DC/AC Accessory Inverter.  When connected to a balanced three phase motor, this would be the current in each individual phase of the motor.";
CM_ SG_ 2565920766 DCACAssrInvrtr1ACSdRMSVltg "DC/AC Accessory Inverter 1 AC Side RMS Voltage: Present operating AC Side line to line RMS voltage of this DC/AC Accessory Inverter output.  In a three phase balanced motor, this is the RMS voltage across one phase of the motor.";
CM_ SG_ 2565920766 DCACAssrInvrtr1HVILStts "DC/AC Accessory Inverter 1 HVIL Status: High Voltage Interlock Loop (HVIL) state of the DC/AC Accessory Inverter 1.00b = HVIL Closed01b = HVIL Open10b = Error11b = Not Available";
CM_ SG_ 2565920766 DCACAssrInvrtr1LdshdRqst "DC/AC Accessory Inverter 1 Loadshed Request: Loadshed Request from this DC/AC Accessory Inverter output.  The Loadshed Requested state is an indication that the inverter output powering this device has a malfunction and is in a limit condition and if...";
CM_ SG_ 2565920766 DCACAssrInvrtr1OprtnlStts "DC/AC Accessory Inverter 1 Operational Status: Operating Status of this DC/AC Accessory Inverter output. The Inverter Output Faulted state will be communicated when the inverter output has shutdown due to an overload condition or other fault.000b = O...";
CM_ BO_ 2565921534 "DC/AC Accessory Inverter 2 Command";
CM_ SG_ 2565921534 DCACAssIvt2ACSdMtSttRMSVtRqst "DC/AC Accessory Inverter 2 AC Side Motor Starting RMS Voltage Request: Signal to the DC/AC Accessory Inverter indicating the requested AC side RMS voltage for starting the attached accessory motor.   In a V/Hz variable speed motor control application...";
CM_ SG_ 2565921534 DCACAssrInvrtr2Dv1Stts "DC/AC Accessory Inverter 2 Device 1 Status: Signal to the DC/AC Accessory Inverter indicating the state of the device attached to the inverter output.  Each output may control multiple devices (e.g. electric motors) if they all operate at the same fr...";
CM_ SG_ 2565921534 DCACAssrInvrtr2Dv2Stts "DC/AC Accessory Inverter 2 Device 2 Status: Signal to the DC/AC Accessory Inverter indicating the state of the device attached to the inverter output.  Each output may control multiple devices (e.g. electric motors) if they all operate at the same fr...";
CM_ SG_ 2565921534 DCACAssrInvrtr2DvFrqnRtfChngLmt "DC/AC Accessory Inverter 2 Device Frequency Rate of Change Limit: Signal to the DC/AC Accessory Inverter indicating the frequency rate of change limit of the device(s) attached to the inverter output (Note: Increasing and decreasing rates can be cont...";
CM_ SG_ 2565921534 DCACAssrInvrtr2DvMnmmFrqn "DC/AC Accessory Inverter 2 Device Minimum Frequency: Signal to the DC/AC Accessory Inverter indicating the minimum frequency of the device(s) attached to the inverter output.  Each output may control multiple devices (e.g. electric motors) if they al...";
CM_ SG_ 2565921534 DCACAssrInvrtr2DvMxmmFrqn "DC/AC Accessory Inverter 2 Device Maximum Frequency: Signal to the DC/AC Accessory Inverter indicating the maximum frequency of the devices(s) attached to the inverter output.  Each output may control multiple devices (e.g. electric motors) if they a...";
CM_ SG_ 2565921534 DCACAssrInvrtr2DvRtdFrqn "DC/AC Accessory Inverter 2 Device Rated Frequency: Signal to the DC/AC Accessory Inverter indicating the rated frequency of the device(s) attached to the inverter output.  Each output may control multiple devices (e.g. electric motors) if they all op...";
CM_ SG_ 2565921534 DCACAssrInvrtr2DvRtdRMSVltg "DC/AC Accessory Inverter 2 Device Rated RMS Voltage: Signal to the DC/AC Accessory Inverter indicating the rated RMS voltage of the device(s) attached to the inverter output.   Each output may control multiple devices (e.g. electric motors) if they a...";
CM_ SG_ 2565921534 DCACAssrInvrtr2FrqnCmmnd "DC/AC Accessory Inverter 2 Frequency Command: Command to the DC/AC Accessory Inverter indicating the Inverter frequency desired for the device(s) attached to the inverter output.  Each output may control multiple devices (e.g. electric motors) if the...";
CM_ SG_ 2565921534 DCACAssrInvrtr2OprtnlCmmnd "DC/AC Accessory Inverter 2 Operational Command: Command to the DC/AC Accessory Inverter to enable this output.  Each output may control multiple devices (e.g. electric motors) if they all operate at the same frequency.00b = Disable DC/AC Accessory In...";
CM_ BO_ 2565921790 "DC/AC Accessory Inverter 2 Feedback";
CM_ SG_ 2565921790 DCACAccessoryInverter2Frequency "DC/AC Accessory Inverter 2 Frequency: Present operating frequency of this DC/AC Accessory Inverter output.";
CM_ SG_ 2565921790 DCACAssrInvrtr2ACSdPwr "DC/AC Accessory Inverter 2 AC Side Power: Present operating AC Side power of this DC/AC Accessory Inverter output.";
CM_ SG_ 2565921790 DCACAssrInvrtr2ACSdRMSCrrnt "DC/AC Accessory Inverter 2 AC Side RMS Current: Present operating AC Side output RMS line Current of this DC/AC Accessory Inverter.  When connected to a balanced three phase motor, this would be the current in each individual phase of the motor.";
CM_ SG_ 2565921790 DCACAssrInvrtr2ACSdRMSVltg "DC/AC Accessory Inverter 2 AC Side RMS Voltage: Present operating AC Side line to line RMS voltage of this DC/AC Accessory Inverter output.  In a three phase balanced motor, this is the RMS voltage across one phase of the motor.";
CM_ SG_ 2565921790 DCACAssrInvrtr2HVILStts "DC/AC Accessory Inverter 2 HVIL Status: High Voltage Interlock Loop (HVIL) state of the DC/AC Accessory Inverter 2.00b = HVIL Closed01b = HVIL Open10b = Error11b = Not Available";
CM_ SG_ 2565921790 DCACAssrInvrtr2LdshdRqst "DC/AC Accessory Inverter 2 Loadshed Request: Loadshed Request from this DC/AC Accessory Inverter output.  The Loadshed Requested state is an indication that the inverter output powering this device has a malfunction and is in a limit condition and if...";
CM_ SG_ 2565921790 DCACAssrInvrtr2OprtnlStts "DC/AC Accessory Inverter 2 Operational Status: Operating Status of this DC/AC Accessory Inverter output. The Inverter Output Faulted state will be communicated when the inverter output has shutdown due to an overload condition or other fault.000b = O...";
CM_ BO_ 2565922558 "DC/AC Accessory Inverter 3 Command";
CM_ SG_ 2565922558 DCACAssIvt3ACSdMtSttRMSVtRqst "DC/AC Accessory Inverter 3 AC Side Motor Starting RMS Voltage Request: Signal to the DC/AC Accessory Inverter indicating the requested AC side RMS voltage for starting the attached accessory motor.   In a V/Hz variable speed motor control application...";
CM_ SG_ 2565922558 DCACAssrInvrtr3Dv1Stts "DC/AC Accessory Inverter 3 Device 1 Status: Signal to the DC/AC Accessory Inverter indicating the state of the device attached to the inverter output.  Each output may control multiple devices (e.g. electric motors) if they all operate at the same fr...";
CM_ SG_ 2565922558 DCACAssrInvrtr3Dv2Stts "DC/AC Accessory Inverter 3 Device 2 Status: Signal to the DC/AC Accessory Inverter indicating the state of the device attached to the inverter output.  Each output may control multiple devices (e.g. electric motors) if they all operate at the same fr...";
CM_ SG_ 2565922558 DCACAssrInvrtr3DvFrqnRtfChngLmt "DC/AC Accessory Inverter 3 Device Frequency Rate of Change Limit: Signal to the DC/AC Accessory Inverter indicating the frequency rate of change limit of the device(s) attached to the inverter output (Note: Increasing and decreasing rates can be cont...";
CM_ SG_ 2565922558 DCACAssrInvrtr3DvMnmmFrqn "DC/AC Accessory Inverter 3 Device Minimum Frequency: Signal to the DC/AC Accessory Inverter indicating the minimum frequency of the device(s) attached to the inverter output.  Each output may control multiple devices (e.g. electric motors) if they al...";
CM_ SG_ 2565922558 DCACAssrInvrtr3DvMxmmFrqn "DC/AC Accessory Inverter 3 Device Maximum Frequency: Signal to the DC/AC Accessory Inverter indicating the maximum frequency of the devices(s) attached to the inverter output.  Each output may control multiple devices (e.g. electric motors) if they a...";
CM_ SG_ 2565922558 DCACAssrInvrtr3DvRtdFrqn "DC/AC Accessory Inverter 3 Device Rated Frequency: Signal to the DC/AC Accessory Inverter indicating the rated frequency of the device(s) attached to the inverter output.  Each output may control multiple devices (e.g. electric motors) if they all op...";
CM_ SG_ 2565922558 DCACAssrInvrtr3DvRtdRMSVltg "DC/AC Accessory Inverter 3 Device Rated RMS Voltage: Signal to the DC/AC Accessory Inverter indicating the rated RMS voltage of the device(s) attached to the inverter output.   Each output may control multiple devices (e.g. electric motors) if they a...";
CM_ SG_ 2565922558 DCACAssrInvrtr3FrqnCmmnd "DC/AC Accessory Inverter 3 Frequency Command: Command to the DC/AC Accessory Inverter indicating the Inverter frequency desired for the device(s) attached to the inverter output.  Each output may control multiple devices (e.g. electric motors) if the...";
CM_ SG_ 2565922558 DCACAssrInvrtr3OprtnlCmmnd "DC/AC Accessory Inverter 3 Operational Command: Command to the DC/AC Accessory Inverter to enable this output.  Each output may control multiple devices (e.g. electric motors) if they all operate at the same frequency.00b = Disable DC/AC Accessory In...";
CM_ BO_ 2565922814 "DC/AC Accessory Inverter 3 Feedback";
CM_ SG_ 2565922814 DCACAccessoryInverter3Frequency "DC/AC Accessory Inverter 3 Frequency: Present operating frequency of this DC/AC Accessory Inverter output.";
CM_ SG_ 2565922814 DCACAssrInvrtr3ACSdPwr "DC/AC Accessory Inverter 3 AC Side Power: Present operating AC Side power of this DC/AC Accessory Inverter output.";
CM_ SG_ 2565922814 DCACAssrInvrtr3ACSdRMSCrrnt "DC/AC Accessory Inverter 3 AC Side RMS Current: Present operating AC Side output RMS line Current of this DC/AC Accessory Inverter.  When connected to a balanced three phase motor, this would be the current in each individual phase of the motor.";
CM_ SG_ 2565922814 DCACAssrInvrtr3ACSdRMSVltg "DC/AC Accessory Inverter 3 AC Side RMS Voltage: Present operating AC Side line to line RMS voltage of this DC/AC Accessory Inverter output.  In a three phase balanced motor, this is the RMS voltage across one phase of the motor.";
CM_ SG_ 2565922814 DCACAssrInvrtr3HVILStts "DC/AC Accessory Inverter 3 HVIL Status: High Voltage Interlock Loop (HVIL) state of the DC/AC Accessory Inverter 3.00b = HVIL Closed01b = HVIL Open10b = Error11b = Not Available";
CM_ SG_ 2565922814 DCACAssrInvrtr3LdshdRqst "DC/AC Accessory Inverter 3 Loadshed Request: Loadshed Request from this DC/AC Accessory Inverter output.  The Loadshed Requested state is an indication that the inverter output powering this device has a malfunction and is in a limit condition and if...";
CM_ SG_ 2565922814 DCACAssrInvrtr3OprtnlStts "DC/AC Accessory Inverter 3 Operational Status: Operating Status of this DC/AC Accessory Inverter output. The Inverter Output Faulted state will be communicated when the inverter output has shutdown due to an overload condition or other fault.000b = O...";
CM_ BO_ 2565923582 "DC/AC Accessory Inverter 4 Command";
CM_ SG_ 2565923582 DCACAssIvt4ACSdMtSttRMSVtRqst "DC/AC Accessory Inverter 4 AC Side Motor Starting RMS Voltage Request: Signal to the DC/AC Accessory Inverter indicating the requested AC side RMS voltage for starting the attached accessory motor.   In a V/Hz variable speed motor control application...";
CM_ SG_ 2565923582 DCACAssrInvrtr4Dv1Stts "DC/AC Accessory Inverter 4 Device 1 Status: Signal to the DC/AC Accessory Inverter indicating the state of the device attached to the inverter output.  Each output may control multiple devices (e.g. electric motors) if they all operate at the same fr...";
CM_ SG_ 2565923582 DCACAssrInvrtr4Dv2Stts "DC/AC Accessory Inverter 4 Device 2 Status: Signal to the DC/AC Accessory Inverter indicating the state of the device attached to the inverter output.  Each output may control multiple devices (e.g. electric motors) if they all operate at the same fr...";
CM_ SG_ 2565923582 DCACAssrInvrtr4DvFrqnRtfChngLmt "DC/AC Accessory Inverter 4 Device Frequency Rate of Change Limit: Signal to the DC/AC Accessory Inverter indicating the frequency rate of change limit of the device(s) attached to the inverter output (Note: Increasing and decreasing rates can be cont...";
CM_ SG_ 2565923582 DCACAssrInvrtr4DvMnmmFrqn "DC/AC Accessory Inverter 4 Device Minimum Frequency: Signal to the DC/AC Accessory Inverter indicating the minimum frequency of the device(s) attached to the inverter output.  Each output may control multiple devices (e.g. electric motors) if they al...";
CM_ SG_ 2565923582 DCACAssrInvrtr4DvMxmmFrqn "DC/AC Accessory Inverter 4 Device Maximum Frequency: Signal to the DC/AC Accessory Inverter indicating the maximum frequency of the devices(s) attached to the inverter output.  Each output may control multiple devices (e.g. electric motors) if they a...";
CM_ SG_ 2565923582 DCACAssrInvrtr4DvRtdFrqn "DC/AC Accessory Inverter 4 Device Rated Frequency: Signal to the DC/AC Accessory Inverter indicating the rated frequency of the device(s) attached to the inverter output.  Each output may control multiple devices (e.g. electric motors) if they all op...";
CM_ SG_ 2565923582 DCACAssrInvrtr4DvRtdRMSVltg "DC/AC Accessory Inverter 4 Device Rated RMS Voltage: Signal to the DC/AC Accessory Inverter indicating the rated RMS voltage of the device(s) attached to the inverter output.   Each output may control multiple devices (e.g. electric motors) if they a...";
CM_ SG_ 2565923582 DCACAssrInvrtr4FrqnCmmnd "DC/AC Accessory Inverter 4 Frequency Command: Command to the DC/AC Accessory Inverter indicating the Inverter frequency desired for the device(s) attached to the inverter output.  Each output may control multiple devices (e.g. electric motors) if the...";
CM_ SG_ 2565923582 DCACAssrInvrtr4OprtnlCmmnd "DC/AC Accessory Inverter 4 Operational Command: Command to the DC/AC Accessory Inverter to enable this output.  Each output may control multiple devices (e.g. electric motors) if they all operate at the same frequency.00b = Disable DC/AC Accessory In...";
CM_ BO_ 2565923838 "DC/AC Accessory Inverter 4 Feedback";
CM_ SG_ 2565923838 DCACAccessoryInverter4Frequency "DC/AC Accessory Inverter 4 Frequency: Present operating frequency of this DC/AC Accessory Inverter output.";
CM_ SG_ 2565923838 DCACAssrInvrtr4ACSdPwr "DC/AC Accessory Inverter 4 AC Side Power: Present operating AC Side power of this DC/AC Accessory Inverter output.";
CM_ SG_ 2565923838 DCACAssrInvrtr4ACSdRMSCrrnt "DC/AC Accessory Inverter 4 AC Side RMS Current: Present operating AC Side output RMS line Current of this DC/AC Accessory Inverter.  When connected to a balanced three phase motor, this would be the current in each individual phase of the motor.";
CM_ SG_ 2565923838 DCACAssrInvrtr4ACSdRMSVltg "DC/AC Accessory Inverter 4 AC Side RMS Voltage: Present operating AC Side line to line RMS voltage of this DC/AC Accessory Inverter output.  In a three phase balanced motor, this is the RMS voltage across one phase of the motor.";
CM_ SG_ 2565923838 DCACAssrInvrtr4HVILStts "DC/AC Accessory Inverter 4 HVIL Status: High Voltage Interlock Loop (HVIL) state of the DC/AC Accessory Inverter 4.00b = HVIL Closed01b = HVIL Open10b = Error11b = Not Available";
CM_ SG_ 2565923838 DCACAssrInvrtr4LdshdRqst "DC/AC Accessory Inverter 4 Loadshed Request: Loadshed Request from this DC/AC Accessory Inverter output.  The Loadshed Requested state is an indication that the inverter output powering this device has a malfunction and is in a limit condition and if...";
CM_ SG_ 2565923838 DCACAssrInvrtr4OprtnlStts "DC/AC Accessory Inverter 4 Operational Status: Operating Status of this DC/AC Accessory Inverter output. The Inverter Output Faulted state will be communicated when the inverter output has shutdown due to an overload condition or other fault.000b = O...";
CM_ BO_ 2565925374 "Aftertreatment 1 Intake Gas 3";
CM_ SG_ 2565925374 Aftrtrtmnt1IntkGsSnsr2HtrCntrl "Aftertreatment 1 Intake Gas Sensor 2 Heater Control: Indicates the heater status in the warm-up process.  Upon receiving a power-up command, the second gas sensor ramps up according to a manufacturer defined profile.  The Preheat 1, Preheat 2, and Au...";
CM_ SG_ 2565925374 Aftrtrtmnt1IntkGsSnsr2PwrInRng "Aftertreatment 1 Intake Gas Sensor 2 Power In Range: Indicates that the second measurement of power supplied to the aftertreatment intake gas sensor, either NOx or O2, is within the manufacturer's specification in exhaust bank 1.  This parameter repo...";
CM_ SG_ 2565925374 Aftrtrtmnt1IntkGsSnsr2tTmprtr "Aftertreatment 1 Intake Gas Sensor 2 at Temperature: Indicates that the heater element of the aftertreatment intake gas second sensor, either NOx or O2, is within the manufacturer's specified range for accurate measurements in exhaust bank 1.00b = No...";
CM_ SG_ 2565925374 Aftrtrtmnt1IntkPrntOxgn2 "Aftertreatment 1 Intake Percent Oxygen 2: The second measurement of the actual oxidation factor (Percent Oxygen) of the gas within the exhaust stream. For positive values, the parameter represents the percent oxygen in excess of the amount required f...";
CM_ SG_ 2565925374 Atttt1ItGsSs2HtPFMI "Aftertreatment 1 Intake Gas Sensor 2 Heater Preliminary FMI: Used to identify the second applicable J1939-73 FMI detected in the heater of the intake exhaust gas sensor, either NOx or O2, by the manufacturer’s sensor control software in exhaust bank ...";
CM_ SG_ 2565925374 Atttt1ItOxSs2PFMI "Aftertreatment 1 Intake Oxygen Sensor 2 Preliminary FMI: Used to identify the second applicable J1939-73 FMI detected in the aftertreatment intake oxygen sensor by the manufacturer’s sensor control software in exhaust bank 1.   In the case of multipl...";
CM_ SG_ 2565925374 Atttt1ItWdRPtOx2RdSt "Aftertreatment 1 Intake Wide-Range Percent Oxygen 2 Reading Stable: Indicates that the second measurement of the percent oxygen reading of the aftertreatment intake gas sensor, either NOx or O2, is stable as determined by the manufacturer's control s...";
CM_ SG_ 2565925374 EngineExhaust1NOx2 "Engine Exhaust 1 NOx 2: The second measurement of the amount of combined NO and NO2 in the exhaust, represented in NOx molecule parts per million non-NOx molecules in exhaust bank 1.  This sensor is located at the intake of the SCR system if an SCR s...";
CM_ SG_ 2565925374 EngineExhaust1NOx2ReadingStable "Engine Exhaust 1 NOx 2 Reading Stable: Indicates that the NOx reading of the second NOx sensor is stable as determined by the manufacturer's control software in exhaust bank 1.  This sensor is located at the intake of the SCR system if an SCR system ...";
CM_ SG_ 2565925374 EngnExhst1NOxSnsr2PrlmnrFMI "Engine Exhaust 1 NOx Sensor 2 Preliminary FMI: Used to identify the applicable J1939-73 FMI detected in the second NOx sensor by the manufacturer’s sensor control software in exhaust bank 1.  In the case of multiple failures the most severe is commun...";
CM_ SG_ 2565925374 EngnExhst1NOxSnsr2SlfdgnssStts "Engine Exhaust 1 NOx Sensor 2 Self-diagnosis Status: Self-diagnosis result status for the second NOx sensor in Engine Exhaust Bank 1 (EEB1).  This sensor is located at the intake of the aftertreatment system if an aftertreatment system exists.000b = ...";
CM_ BO_ 2565925630 "Aftertreatment 1 Outlet Gas 3";
CM_ SG_ 2565925630 Aftertreatment1OutletNOx2 "Aftertreatment 1 Outlet NOx 2: The second measurement of the amount of combined NO and NO2 in the exhaust exiting the aftertreatment system measured by a NOx sensor at the aftertreatment outlet, represented in NOx molecule parts per million non-NOx m...";
CM_ SG_ 2565925630 Aftrtrtmnt1OtltGsSnsr2HtrCntrl "Aftertreatment 1 Outlet Gas Sensor 2 Heater Control: Indicates the heater status in the warm-up process.  Upon receiving a power-up command, the gas second sensor ramps up according to a manufacturer defined profile.  The Preheat 1, Preheat 2, and Au...";
CM_ SG_ 2565925630 Aftrtrtmnt1OtltGsSnsr2PwrInRng "Aftertreatment 1 Outlet Gas Sensor 2 Power In Range: Indicates that the second measurement of power supplied to the aftertreatment outlet gas sensor, either NOx or O2, is within the manufacturer's specification in exhaust bank 1. This parameter repor...";
CM_ SG_ 2565925630 Aftrtrtmnt1OtltGsSnsr2tTmprtr "Aftertreatment 1 Outlet Gas Sensor 2 at Temperature: Indicates that the heater element of the aftertreatment outlet gas second sensor, either NOx or O2, is within the manufacturer's specified range for accurate measurements in exhaust bank 1.00b = No...";
CM_ SG_ 2565925630 Aftrtrtmnt1OtltNOx2RdngStl "Aftertreatment 1 Outlet NOx 2 Reading Stable: Indicates that the NOx reading of the aftertreatment outlet NOx second sensor is stable as determined by the manufacturer's control software in exhaust bank 1.00b = Not stable01b = Stable10b = Error11b = ...";
CM_ SG_ 2565925630 Aftrtrtmnt1OtltPrntOxgn2 "Aftertreatment 1 Outlet Percent Oxygen 2: The second measurement of the actual oxidation factor (percent oxygen) of the gas within the exhaust stream.  For positive values, the parameter represents the percent oxygen in excess of the amount required ...";
CM_ SG_ 2565925630 Atttt1OttGsSs2HtPFMI "Aftertreatment 1 Outlet Gas Sensor 2 Heater Preliminary FMI: Used to identify the applicable J1939-73 FMI detected in the heater of the outlet exhaust gas second sensor, either NOx or O2, by the manufacturer’s sensor control software in exhaust bank ...";
CM_ SG_ 2565925630 Atttt1OttNOxSs2PFMI "Aftertreatment 1 Outlet NOx Sensor 2 Preliminary FMI: Used to identify the applicable J1939-73 FMI detected in the aftertreatment outlet NOx second sensor by the manufacturer’s sensor control software in exhaust bank 1.  In the case of multiple failu...";
CM_ SG_ 2565925630 Atttt1OttNOxSs2SdssStts "Aftertreatment 1 Outlet NOx Sensor 2 Self-diagnosis Status: Self-diagnosis result status for NOx second sensor ATO1 (Aftertreatment Outlet Bank 1)000b = Diagnosis not active001b = NOx Sensor ATO1 Self-diagnosis active flag010b = NOx Sensor ATO1 Self-...";
CM_ SG_ 2565925630 Atttt1OttOxSs2PFMI "Aftertreatment 1 Outlet Oxygen Sensor 2 Preliminary FMI: Used to identify the applicable J1939-73 FMI detected in the aftertreatment outlet oxygen second sensor by the manufacturer’s sensor control software in exhaust bank 1.  In the case of multiple...";
CM_ SG_ 2565925630 Atttt1OttWdRPtOx2RdSt "Aftertreatment 1 Outlet Wide-Range Percent Oxygen 2 Reading Stable: Indicates that the percent oxygen reading of the aftertreatment outlet gas second sensor, either NOx or O2, is stable as determined by the manufacturer's control software in exhaust ...";
CM_ BO_ 2565925886 "Aftertreatment 2 Intake Gas Sensor 2";
CM_ SG_ 2565925886 Aftrtrtmnt2IntkGsSnsr2HtrCntrl "Aftertreatment 2 Intake Gas Sensor 2 Heater Control: Indicates the heater status in the warm-up process.  Upon receiving a power-up command, the second gas sensor ramps up according to a manufacturer defined profile.  The Preheat 1, Preheat 2, and Au...";
CM_ SG_ 2565925886 Aftrtrtmnt2IntkGsSnsr2PwrInRng "Aftertreatment 2 Intake Gas Sensor 2 Power In Range: Indicates that the power supplied to the aftertreatment intake gas second sensor, either NOx or O2, is within the manufacturer's specification in exhaust bank 2.For a single exhaust bank system, re...";
CM_ SG_ 2565925886 Aftrtrtmnt2IntkGsSnsr2tTmprtr "Aftertreatment 2 Intake Gas Sensor 2 at Temperature: Indicates that the heater element of the aftertreatment intake gas second sensor, either NOx or O2, is within the manufacturer's specified range for accurate measurements in exhaust bank 2.For a si...";
CM_ SG_ 2565925886 Aftrtrtmnt2IntkPrntOxgn2 "Aftertreatment 2 Intake Percent Oxygen 2: The actual oxidation factor (percent oxygen) of the gas within the exhaust stream.  For positive values, the parameter represents the percent oxygen in excess of the amount required for stoichiometric combust...";
CM_ SG_ 2565925886 Atttt2ItGsSs2HtPFMI "Aftertreatment 2 Intake Gas Sensor 2 Heater Preliminary FMI: Used to identify the applicable J1939-73 FMI detected in the heater of the intake exhaust gas second sensor, either NOx or O2, by the manufacturer’s sensor control software in exhaust bank ...";
CM_ SG_ 2565925886 Atttt2ItOxSs2PFMI "Aftertreatment 2 Intake Oxygen Sensor 2 Preliminary FMI: Used to identify the applicable J1939-73 FMI detected in the aftertreatment intake oxygen second sensor by the manufacturer’s sensor control software in exhaust bank 2.  In the case of multiple...";
CM_ SG_ 2565925886 Atttt2ItWdRPtOx2RdSt "Aftertreatment 2 Intake Wide-Range Percent Oxygen 2 Reading Stable: Indicates that the percent oxygen reading of the aftertreatment intake gas second sensor, either NOx or O2, is stable as determined by the manufacturer's control software in exhaust ...";
CM_ SG_ 2565925886 EngineExhaust2NOx2 "Engine Exhaust 2 NOx 2: The amount of combined NO and NO2 in the exhaust measured by the second NOx sensor at the aftertreatment intake, represented in NOx molecule parts per million non-NOx molecules in exhaust bank 2.  This sensor is located at the...";
CM_ SG_ 2565925886 EngineExhaust2NOx2ReadingStable "Engine Exhaust 2 NOx 2 Reading Stable: Indicates that the NOx reading of the second NOx sensor is stable as determined by the manufacturer's control software in exhaust bank 2.  This sensor is located at the intake of the SCR system if an SCR system ...";
CM_ SG_ 2565925886 EngnExhst2NOxSnsr2PrlmnrFMI "Engine Exhaust 2 NOx Sensor 2 Preliminary FMI: Used to identify the applicable J1939-73 FMI detected in the second NOx sensor by the manufacturer’s sensor control software in exhaust bank 2.  This sensor is located at the intake of the SCR system if ...";
CM_ SG_ 2565925886 EngnExhst2NOxSnsr2SlfdgnssStts "Engine Exhaust 2 NOx Sensor 2 Self-diagnosis Status: Self-diagnosis result status for NOx second sensor EEB2 (Engine Exhaust Bank 2).  This sensor is located at the intake of the aftertreatment system if an aftertreatment system exists.000b = Diagnos...";
CM_ BO_ 2565926142 "Aftertreatment 2 Outlet Gas Sensor 2";
CM_ SG_ 2565926142 Aftertreatment2OutletNOx2 "Aftertreatment 2 Outlet NOx 2: The amount of combined NO and NO2 in the exhaust entering the aftertreatment system measured by the second NOx sensor at the aftertreatment outlet, represented in NOx molecule parts per million non-NOx molecules in exha...";
CM_ SG_ 2565926142 Aftrtrtmnt2OtltGsSnsr2HtrCntrl "Aftertreatment 2 Outlet Gas Sensor 2 Heater Control: Indicates the heater status in the warm-up process.  Upon receiving a power-up command, the gas second sensor ramps up according to a manufacturer defined profile.  The Preheat 1, Preheat 2, and Au...";
CM_ SG_ 2565926142 Aftrtrtmnt2OtltGsSnsr2PwrInRng "Aftertreatment 2 Outlet Gas Sensor 2 Power In Range:  Indicates that the power supplied to the aftertreatment outlet gas second sensor, either NOx or O2, is within the manufacturer's specification in exhaust bank 2.For a single exhaust bank system, r...";
CM_ SG_ 2565926142 Aftrtrtmnt2OtltGsSnsr2tTmprtr "Aftertreatment 2 Outlet Gas Sensor 2 at Temperature: Indicates that the heater element of the aftertreatment outlet gas second sensor, either NOx or O2, is within the manufacturer's specified range for accurate measurements in exhaust bank 2.For a si...";
CM_ SG_ 2565926142 Aftrtrtmnt2OtltNOx2RdngStl "Aftertreatment 2 Outlet NOx  2 Reading Stable: Indicates that the NOx reading of the aftertreatment outlet NOx second sensor is stable as determined by the manufacturer's control software in exhaust bank 2.For a single exhaust bank system, refer to p...";
CM_ SG_ 2565926142 Aftrtrtmnt2OtltPrntOxgn2 "Aftertreatment 2 Outlet Percent Oxygen 2: The actual oxidation factor (percent oxygen) of the gas within the exhaust stream.  For positive values, the parameter represents the percent oxygen in excess of the amount required for stoichiometric combust...";
CM_ SG_ 2565926142 Atttt2OttGsSs2HtPFMI "Aftertreatment 2 Outlet Gas Sensor 2 Heater Preliminary FMI: Used to identify the applicable J1939-73 FMI detected in the heater of the outlet exhaust gas second sensor, either NOx or O2, by the manufacturer’s sensor control software in exhaust bank ...";
CM_ SG_ 2565926142 Atttt2OttNOxSs2PFMI "Aftertreatment 2 Outlet NOx Sensor 2 Preliminary FMI: Used to identify the applicable J1939-73 FMI detected in the aftertreatment outlet NOx second sensor by the manufacturer’s sensor control software in exhaust bank 2.  In the case of multiple failu...";
CM_ SG_ 2565926142 Atttt2OttNOxSs2SdssStts "Aftertreatment 2 Outlet NOx Sensor 2 Self-diagnosis Status: Self-diagnosis result status for second NOx sensor ATO2 (Aftertreatment Outlet Bank 2)000b = Diagnosis not active001b = NOx Sensor ATO2 Self-diagnosis active flag010b = NOx Sensor ATO2 Self-...";
CM_ SG_ 2565926142 Atttt2OttOxSs2PFMI "Aftertreatment 2 Outlet Oxygen Sensor 2 Preliminary FMI: Used to identify the applicable J1939-73 FMI detected in the aftertreatment outlet oxygen second sensor by the manufacturer’s sensor control software in exhaust bank 2.  In the case of multiple...";
CM_ SG_ 2565926142 Atttt2OttWdRPtOx2RdSt "Aftertreatment 2 Outlet Wide-Range Percent Oxygen 2 Reading Stable: Indicates that the percent oxygen reading of the aftertreatment outlet gas second sensor, either NOx or O2, is stable as determined by the manufacturer's control software in exhaust ...";
CM_ BO_ 2565932286 "Engine Speed Sensor Information 2";
CM_ SG_ 2565932286 EngineSpeed4 "Engine Speed 4: The engine speed as measured by speed sensor 4.Notes: This is for the engine speed from the 4th engine speed sensor. This may be different than SPN 190 when used in multiple engine speed sensor configurations. In an application with m...";
CM_ BO_ 2565932798 "Well Stimulation Pump System 1";
CM_ SG_ 2565932798 WllStmltnPmpDshrgPrssr "Well Stimulation Pump Discharge Pressure: The pressure on the discharge side of the well stimulation pump.";
CM_ SG_ 2565932798 WllStmltnPmpStnPrssr "Well Stimulation Pump Suction Pressure: The pressure on the suction side of the well stimulation pump.";
CM_ BO_ 2565933054 "Well Stimulation Pump System 2";
CM_ SG_ 2565933054 WellStimulationPumpSpeed "Well Stimulation Pump Speed: The operating speed of the well stimulation pump.";
CM_ SG_ 2565933054 WllStmltnPmpGrBxOlPrssr "Well Stimulation Pump Gear Box Oil Pressure: The oil pressure measured in the well stimulation pump gear box.";
CM_ SG_ 2565933054 WllStmltnPmpGrBxOlTmprtr "Well Stimulation Pump Gear Box Oil Temperature: Temperature of the oil in the well stimulation pump gear box.";
CM_ SG_ 2565933054 WllStmltnPmpGrBxOtltOlTmprtr "Well Stimulation Pump Gear Box Outlet Oil Temperature: Temperature of the oil at the outlet of the well stimulation pump gear box.  Reference SPN 8157 for the temperature at the inlet of the pump gear box.";
CM_ BO_ 2565934590 "Fuel Information 6 (Gaseous)";
CM_ SG_ 2565934590 EngnFlVlv2DffrntlPrssr "Engine Fuel Valve 2 Differential Pressure: The differential pressure between the intake and the outlet of the second gaseous fuel valve.";
CM_ BO_ 2565942014 "DC/AC Accessory Inverter 3 Feedback 2";
CM_ SG_ 2565942014 DCACAssIvt3PwLtddtACSdRMSCt "DC/AC Accessory Inverter 3 Power Limited due to AC Side RMS Current: AC Side Output power is being limited due to AC Side output RMS current (see SPN 9202) approaching or exceeding the maximum limit (See SPN 9288).00b = No power limit for this reason...";
CM_ SG_ 2565942014 DCACAssIvt3PwLtddtCtTpt "DC/AC Accessory Inverter 3 Power Limited due to Controller Temperature: Output power is being limited due to the controller temperature (see SPN 9261) approaching or exceeding the maximum limit.00b = No power limit for this reason01b = Power limited ...";
CM_ SG_ 2565942014 DCACAssIvt3PwLtddtDCSdCt "DC/AC Accessory Inverter 3 Power Limited due to DC Side Current: Output power is being limited due to DC Side input current (see SPN 9268) approaching or exceeding the maximum limit (See SPN 9286).00b = No power limit for this reason01b = Power limit...";
CM_ SG_ 2565942014 DCACAssIvt3PwLtddtDCSdVtM "DC/AC Accessory Inverter 3 Power Limited due to DC Side Voltage Minimum: Output power is being limited due to DC Side input voltage (see SPN 9267) approaching or falling below the minimum limit  (SPN 9285).00b = No power limit for this reason01b = Po...";
CM_ SG_ 2565942014 DCACAssIvt3PwLtddtEtFtTpt "DC/AC Accessory Inverter 3 Power Limited due to Electronic Filter Temperature: Output power is being limited due to electronic filter temperature (see SPN 9262) approaching or exceeding the maximum limit.00b = No power limit for this reason01b = Powe...";
CM_ SG_ 2565942014 DCACAssIvt3PwLtddtPwEtsTpt "DC/AC Accessory Inverter 3 Power Limited due to Power Electronics Temperature: Output power is being limited due to power electronics temperature (see SPN 9263) approaching or exceeding the maximum limit.00b = No power limit for this reason01b = Powe...";
CM_ SG_ 2565942014 DCACAssIvt3PwLtddtRtCLt "DC/AC Accessory Inverter 3 Power Limited due to Rate of Change Limit: Output power is being limited due to the frequency approaching or exceeding the rate of change limit (see SPN 8360).00b = No power limit for this reason01b = Power limited for this...";
CM_ SG_ 2565942014 DCACAssIvt3PwLtddtUddRs "DC/AC Accessory Inverter 3 Power Limited due to Undefined Reason: Output power is being limited due to an undefined reason.00b = No power limit for this reason01b = Power limited for this reason10b = Error11b = Not Available";
CM_ SG_ 2565942014 DCACAssrInvrtr3FrqnCmmndlwMnmm "DC/AC Accessory Inverter 3 Frequency Command below Minimum: Output frequency is being limited due to frequency command (see SPN 8361) approaching or falling below the minimum limit (SPN 8357).00b = No frequency limit for this reason01b = Frequency li...";
CM_ SG_ 2565942014 DCACAssrInvrtr3FrqnCmmndxdsMxmm "DC/AC Accessory Inverter 3 Frequency Command exceeds Maximum: Output frequency is being limited due to frequency command (see SPN 8361) approaching or exceeding the maximum limit (SPN 8356).00b = No frequency limit for this reason01b = Frequency limi...";
CM_ BO_ 2565942782 "DC/AC Accessory Inverter 4 Feedback 2";
CM_ SG_ 2565942782 DCACAssIvt4PwLtddtACSdRMSCt "DC/AC Accessory Inverter 4 Power Limited due to AC Side RMS Current: AC Side Output power is being limited due to AC Side output RMS current (see SPN 9203) approaching or exceeding the maximum limit (See SPN 9318).00b = No power limit for this reason...";
CM_ SG_ 2565942782 DCACAssIvt4PwLtddtCtTpt "DC/AC Accessory Inverter 4 Power Limited due to Controller Temperature: Output power is being limited due to the controller temperature (see SPN 9291) approaching or exceeding the maximum limit.00b = No power limit for this reason01b = Power limited ...";
CM_ SG_ 2565942782 DCACAssIvt4PwLtddtDCSdCt "DC/AC Accessory Inverter 4 Power Limited due to DC Side Current: Output power is being limited due to DC Side input current (see SPN 9298) approaching or exceeding the maximum limit (See SPN 9316).00b = No power limit for this reason01b = Power limit...";
CM_ SG_ 2565942782 DCACAssIvt4PwLtddtDCSdVtM "DC/AC Accessory Inverter 4 Power Limited due to DC Side Voltage Minimum: Output power is being limited due to DC Side input voltage (see SPN 9297) approaching or falling below the minimum limit (SPN 9315).00b = No power limit for this reason01b = Pow...";
CM_ SG_ 2565942782 DCACAssIvt4PwLtddtEtFtTpt "DC/AC Accessory Inverter 4 Power Limited due to Electronic Filter Temperature: Output power is being limited due to electronic filter temperature (see SPN 9292) approaching or exceeding the maximum limit.00b = No power limit for this reason01b = Powe...";
CM_ SG_ 2565942782 DCACAssIvt4PwLtddtPwEtsTpt "DC/AC Accessory Inverter 4 Power Limited due to Power Electronics Temperature: Output power is being limited due to power electronics temperature (see SPN 9293) approaching or exceeding the maximum limit.00b = No power limit for this reason01b = Powe...";
CM_ SG_ 2565942782 DCACAssIvt4PwLtddtRtCLt "DC/AC Accessory Inverter 4 Power Limited due to Rate of Change Limit: Output power is being limited due to the frequency approaching or exceeding the rate of change limit (see SPN 8374).00b = No power limit for this reason01b = Power limited for this...";
CM_ SG_ 2565942782 DCACAssIvt4PwLtddtUddRs "DC/AC Accessory Inverter 4 Power Limited due to Undefined Reason: Output power is being limited due to an undefined reason.00b = No power limit for this reason01b = Power limited for this reason10b = Error11b = Not Available";
CM_ SG_ 2565942782 DCACAssrInvrtr4FrqnCmmndlwMnmm "DC/AC Accessory Inverter 4 Frequency Command below Minimum: Output frequency is being limited due to frequency command (see SPN 8375) approaching or falling below the minimum limit (SPN 8371).00b = No frequency limit for this reason01b = Frequency li...";
CM_ SG_ 2565942782 DCACAssrInvrtr4FrqnCmmndxdsMxmm "DC/AC Accessory Inverter 4 Frequency Command exceeds Maximum: Output frequency is being limited due to frequency command (see SPN 8375) approaching or exceeding the maximum limit (SPN 8370).00b = No frequency limit for this reason01b = Frequency limi...";
CM_ BO_ 2565943038 "DC/AC Accessory Inverter 5 Command";
CM_ SG_ 2565943038 DCACAssIvt5ACSdMtSttRMSVtRqst "DC/AC Accessory Inverter 5 AC Side Motor Starting RMS Voltage Request: Signal to the DC/AC Accessory Inverter indicating the requested AC side RMS voltage for starting the attached accessory motor.   In a V/Hz variable speed motor control application...";
CM_ SG_ 2565943038 DCACAssrInvrtr5Dv1Stts "DC/AC Accessory Inverter 5 Device 1 Status: Signal to the DC/AC Accessory Inverter indicating the state of the device attached to the inverter output.  Each output may control multiple devices (e.g. electric motors) if they all operate at the same fr...";
CM_ SG_ 2565943038 DCACAssrInvrtr5Dv2Stts "DC/AC Accessory Inverter 5 Device 2 Status: Signal to the DC/AC Accessory Inverter indicating the state of the device attached to the inverter output.  Each output may control multiple devices (e.g. electric motors) if they all operate at the same fr...";
CM_ SG_ 2565943038 DCACAssrInvrtr5DvFrqnRtfChngLmt "DC/AC Accessory Inverter 5 Device Frequency Rate of Change Limit: Signal to the DC/AC Accessory Inverter indicating the frequency rate of change limit of the device(s) attached to the inverter output (Note: Increasing and decreasing rates can be cont...";
CM_ SG_ 2565943038 DCACAssrInvrtr5DvMnmmFrqn "DC/AC Accessory Inverter 5 Device Minimum Frequency: Signal to the DC/AC Accessory Inverter indicating the minimum frequency of the device(s) attached to the inverter output.  Each output may control multiple devices (e.g. electric motors) if they al...";
CM_ SG_ 2565943038 DCACAssrInvrtr5DvMxmmFrqn "DC/AC Accessory Inverter 5 Device Maximum Frequency: Signal to the DC/AC Accessory Inverter indicating the maximum frequency of the devices(s) attached to the inverter output.  Each output may control multiple devices (e.g. electric motors) if they a...";
CM_ SG_ 2565943038 DCACAssrInvrtr5DvRtdFrqn "DC/AC Accessory Inverter 5 Device Rated Frequency: Signal to the DC/AC Accessory Inverter indicating the rated frequency of the device(s) attached to the inverter output.  Each output may control multiple devices (e.g. electric motors) if they all op...";
CM_ SG_ 2565943038 DCACAssrInvrtr5DvRtdRMSVltg "DC/AC Accessory Inverter 5 Device Rated RMS Voltage: Signal to the DC/AC Accessory Inverter indicating the rated RMS voltage of the device(s) attached to the inverter output.   Each output may control multiple devices (e.g. electric motors) if they a...";
CM_ SG_ 2565943038 DCACAssrInvrtr5FrqnCmmnd "DC/AC Accessory Inverter 5 Frequency Command: Command to the DC/AC Accessory Inverter indicating the Inverter frequency desired for the device(s) attached to the inverter output.  Each output may control multiple devices (e.g. electric motors) if the...";
CM_ SG_ 2565943038 DCACAssrInvrtr5OprtnlCmmnd "DC/AC Accessory Inverter 5 Operational Command: Command to the DC/AC Accessory Inverter to enable this output.  Each output may control multiple devices (e.g. electric motors) if they all operate at the same frequency.00b = Disable DC/AC Accessory In...";
CM_ BO_ 2565943294 "DC/AC Accessory Inverter 5 Feedback";
CM_ SG_ 2565943294 DCACAccessoryInverter5Frequency "DC/AC Accessory Inverter 5 Frequency: Present operating frequency of this DC/AC Accessory Inverter output.";
CM_ SG_ 2565943294 DCACAssrInvrtr5ACSdPwr "DC/AC Accessory Inverter 5 AC Side Power: Present operating AC Side power of this DC/AC Accessory Inverter output.";
CM_ SG_ 2565943294 DCACAssrInvrtr5ACSdRMSCrrnt "DC/AC Accessory Inverter 5 AC Side RMS Current: Present operating AC Side output RMS line Current of this DC/AC Accessory Inverter.  When connected to a balanced three phase motor, this would be the current in each individual phase of the motor.";
CM_ SG_ 2565943294 DCACAssrInvrtr5ACSdRMSVltg "DC/AC Accessory Inverter 5 AC Side RMS Voltage: Present operating AC Side line to line RMS voltage of this DC/AC Accessory Inverter output.  In a three phase balanced motor, this is the RMS voltage across one phase of the motor.";
CM_ SG_ 2565943294 DCACAssrInvrtr5HVILStts "DC/AC Accessory Inverter 5 HVIL Status: High Voltage Interlock Loop (HVIL) state of the DC/AC Accessory Inverter 5.00b = HVIL Closed01b = HVIL Open10b = Error11b = Not Available";
CM_ SG_ 2565943294 DCACAssrInvrtr5LdshdRqst "DC/AC Accessory Inverter 5 Loadshed Request: Loadshed Request from this DC/AC Accessory Inverter output.  The Loadshed Requested state is an indication that the inverter output powering this device has a malfunction and is in a limit condition and if...";
CM_ SG_ 2565943294 DCACAssrInvrtr5OprtnlStts "DC/AC Accessory Inverter 5 Operational Status: Operating Status of this DC/AC Accessory Inverter output. The Inverter Output Faulted state will be communicated when the inverter output has shutdown due to an overload condition or other fault.000b = O...";
CM_ BO_ 2565944062 "DC/AC Accessory Inverter 5 Feedback 2";
CM_ SG_ 2565944062 DCACAssIvt5PwLtddtACSdRMSCt "DC/AC Accessory Inverter 5 Power Limited due to AC Side RMS Current: AC Side Output power is being limited due to AC Side output RMS current (see SPN 9333) approaching or exceeding the maximum limit (See SPN 9364).00b = No power limit for this reason...";
CM_ SG_ 2565944062 DCACAssIvt5PwLtddtCtTpt "DC/AC Accessory Inverter 5 Power Limited due to Controller Temperature: Output power is being limited due to the controller temperature (see SPN 9337) approaching or exceeding the maximum limit.00b = No power limit for this reason01b = Power limited ...";
CM_ SG_ 2565944062 DCACAssIvt5PwLtddtDCSdCt "DC/AC Accessory Inverter 5 Power Limited due to DC Side Current: Output power is being limited due to DC Side input current (see SPN 9344) approaching or exceeding the maximum limit (See SPN 9362).00b = No power limit for this reason01b = Power limit...";
CM_ SG_ 2565944062 DCACAssIvt5PwLtddtDCSdVtM "DC/AC Accessory Inverter 5 Power Limited due to DC Side Voltage Minimum: Output power is being limited due to DC Side input voltage (see SPN 9343) approaching or falling below the minimum limit (SPN 9361).00b = No power limit for this reason01b = Pow...";
CM_ SG_ 2565944062 DCACAssIvt5PwLtddtEtFtTpt "DC/AC Accessory Inverter 5 Power Limited due to Electronic Filter Temperature: Output power is being limited due to electronic filter temperature (see SPN 9338) approaching or exceeding the maximum limit.00b = No power limit for this reason01b = Powe...";
CM_ SG_ 2565944062 DCACAssIvt5PwLtddtPwEtsTpt "DC/AC Accessory Inverter 5 Power Limited due to Power Electronics Temperature: Output power is being limited due to power electronics temperature (see SPN 9339) approaching or exceeding the maximum limit.00b = No power limit for this reason01b = Powe...";
CM_ SG_ 2565944062 DCACAssIvt5PwLtddtRtCLt "DC/AC Accessory Inverter 5 Power Limited due to Rate of Change Limit: Output power is being limited due to the frequency approaching or exceeding the rate of change limit (see SPN 9325).00b = No power limit for this reason01b = Power limited for this...";
CM_ SG_ 2565944062 DCACAssIvt5PwLtddtUddRs "DC/AC Accessory Inverter 5 Power Limited due to Undefined Reason: Output power is being limited due to an undefined reason.00b = No power limit for this reason01b = Power limited for this reason10b = Error11b = Not Available";
CM_ SG_ 2565944062 DCACAssrInvrtr5FrqnCmmndlwMnmm "DC/AC Accessory Inverter 5 Frequency Command below Minimum: Output frequency is being limited due to frequency command (see SPN 9326) approaching or falling below the minimum limit (SPN 9322).00b = No frequency limit for this reason01b = Frequency li...";
CM_ SG_ 2565944062 DCACAssrInvrtr5FrqnCmmndxdsMxmm "DC/AC Accessory Inverter 5 Frequency Command exceeds Maximum: Output frequency is being limited due to frequency command (see SPN 9326) approaching or exceeding the maximum limit (SPN 9321).00b = No frequency limit for this reason01b = Frequency limi...";
CM_ BO_ 2566624510 "Electronic Engine Controller 22";
CM_ SG_ 2566624510 EngnExhstGsRrltn1ClrIntkPrssr "Engine Exhaust Gas Recirculation 1 Cooler Intake Pressure: Exhaust gas recirculation gage pressure is measured at the EGR cooler intake.";
CM_ BO_ 2566624766 "Engine Hours 2";
CM_ SG_ 2566624766 EngnIdlMngmntAtvTtlTm "Engine Idle Management Active Total Time: Total accumulated time the engine is off due to the engine idle management system.";
CM_ BO_ 2566625022 "Engine Information 3";
CM_ SG_ 2566625022 InstntnsEstmtdEngnPwrRtLmt "Instantaneous Estimated Engine Power Rate Limit: Estimate of the maximum power load rate the engine can sustain at that moment in time.";
CM_ BO_ 2566625278 "Vehicle Electrical Power 15";
CM_ SG_ 2566625278 SLIBttrPk1Bttr1CptSttng "SLI Battery Pack 1 Battery 1 Capacity Setting: Informs the battery controller of the capacity of its associated battery.  This parameter applies to the first battery in the first set of batteries (battery pack) used for starting the engine, for light...";
CM_ SG_ 2566625278 SLIBttrPk1Bttr2CptSttng "SLI Battery Pack 1 Battery 2 Capacity Setting: Informs the battery controller of the capacity of its associated battery.  This parameter applies to the second battery in the first set of batteries (battery pack) used for starting the engine, for ligh...";
CM_ SG_ 2566625278 SLIBttrPk1Bttr3CptSttng "SLI Battery Pack 1 Battery 3 Capacity Setting: Informs the battery controller of the capacity of its associated battery.  This parameter applies to the third battery in the first set of batteries (battery pack) used for starting the engine, for light...";
CM_ SG_ 2566625278 SLIBttrPk1Bttr4CptSttng "SLI Battery Pack 1 Battery 4 Capacity Setting: Informs the battery controller of the capacity of its associated battery.  This parameter applies to the fourth battery in the first set of batteries (battery pack) used for starting the engine, for ligh...";
CM_ BO_ 2566625790 "DC/AC Accessory Inverter 1 Temperatures";
CM_ SG_ 2566625790 DCACAssIvt1IvtEtFtTpt "DC/AC Accessory Inverter 1 Inverter Electronic Filter Temperature: Temperature of the electronic components that make up the DC/AC Accessory Inverter filter.";
CM_ SG_ 2566625790 DCACAssrInvrtr1ClntInTmprtr "DC/AC Accessory Inverter 1 Coolant  In Temperature: Temperature of the DC/AC Accessory Inverter Coolant measured at the input of the accessory inverter.";
CM_ SG_ 2566625790 DCACAssrInvrtr1ClntOtTmprtr "DC/AC Accessory Inverter 1 Coolant Out Temperature: Temperature of the DC/AC Accessory Inverter Coolant measured at the output of the accessory inverter.";
CM_ SG_ 2566625790 DCACAssrInvrtr1CntrllrTmprtr "DC/AC Accessory Inverter 1 Controller Temperature: Temperature of the DC/AC Accessory Inverter (e.g, controller, circuit board, enclosure).";
CM_ SG_ 2566625790 DCACAssrInvrtr1PwrEltrnsTmprtr "DC/AC Accessory Inverter 1 Power Electronics Temperature: Temperature of the DC/AC Accessory Inverter power electronics components (e.g, switch or heatsink).";
CM_ BO_ 2566626558 "DC/AC Accessory Inverter 1 Configuration 1";
CM_ SG_ 2566626558 DCACAssIvt1ACSdDtFqCdStt "DC/AC Accessory Inverter 1 AC Side Default Frequency Command Setting: Reports the active AC Side Default Frequency Command Setting of the DC/AC Accessory Inverter.  The setting may be requested by a separate device (via SPN 9523).Note: Report Not Ava...";
CM_ SG_ 2566626558 DCACAssIvt1ACSdRMSCtMxLtStt "DC/AC Accessory Inverter 1 AC Side RMS Current Maximum Limit Setting: Reports the active maximum limit on the AC side output RMS line current of the DC/AC Accessory Inverter.  The setting may be requested by a separate device (via SPN 9224) or determ...";
CM_ SG_ 2566626558 DCACAssIvt1ACSdRMSVtMxLtStt "DC/AC Accessory Inverter 1 AC Side RMS Voltage Maximum Limit Setting: Reports the active maximum limit on the AC Side output line to line RMS voltage of the DC/AC Accessory Inverter.  The setting may be requested by a separate device (via SPN 9223) o...";
CM_ SG_ 2566626558 DCACAssIvt1DCSdCtMLtStt "DC/AC Accessory Inverter 1 DC Side Current Minimum Limit Setting: Reports the active minimum limit on the DC Side input current of the DC/AC Accessory Inverter.  The setting may be requested by a separate device (via SPN 9530) or determined by the DC...";
CM_ SG_ 2566626558 DCACAssIvt1DCSdCtMxLtStt "DC/AC Accessory Inverter 1 DC Side Current Maximum Limit Setting: Reports the active maximum limit on the DC Side input current of the DC/AC Accessory Inverter.  The setting may be requested by a separate device (via SPN 9222) or determined by the DC...";
CM_ SG_ 2566626558 DCACAssIvt1DCSdVtMLtStt "DC/AC Accessory Inverter 1 DC Side Voltage Minimum Limit Setting: Reports the active minimum limit on the DC Side input voltage of the DC/AC Accessory Inverter.  The setting may be requested by a separate device (via SPN 9221) or determined by the DC...";
CM_ SG_ 2566626558 DCACAssIvt1DCSdVtMxLtStt "DC/AC Accessory Inverter 1 DC Side Voltage Maximum Limit Setting: Reports the active maximum limit on the DC Side input voltage of the DC/AC Accessory Inverter.  The setting may be requested by a separate device (via SPN 9529) or determined by the DC...";
CM_ BO_ 2566626814 "DC/AC Accessory Inverter 1 Lifetime Data";
CM_ SG_ 2566626814 DCACAssrInvrtr1TtlDCInptChrg "DC/AC Accessory Inverter 1 Total DC Input Charge : Total lifetime charge converted by the DC/AC from the DC Side.  ";
CM_ SG_ 2566626814 DCACAssrInvrtr1TtlDCInptEnrg "DC/AC Accessory Inverter 1 Total DC Input Energy : Total lifetime energy converted by the DC/AC from the DC Side.";
CM_ BO_ 2566627070 "DC/AC Accessory Inverter 2 Temperatures";
CM_ SG_ 2566627070 DCACAssIvt2IvtEtFtTpt "DC/AC Accessory Inverter 2 Inverter Electronic Filter Temperature: Temperature of the electronic components that make up the DC/AC Accessory Inverter filter.";
CM_ SG_ 2566627070 DCACAssrInvrtr2ClntInTmprtr "DC/AC Accessory Inverter 2 Coolant  In Temperature: Temperature of the DC/AC Accessory Inverter Coolant measured at the input of the accessory inverter.";
CM_ SG_ 2566627070 DCACAssrInvrtr2ClntOtTmprtr "DC/AC Accessory Inverter 2 Coolant Out Temperature: Temperature of the DC/AC Accessory Inverter Coolant measured at the output of the accessory inverter.";
CM_ SG_ 2566627070 DCACAssrInvrtr2CntrllrTmprtr "DC/AC Accessory Inverter 2 Controller Temperature: Temperature of the DC/AC Accessory Inverter (e.g, controller, circuit board, enclosure).";
CM_ SG_ 2566627070 DCACAssrInvrtr2PwrEltrnsTmprtr "DC/AC Accessory Inverter 2 Power Electronics Temperature: Temperature of the DC/AC Accessory Inverter power electronics components (e.g, switch or heatsink).";
CM_ BO_ 2566627838 "DC/AC Accessory Inverter 2 Configuration 1";
CM_ SG_ 2566627838 DCACAssIvt2ACSdDtFqCdStt "DC/AC Accessory Inverter 2 AC Side Default Frequency Command Setting: Reports the active AC Side Default Frequency Command Setting of the DC/AC Accessory Inverter.  The setting may be requested by a separate device (via SPN 9524).Note: Report Not Ava...";
CM_ SG_ 2566627838 DCACAssIvt2ACSdRMSCtMxLtStt "DC/AC Accessory Inverter 2 AC Side RMS Current Maximum Limit Setting: Reports the active maximum limit on the AC side output RMS line current of the DC/AC Accessory Inverter.  The setting may be requested by a separate device (via SPN 9254) or determ...";
CM_ SG_ 2566627838 DCACAssIvt2ACSdRMSVtMxLtStt "DC/AC Accessory Inverter 2 AC Side RMS Voltage Maximum Limit Setting: Reports the active maximum limit on the AC Side output line to line RMS voltage of the DC/AC Accessory Inverter.  The setting may be requested by a separate device (via SPN 9253) o...";
CM_ SG_ 2566627838 DCACAssIvt2DCSdCtMLtStt "DC/AC Accessory Inverter 2 DC Side Current Minimum Limit Setting: Reports the active minimum limit on the DC Side input current of the DC/AC Accessory Inverter.  The setting may be requested by a separate device (via SPN 9536) or determined by the DC...";
CM_ SG_ 2566627838 DCACAssIvt2DCSdCtMxLtStt "DC/AC Accessory Inverter 2 DC Side Current Maximum Limit Setting: Reports the active maximum limit on the DC Side input current of the DC/AC Accessory Inverter.  The setting may be requested by a separate device (via SPN 9252) or determined by the DC...";
CM_ SG_ 2566627838 DCACAssIvt2DCSdVtMLtStt "DC/AC Accessory Inverter 2 DC Side Voltage Minimum Limit Setting: Reports the active minimum limit on the DC Side input voltage of the DC/AC Accessory Inverter.  The setting may be requested by a separate device (via SPN 9251) or determined by the DC...";
CM_ SG_ 2566627838 DCACAssIvt2DCSdVtMxLtStt "DC/AC Accessory Inverter 2 DC Side Voltage Maximum Limit Setting: Reports the active maximum limit on the DC Side input voltage of the DC/AC Accessory Inverter.  The setting may be requested by a separate device (via SPN 9535) or determined by the DC...";
CM_ BO_ 2566628094 "DC/AC Accessory Inverter 2 Lifetime Data";
CM_ SG_ 2566628094 DCACAssrInvrtr2TtlDCInptChrg "DC/AC Accessory Inverter 2 Total DC Input Charge : Total lifetime charge converted by the DC/AC from the DC Side.  ";
CM_ SG_ 2566628094 DCACAssrInvrtr2TtlDCInptEnrg "DC/AC Accessory Inverter 2 Total DC Input Energy : Total lifetime energy converted by the DC/AC from the DC Side.";
CM_ BO_ 2566628350 "DC/AC Accessory Inverter 3 Temperatures";
CM_ SG_ 2566628350 DCACAssIvt3IvtEtFtTpt "DC/AC Accessory Inverter 3 Inverter Electronic Filter Temperature: Temperature of the electronic components that make up the DC/AC Accessory Inverter filter.";
CM_ SG_ 2566628350 DCACAssrInvrtr3ClntInTmprtr "DC/AC Accessory Inverter 3 Coolant  In Temperature: Temperature of the DC/AC Accessory Inverter Coolant measured at the input of the accessory inverter.";
CM_ SG_ 2566628350 DCACAssrInvrtr3ClntOtTmprtr "DC/AC Accessory Inverter 3 Coolant Out Temperature: Temperature of the DC/AC Accessory Inverter Coolant measured at the output of the accessory inverter.";
CM_ SG_ 2566628350 DCACAssrInvrtr3CntrllrTmprtr "DC/AC Accessory Inverter 3 Controller Temperature: Temperature of the DC/AC Accessory Inverter (e.g, controller, circuit board, enclosure).";
CM_ SG_ 2566628350 DCACAssrInvrtr3PwrEltrnsTmprtr "DC/AC Accessory Inverter 3 Power Electronics Temperature: Temperature of the DC/AC Accessory Inverter power electronics components (e.g, switch or heatsink).";
CM_ BO_ 2566629118 "DC/AC Accessory Inverter 3 Configuration 1";
CM_ SG_ 2566629118 DCACAssIvt3ACSdDtFqCdStt "DC/AC Accessory Inverter 3 AC Side Default Frequency Command Setting: Reports the active AC Side Default Frequency Command Setting of the DC/AC Accessory Inverter.  The setting may be requested by a separate device (via SPN 9525).Note: Report Not Ava...";
CM_ SG_ 2566629118 DCACAssIvt3ACSdRMSCtMxLtStt "DC/AC Accessory Inverter 3 AC Side RMS Current Maximum Limit Setting: Reports the active maximum limit on the AC side output RMS line current of the DC/AC Accessory Inverter.  The setting may be requested by a separate device (via SPN 9284) or determ...";
CM_ SG_ 2566629118 DCACAssIvt3ACSdRMSVtMxLtStt "DC/AC Accessory Inverter 3 AC Side RMS Voltage Maximum Limit Setting: Reports the active maximum limit on the AC Side output line to line RMS voltage of the DC/AC Accessory Inverter.  The setting may be requested by a separate device (via SPN 9283) o...";
CM_ SG_ 2566629118 DCACAssIvt3DCSdCtMLtStt "DC/AC Accessory Inverter 3 DC Side Current Minimum Limit Setting: Reports the active minimum limit on the DC Side input current of the DC/AC Accessory Inverter.  The setting may be requested by a separate device (via SPN 9542) or determined by the DC...";
CM_ SG_ 2566629118 DCACAssIvt3DCSdCtMxLtStt "DC/AC Accessory Inverter 3 DC Side Current Maximum Limit Setting: Reports the active maximum limit on the DC Side input current of the DC/AC Accessory Inverter.  The setting may be requested by a separate device (via SPN 9282) or determined by the DC...";
CM_ SG_ 2566629118 DCACAssIvt3DCSdVtMLtStt "DC/AC Accessory Inverter 3 DC Side Voltage Minimum Limit Setting: Reports the active minimum limit on the DC Side input voltage of the DC/AC Accessory Inverter.  The setting may be requested by a separate device (via SPN 9281) or determined by the DC...";
CM_ SG_ 2566629118 DCACAssIvt3DCSdVtMxLtStt "DC/AC Accessory Inverter 3 DC Side Voltage Maximum Limit Setting: Reports the active maximum limit on the DC Side input voltage of the DC/AC Accessory Inverter.  The setting may be requested by a separate device (via SPN 9541 or determined by the DC/...";
CM_ BO_ 2566629374 "DC/AC Accessory Inverter 3 Lifetime Data";
CM_ SG_ 2566629374 DCACAssrInvrtr3TtlDCInptChrg "DC/AC Accessory Inverter 3 Total DC Input Charge : Total lifetime charge converted by the DC/AC from the DC Side.  ";
CM_ SG_ 2566629374 DCACAssrInvrtr3TtlDCInptEnrg "DC/AC Accessory Inverter 3 Total DC Input Energy : Total lifetime energy converted by the DC/AC from the DC Side.";
CM_ BO_ 2566629630 "DC/AC Accessory Inverter 4 Temperatures";
CM_ SG_ 2566629630 DCACAssIvt4IvtEtFtTpt "DC/AC Accessory Inverter 4 Inverter Electronic Filter Temperature: Temperature of the electronic components that make up the DC/AC Accessory Inverter filter.";
CM_ SG_ 2566629630 DCACAssrInvrtr4ClntInTmprtr "DC/AC Accessory Inverter 4 Coolant  In Temperature: Temperature of the DC/AC Accessory Inverter Coolant measured at the input of the accessory inverter.";
CM_ SG_ 2566629630 DCACAssrInvrtr4ClntOtTmprtr "DC/AC Accessory Inverter 4 Coolant Out Temperature: Temperature of the DC/AC Accessory Inverter Coolant measured at the output of the accessory inverter.";
CM_ SG_ 2566629630 DCACAssrInvrtr4CntrllrTmprtr "DC/AC Accessory Inverter 4 Controller Temperature: Temperature of the DC/AC Accessory Inverter (e.g, controller, circuit board, enclosure).";
CM_ SG_ 2566629630 DCACAssrInvrtr4PwrEltrnsTmprtr "DC/AC Accessory Inverter 4 Power Electronics Temperature: Temperature of the DC/AC Accessory Inverter power electronics components (e.g, switch or heatsink).";
CM_ BO_ 2566630398 "DC/AC Accessory Inverter 4 Configuration 1";
CM_ SG_ 2566630398 DCACAssIvt4ACSdDtFqCdStt "DC/AC Accessory Inverter 4 AC Side Default Frequency Command Setting: Reports the active AC Side Default Frequency Command Setting of the DC/AC Accessory Inverter.  The setting may be requested by a separate device (via SPN 9526).Note: Report Not Ava...";
CM_ SG_ 2566630398 DCACAssIvt4ACSdRMSCtMxLtStt "DC/AC Accessory Inverter 4 AC Side RMS Current Maximum Limit Setting: Reports the active maximum limit on the AC side output RMS line current of the DC/AC Accessory Inverter.  The setting may be requested by a separate device (via SPN 9314) or determ...";
CM_ SG_ 2566630398 DCACAssIvt4ACSdRMSVtMxLtStt "DC/AC Accessory Inverter 4 AC Side RMS Voltage Maximum Limit Setting: Reports the active maximum limit on the AC Side output line to line RMS voltage of the DC/AC Accessory Inverter.  The setting may be requested by a separate device (via SPN 9313) o...";
CM_ SG_ 2566630398 DCACAssIvt4DCSdCtMLtStt "DC/AC Accessory Inverter 4 DC Side Current Minimum Limit Setting: Reports the active minimum limit on the DC Side input current of the DC/AC Accessory Inverter.  The setting may be requested by a separate device (via SPN 9548) or determined by the DC...";
CM_ SG_ 2566630398 DCACAssIvt4DCSdCtMxLtStt "DC/AC Accessory Inverter 4 DC Side Current Maximum Limit Setting: Reports the active maximum limit on the DC Side input current of the DC/AC Accessory Inverter.  The setting may be requested by a separate device (via SPN 9312) or determined by the DC...";
CM_ SG_ 2566630398 DCACAssIvt4DCSdVtMLtStt "DC/AC Accessory Inverter 4 DC Side Voltage Minimum Limit Setting: Reports the active minimum limit on the DC Side input voltage of the DC/AC Accessory Inverter.  The setting may be requested by a separate device (via SPN 9311) or determined by the DC...";
CM_ SG_ 2566630398 DCACAssIvt4DCSdVtMxLtStt "DC/AC Accessory Inverter 4 DC Side Voltage Maximum Limit Setting: Reports the active maximum limit on the DC Side input voltage of the DC/AC Accessory Inverter.  The setting may be requested by a separate device (via SPN 9547) or determined by the DC...";
CM_ BO_ 2566630654 "DC/AC Accessory Inverter 4 Lifetime Data";
CM_ SG_ 2566630654 DCACAssrInvrtr4TtlDCInptChrg "DC/AC Accessory Inverter 4 Total DC Input Charge : Total lifetime charge converted by the DC/AC from the DC Side.  ";
CM_ SG_ 2566630654 DCACAssrInvrtr4TtlDCInptEnrg "DC/AC Accessory Inverter 4 Total DC Input Energy : Total lifetime energy converted by the DC/AC from the DC Side.";
CM_ BO_ 2566630910 "DC/AC Accessory Inverter 5 Temperatures";
CM_ SG_ 2566630910 DCACAssIvt5IvtEtFtTpt "DC/AC Accessory Inverter 5 Inverter Electronic Filter Temperature: Temperature of the electronic components that make up the DC/AC Accessory Inverter filter.";
CM_ SG_ 2566630910 DCACAssrInvrtr5ClntInTmprtr "DC/AC Accessory Inverter 5 Coolant  In Temperature: Temperature of the DC/AC Accessory Inverter Coolant measured at the input of the accessory inverter.";
CM_ SG_ 2566630910 DCACAssrInvrtr5ClntOtTmprtr "DC/AC Accessory Inverter 5 Coolant Out Temperature: Temperature of the DC/AC Accessory Inverter Coolant measured at the output of the accessory inverter.";
CM_ SG_ 2566630910 DCACAssrInvrtr5CntrllrTmprtr "DC/AC Accessory Inverter 5 Controller Temperature: Temperature of the DC/AC Accessory Inverter (e.g, controller, circuit board, enclosure).";
CM_ SG_ 2566630910 DCACAssrInvrtr5PwrEltrnsTmprtr "DC/AC Accessory Inverter 5 Power Electronics Temperature: Temperature of the DC/AC Accessory Inverter power electronics components (e.g, switch or heatsink).";
CM_ BO_ 2566631678 "DC/AC Accessory Inverter 5 Configuration 1";
CM_ SG_ 2566631678 DCACAssIvt5ACSdDtFqCdStt "DC/AC Accessory Inverter 5 AC Side Default Frequency Command Setting: Reports the active AC Side Default Frequency Command Setting of the DC/AC Accessory Inverter.  The setting may be requested by a separate device (via SPN 9527).Note: Report Not Ava...";
CM_ SG_ 2566631678 DCACAssIvt5ACSdRMSCtMxLtStt "DC/AC Accessory Inverter 5 AC Side RMS Current Maximum Limit Setting: Reports the active maximum limit on the AC side output RMS line current of the DC/AC Accessory Inverter.  The setting may be requested by a separate device (via SPN 9360) or determ...";
CM_ SG_ 2566631678 DCACAssIvt5ACSdRMSVtMxLtStt "DC/AC Accessory Inverter 5 AC Side RMS Voltage Maximum Limit Setting: Reports the active maximum limit on the AC Side output line to line RMS voltage of the DC/AC Accessory Inverter.  The setting may be requested by a separate device (via SPN 9359) o...";
CM_ SG_ 2566631678 DCACAssIvt5DCSdCtMLtStt "DC/AC Accessory Inverter 5 DC Side Current Minimum Limit Setting: Reports the active minimum limit on the DC Side input current of the DC/AC Accessory Inverter.  The setting may be requested by a separate device (via SPN 9554) or determined by the DC...";
CM_ SG_ 2566631678 DCACAssIvt5DCSdCtMxLtStt "DC/AC Accessory Inverter 5 DC Side Current Maximum Limit Setting: Reports the active maximum limit on the DC Side input current of the DC/AC Accessory Inverter.  The setting may be requested by a separate device (via SPN 9358) or determined by the DC...";
CM_ SG_ 2566631678 DCACAssIvt5DCSdVtMLtStt "DC/AC Accessory Inverter 5 DC Side Voltage Minimum Limit Setting: Reports the active minimum limit on the DC Side input voltage of the DC/AC Accessory Inverter.  The setting may be requested by a separate device (via SPN 9357) or determined by the DC...";
CM_ SG_ 2566631678 DCACAssIvt5DCSdVtMxLtStt "DC/AC Accessory Inverter 5 DC Side Voltage Maximum Limit Setting: Reports the active maximum limit on the DC Side input voltage of the DC/AC Accessory Inverter.  The setting may be requested by a separate device (via SPN 9553) or determined by the DC...";
CM_ BO_ 2566631934 "DC/AC Accessory Inverter 5 Lifetime Data";
CM_ SG_ 2566631934 DCACAssrInvrtr5TtlDCInptChrg "DC/AC Accessory Inverter 5 Total DC Input Charge : Total lifetime charge converted by the DC/AC from the DC Side.  ";
CM_ SG_ 2566631934 DCACAssrInvrtr5TtlDCInptEnrg "DC/AC Accessory Inverter 5 Total DC Input Energy : Total lifetime energy converted by the DC/AC from the DC Side.";
CM_ BO_ 2566632190 "Well Stimulation Pump Sensor Calibration Status";
CM_ SG_ 2566632190 WllStmltnPmpStnPrssrClrtnStPnt "Well Stimulation Pump Suction Pressure Calibration Set Point: Specifies the current suction pressure whose calibration status is being reported. Multipoint calibration of the suction pressure system is performed by increasing the pressure with up to ...";
CM_ SG_ 2566632190 WSttPpDsPssCtStPt "Well Stimulation Pump Discharge Pressure Calibration Set Point: Specifies the current discharge pressure whose calibration status is being reported. Multipoint calibration of the discharge pressure system is performed by increasing the pressure with ...";
CM_ SG_ 2566632190 WSttPpDsPssCtStPtStts "Well Stimulation Pump Discharge Pressure Calibration Set Point Status: Indicates the state of the Calibrated Sensor.00b = Not OK01b = OK10b = Error11b = Not available";
CM_ SG_ 2566632190 WSttPpStPssCtStPtStts "Well Stimulation Pump Suction Pressure Calibration Set Point Status: Indicates the state of the Calibrated Sensor.00b = Not OK01b = OK10b = Error11b = Not available";
CM_ BO_ 2566632446 "Well Stimulation Pump Fluid Volume";
CM_ SG_ 2566632446 WllStmltnPmpTrpFldPmpd "Well Stimulation Pump Trip Fluid Pumped: Fluid pumped during all or part of a well stimulation operation.";
CM_ SG_ 2566632446 WllStmltnPmpTtlFldPmpd "Well Stimulation Pump Total Fluid Pumped: Accumulated amount of fluid pumped during well stimulation operation.";
CM_ BO_ 2566632702 "Well Stimulation Pump Serial Number";
CM_ SG_ 2566632702 WllStmltnPmpFldEndSrlNmr "Well Stimulation Pump Fluid End Serial Number: The serial number of the fluid end of a well stimulation pump.";
CM_ SG_ 2566632702 WllStmltnPmpPwrEndSrlNmr "Well Stimulation Pump Power End Serial Number: The serial number of the power end of a well stimulation pump.";
CM_ BO_ 2566632958 "Well Stimulation Pump Trip Hours";
CM_ SG_ 2566632958 WllStmltnPmpFldEndTrpHrs "Well Stimulation Pump Fluid End Trip Hours: The hours accumulated since the last fluid end replacement on the well stimulation pump (since the last reset of the trip meter).This value will be reset by the user.";
CM_ SG_ 2566632958 WllStmltnPmpPwrEndTrpHrs "Well Stimulation Pump Power End Trip Hours: The hours accumulated since the last power end replacement on the well stimulation pump (since the last reset of the trip meter).This value will be reset by the user.";
CM_ BO_ 2566633214 "Aftertreatment 1 Outlet Gas 4";
CM_ SG_ 2566633214 Aftrtrtmnt1OtltOxgnPmpngCrrnt "Aftertreatment 1 Outlet Oxygen Pumping Current: Electrical pumping current directly measured from a Lambda sensor for the purpose of calculating an air/fuel ratio.  This sensor is located closest to the outlet of aftertreatment 1 system.Negative elec...";
CM_ SG_ 2566633214 Atttt1OttNOxSsPttAPssAst "Aftertreatment 1 Outlet NOx Sensor Protection Air Pressure (Absolute): The absolute pressure of the air supplied for the outlet NOx sensor protection of aftertreatment 1.";
CM_ BO_ 2566633470 "Aftertreatment 1 Intake Gas 4";
CM_ SG_ 2566633470 Aftrtrtmnt1IntkOxgnPmpngCrrnt "Aftertreatment 1 Intake Oxygen Pumping Current: Electrical pumping current directly measured from a Lambda sensor for the purpose of calculating an air/fuel ratio.  This sensor is located furthest upstream of the intake of aftertreatment 1 system.Neg...";
CM_ SG_ 2566633470 Atttt1ItNOxSsPttAPssAst "Aftertreatment 1 Intake NOx Sensor Protection Air Pressure (Absolute): The absolute pressure of the air supplied for the intake NOx sensor protection of aftertreatment 1.";
CM_ BO_ 2566633726 "DC/DC Converter 4 Lifetime Data";
CM_ SG_ 2566633726 DCDC4TotalHighSideCharge "DC/DC 4 Total High Side Charge: Indicates the total lifetime charge converted by the DC/DC from the high side (e.g. HVES) during buck mode.  ";
CM_ SG_ 2566633726 DCDC4TotalHighSideEnergy "DC/DC 4 Total High Side Energy: Indicates the total lifetime energy converted by the DC/DC from the high side (e.g. HVES) during buck mode.";
CM_ SG_ 2566633726 DCDC4TotalLowSideCharge "DC/DC 4 Total Low Side Charge: Indicates the total lifetime charge converted by the DC/DC  from the low side (e.g. SLI battery) during boost mode.";
CM_ SG_ 2566633726 DCDC4TotalLowSideEnergy "DC/DC 4 Total Low Side Energy: Indicates the total lifetime energy converted by the DC/DC  from the low side (e.g. SLI battery) during boost mode.";
CM_ BO_ 2566633982 "DC/DC Converter 4 Configuration 1";
CM_ SG_ 2566633982 DCDC4HghSdCrrntMxmmLmtSttng "DC/DC 4 High Side Current Maximum Limit Setting: Reports the active maximum limit on the high side current of the DC/DC Converter.  The setting may be requested by a separate device (see SPN 9056) or determined by the DC/DC Controller based on operat...";
CM_ SG_ 2566633982 DCDC4HghSdVltgMnmmLmtSttng "DC/DC 4 High Side Voltage Minimum Limit Setting: Reports the active minimum limit on the high side voltage of the DC/DC Converter.  The setting may be requested by a separate device (see SPN 9054) or determined by the DC/DC Controller based on operat...";
CM_ SG_ 2566633982 DCDC4HghSdVltgMxmmLmtSttng "DC/DC 4 High Side Voltage Maximum Limit Setting: Reports the active maximum limit on the high side voltage of the DC/DC Converter.  The setting may be requested by a separate device (see SPN 9055) or determined by the DC/DC Controller based on operat...";
CM_ SG_ 2566633982 DCDC4LwSdCrrntMxmmLmtSttng "DC/DC 4 Low Side Current Maximum Limit Setting: Reports the active maximum limit on the low side current of the DC/DC Converter.  The setting may be requested by a separate device (see SPN 9053) or determined by the DC/DC Controller based on operatin...";
CM_ SG_ 2566633982 DCDC4LwSdVltgBkDfltSttng "DC/DC 4 Low Side Voltage Buck Default Setting: Reports the converter active Low Side Voltage Buck Default Setting.  The default may be requested by a separate device (via SPN 9518).Note: Report Not Available (FFFFh) when no default has been set.";
CM_ SG_ 2566633982 DCDC4LwSdVltgMnmmLmtSttng "DC/DC 4 Low Side Voltage Minimum Limit Setting: Reports the active minimum limit on the low side voltage of the DC/DC Converter.  The setting may be requested by a separate device(see SPN 9051) or determined by the DC/DC Controller based on operating...";
CM_ SG_ 2566633982 DCDC4LwSdVltgMxmmLmtSttng "DC/DC 4 Low Side Voltage Maximum Limit Setting: Reports the active maximum limit on the low side voltage of the DC/DC Converter.  The setting may be requested by a separate device (see SPN 9052) or determined by the DC/DC Controller based on operatin...";
CM_ SG_ 2566633982 DCDC4SLIBttrTmprtrMxmmLmtSttng "DC/DC 4 SLI Battery Temperature Maximum Limit Setting: Reports the active SLI Battery Temperature maximum limit.  The setting may be requested by a separate device (see SPN 9045) or determined by the DC/DC Controller based on operating conditions.";
CM_ SG_ 2566633982 DCDC4SLIBttTCCtMxLtStt "DC/DC 4 SLI Battery Terminal Charge Current Maximum Limit Setting: Reports the active SLI Battery charging current maximum limit (at the battery terminals).  The setting may be requested by a separate device (see SPN 9044) or determined by the DC/DC ...";
CM_ SG_ 2566633982 DCDC4SLIBttTVtMxLtStt "DC/DC 4 SLI Battery Terminal Voltage Maximum Limit Setting: Reports the active SLI Battery Voltage maximum limit (at the battery terminals).  The setting may be requested by a separate device (see SPN 9043) or determined by the DC/DC Controller based...";
CM_ BO_ 2566635262 "DC/DC Converter 3 Lifetime Data";
CM_ SG_ 2566635262 DCDC3TotalHighSideCharge "DC/DC 3 Total High Side Charge: Indicates the total lifetime charge converted by the DC/DC from the high side (e.g. HVES) during buck mode.  ";
CM_ SG_ 2566635262 DCDC3TotalHighSideEnergy "DC/DC 3 Total High Side Energy: Indicates the total lifetime energy converted by the DC/DC from the high side (e.g. HVES) during buck mode.";
CM_ SG_ 2566635262 DCDC3TotalLowSideCharge "DC/DC 3 Total Low Side Charge: Indicates the total lifetime charge converted by the DC/DC  from the low side (e.g. SLI battery) during boost mode.";
CM_ SG_ 2566635262 DCDC3TotalLowSideEnergy "DC/DC 3 Total Low Side Energy: Indicates the total lifetime energy converted by the DC/DC  from the low side (e.g. SLI battery) during boost mode.";
CM_ BO_ 2566635518 "DC/DC Converter 3 Configuration 1";
CM_ SG_ 2566635518 DCDC3HghSdCrrntMxmmLmtSttng "DC/DC 3 High Side Current Maximum Limit Setting: Reports the active maximum limit on the high side current of the DC/DC Converter.  The setting may be requested by a separate device (see SPN 9001) or determined by the DC/DC Controller based on operat...";
CM_ SG_ 2566635518 DCDC3HghSdVltgMnmmLmtSttng "DC/DC 3 High Side Voltage Minimum Limit Setting: Reports the active minimum limit on the high side voltage of the DC/DC Converter.  The setting may be requested by a separate device (see SPN 8999) or determined by the DC/DC Controller based on operat...";
CM_ SG_ 2566635518 DCDC3HghSdVltgMxmmLmtSttng "DC/DC 3 High Side Voltage Maximum Limit Setting: Reports the active maximum limit on the high side voltage of the DC/DC Converter.  The setting may be requested by a separate device (see SPN 9000) or determined by the DC/DC Controller based on operat...";
CM_ SG_ 2566635518 DCDC3LwSdCrrntMxmmLmtSttng "DC/DC 3 Low Side Current Maximum Limit Setting: Reports the active maximum limit on the low side current of the DC/DC Converter.  The setting may be requested by a separate device (see SPN 8998) or determined by the DC/DC Controller based on operatin...";
CM_ SG_ 2566635518 DCDC3LwSdVltgBkDfltSttng "DC/DC 3 Low Side Voltage Buck Default Setting: Reports the converter active Low Side Voltage Buck Default Setting.  The default may be requested by a separate device (via SPN 9517).Note: Report Not Available (FFFFh) when no default has been set.";
CM_ SG_ 2566635518 DCDC3LwSdVltgMnmmLmtSttng "DC/DC 3 Low Side Voltage Minimum Limit Setting: Reports the active minimum limit on the low side voltage of the DC/DC Converter.  The setting may be requested by a separate device(see SPN 8996) or determined by the DC/DC Controller based on operating...";
CM_ SG_ 2566635518 DCDC3LwSdVltgMxmmLmtSttng "DC/DC 3 Low Side Voltage Maximum Limit Setting: Reports the active maximum limit on the low side voltage of the DC/DC Converter.  The setting may be requested by a separate device (see SPN 8997) or determined by the DC/DC Controller based on operatin...";
CM_ SG_ 2566635518 DCDC3SLIBttrTmprtrMxmmLmtSttng "DC/DC 3 SLI Battery Temperature Maximum Limit Setting: Reports the active SLI Battery Temperature maximum limit.  The setting may be requested by a separate device (see SPN 8990) or determined by the DC/DC Controller based on operating conditions.";
CM_ SG_ 2566635518 DCDC3SLIBttTCCtMxLtStt "DC/DC 3 SLI Battery Terminal Charge Current Maximum Limit Setting: Reports the active SLI Battery charging current maximum limit (at the battery terminals).  The setting may be requested by a separate device (see SPN 8989) or determined by the DC/DC ...";
CM_ SG_ 2566635518 DCDC3SLIBttTVtMxLtStt "DC/DC 3 SLI Battery Terminal Voltage Maximum Limit Setting: Reports the active SLI Battery Voltage maximum limit (at the battery terminals).  The setting may be requested by a separate device (see SPN 8988) or determined by the DC/DC Controller based...";
CM_ BO_ 2566636798 "DC/DC Converter 2 Lifetime Data";
CM_ SG_ 2566636798 DCDC2TotalHighSideCharge "DC/DC 2 Total High Side Charge: Indicates the total lifetime charge converted by the DC/DC from the high side (e.g. HVES) during buck mode.  ";
CM_ SG_ 2566636798 DCDC2TotalHighSideEnergy "DC/DC 2 Total High Side Energy: Indicates the total lifetime energy converted by the DC/DC from the high side (e.g. HVES) during buck mode.";
CM_ SG_ 2566636798 DCDC2TotalLowSideCharge "DC/DC 2 Total Low Side Charge: Indicates the total lifetime charge converted by the DC/DC  from the low side (e.g. SLI battery) during boost mode.";
CM_ SG_ 2566636798 DCDC2TotalLowSideEnergy "DC/DC 2 Total Low Side Energy: Indicates the total lifetime energy converted by the DC/DC  from the low side (e.g. SLI battery) during boost mode.";
CM_ BO_ 2566637054 "DC/DC Converter 2 Configuration 1";
CM_ SG_ 2566637054 DCDC2HghSdCrrntMxmmLmtSttng "DC/DC 2 High Side Current Maximum Limit Setting: Reports the active maximum limit on the high side current of the DC/DC Converter.  The setting may be requested by a separate device (see SPN 8946) or determined by the DC/DC Controller based on operat...";
CM_ SG_ 2566637054 DCDC2HghSdVltgMnmmLmtSttng "DC/DC 2 High Side Voltage Minimum Limit Setting: Reports the active minimum limit on the high side voltage of the DC/DC Converter.  The setting may be requested by a separate device (see SPN 8944) or determined by the DC/DC Controller based on operat...";
CM_ SG_ 2566637054 DCDC2HghSdVltgMxmmLmtSttng "DC/DC 2 High Side Voltage Maximum Limit Setting: Reports the active maximum limit on the high side voltage of the DC/DC Converter.  The setting may be requested by a separate device (see SPN 8945) or determined by the DC/DC Controller based on operat...";
CM_ SG_ 2566637054 DCDC2LwSdCrrntMxmmLmtSttng "DC/DC 2 Low Side Current Maximum Limit Setting: Reports the active maximum limit on the low side current of the DC/DC Converter.  The setting may be requested by a separate device (see SPN 8943) or determined by the DC/DC Controller based on operatin...";
CM_ SG_ 2566637054 DCDC2LwSdVltgBkDfltSttng "DC/DC 2 Low Side Voltage Buck Default Setting: Reports the converter active Low Side Voltage Buck Default Setting.  The default may be requested by a separate device (via SPN 9516).Note: Report Not Available (FFFFh) when no default has been set.";
CM_ SG_ 2566637054 DCDC2LwSdVltgMnmmLmtSttng "DC/DC 2 Low Side Voltage Minimum Limit Setting: Reports the active minimum limit on the low side voltage of the DC/DC Converter.  The setting may be requested by a separate device(see SPN 8941) or determined by the DC/DC Controller based on operating...";
CM_ SG_ 2566637054 DCDC2LwSdVltgMxmmLmtSttng "DC/DC 2 Low Side Voltage Maximum Limit Setting: Reports the active maximum limit on the low side voltage of the DC/DC Converter.  The setting may be requested by a separate device (see SPN 8942) or determined by the DC/DC Controller based on operatin...";
CM_ SG_ 2566637054 DCDC2SLIBttrTmprtrMxmmLmtSttng "DC/DC 2 SLI Battery Temperature Maximum Limit Setting: Reports the active SLI Battery Temperature maximum limit.  The setting may be requested by a separate device (see SPN 8935) or determined by the DC/DC Controller based on operating conditions.";
CM_ SG_ 2566637054 DCDC2SLIBttTCCtMxLtStt "DC/DC 2 SLI Battery Terminal Charge Current Maximum Limit Setting: Reports the active SLI Battery charging current maximum limit (at the battery terminals).  The setting may be requested by a separate device (see SPN 8934) or determined by the DC/DC ...";
CM_ SG_ 2566637054 DCDC2SLIBttTVtMxLtStt "DC/DC 2 SLI Battery Terminal Voltage Maximum Limit Setting: Reports the active SLI Battery Voltage maximum limit (at the battery terminals).  The setting may be requested by a separate device (see SPN 8933) or determined by the DC/DC Controller based...";
CM_ BO_ 2566638590 "Engine Exhaust Particulate Control System Info";
CM_ SG_ 2566638590 ExhstPrtltCntrlSstmDgnstCnt "Exhaust Particulate Control System Diagnostic Count: The total occurrences of diagnostic codes for the exhaust particulate control system that have been active above a predetermined time threshold. A code that has been active less than the predetermi...";
CM_ SG_ 2566638590 ExhstPrtltCntrlSstmDgnstTm "Exhaust Particulate Control System Diagnostic Time: The total time the exhaust particulate control diagnostic codes have been active. Total time only includes the active time for codes which have been active above a predetermined time threshold. The ...";
CM_ BO_ 2566638846 "Well Stimulation Pump Hours";
CM_ SG_ 2566638846 WllStmltnPmpMntnnIntrvlHrs "Well Stimulation Pump Maintenance Interval Hours: The hours accumulated since the last maintenance interval on the well stimulation pump.";
CM_ SG_ 2566638846 WllStmltnPmpPkngOprtnHrs "Well Stimulation Pump Packing Operation Hours: The hours accumulated since the last time a packing replacement was performed on the well stimulation pump.";
CM_ SG_ 2566638846 WllStmltnPmpVlvOprtnHrs "Well Stimulation Pump Valve Operation Hours: The hours accumulated since the last time a valve replacement was performed on the well stimulation pump.";
CM_ SG_ 2566638846 WllStmltnPmpVlvStOprtnHrs "Well Stimulation Pump Valve Seat Operation Hours: The hours accumulated since the last time a valve seat replacement was performed on the well stimulation pump.";
CM_ BO_ 2566639102 "Well Stimulation Pump System Configuration Status";
CM_ SG_ 2566639102 WllStmltnPmpPlngrFrngOrdrSttng "Well Stimulation Pump Plunger Firing Order Setting: Well stimulation pump plunger firing order0000b = Firing order 1-2-30001b = Firing order 1-5-2-3-40010b = Reserved0011b = Reserved0100b = Reserved0101b = Reserved0110b = Reserved0111b = Reserved1000...";
CM_ SG_ 2566639102 WllStmltnPmpRdLdHghThrshldSttng "Well Stimulation Pump Rod Load High Threshold Setting: Rod load force at which the rod load is considered at the highest acceptable force.";
CM_ SG_ 2566639102 WSttPpCstSpdHTsdStt "Well Stimulation Pump Crankshaft Speed High Threshold Setting: Configurable well stimulation pump crankshaft speed that has been considered to be the highest acceptable speed.";
CM_ SG_ 2566639102 WSttPpCstSpdLwTsdStt "Well Stimulation Pump Crankshaft Speed Low Threshold Setting: Configurable well stimulation pump crankshaft speed that has been considered to be the lowest acceptable speed.";
CM_ SG_ 2566639102 WSttPpDsPssHTsdStt "Well Stimulation Pump Discharge Pressure High Threshold Setting: Configurable pressure at which the discharge pressure is considered at the highest acceptable pressure.";
CM_ SG_ 2566639102 WSttPpGBxOPssHTsdStt "Well Stimulation Pump Gear Box Oil Pressure High Threshold Setting: Configurable pressure at which the gearbox oil pressure is considered at the highest acceptable pressure.";
CM_ SG_ 2566639102 WSttPpGBxOPssLwTsdStt "Well Stimulation Pump Gear Box Oil Pressure Low Threshold Setting: Configurable pressure at which the gearbox oil pressure is considered at the lowest acceptable pressure.";
CM_ SG_ 2566639102 WSttPpGBxOTptHTsdStt "Well Stimulation Pump Gear Box Oil Temperature High Threshold Setting: Configurable temperature at which the gearbox oil temperature is considered at the highest acceptable temperature.";
CM_ SG_ 2566639102 WSttPpGBxOTptLwTsdStt "Well Stimulation Pump Gear Box Oil Temperature Low Threshold Setting: Configurable temperature at which the gearbox oil temperature is considered at the lowest acceptable temperature.";
CM_ SG_ 2566639102 WSttPpStPssHTsdStt "Well Stimulation Pump Suction Pressure High Threshold Setting: Configurable pressure at which the suction pressure is considered at the highest acceptable pressure.";
CM_ SG_ 2566639102 WSttPpStPssLwTsdStt "Well Stimulation Pump Suction Pressure Low Threshold Setting: Configurable pressure at which the suction pressure is considered at the lowest acceptable pressure.";
CM_ BO_ 2566639614 "DC/DC Converter 1 Lifetime Data";
CM_ SG_ 2566639614 DCDC1TotalHighSideCharge "DC/DC 1 Total High Side Charge: Indicates the total lifetime charge converted by the DC/DC from the high side (e.g. HVES) during buck mode.  ";
CM_ SG_ 2566639614 DCDC1TotalHighSideEnergy "DC/DC 1 Total High Side Energy: Indicates the total lifetime energy converted by the DC/DC from the high side (e.g. HVES) during buck mode.";
CM_ SG_ 2566639614 DCDC1TotalLowSideCharge "DC/DC 1 Total Low Side Charge: Indicates the total lifetime charge converted by the DC/DC  from the low side (e.g. SLI battery) during boost mode.";
CM_ SG_ 2566639614 DCDC1TotalLowSideEnergy "DC/DC 1 Total Low Side Energy: Indicates the total lifetime energy converted by the DC/DC  from the low side (e.g. SLI battery) during boost mode.";
CM_ BO_ 2566639870 "DC/DC Converter 1 Configuration 1";
CM_ SG_ 2566639870 DCDC1HghSdCrrntMxmmLmtSttng "DC/DC 1 High Side Current Maximum Limit Setting: Reports the active maximum limit on the high side current of the DC/DC Converter.  The setting may be requested by a separate device (via SPN 8565) or determined by the DC/DC Controller based on operat...";
CM_ SG_ 2566639870 DCDC1HghSdVltgMnmmLmtSttng "DC/DC 1 High Side Voltage Minimum Limit Setting: Reports the active minimum limit on the high side voltage of the DC/DC Converter.  The setting may be requested by a separate device (via SPN 8563) or determined by the DC/DC Controller based on operat...";
CM_ SG_ 2566639870 DCDC1HghSdVltgMxmmLmtSttng "DC/DC 1 High Side Voltage Maximum Limit Setting: Reports the active maximum limit on the high side voltage of the DC/DC Converter.  The setting may be requested by a separate device (via SPN 8564) or determined by the DC/DC Controller based on operat...";
CM_ SG_ 2566639870 DCDC1LwSdCrrntMxmmLmtSttng "DC/DC 1 Low Side Current Maximum Limit Setting: Reports the active maximum limit on the low side current of the DC/DC Converter.  The setting may be requested by a separate device (via SPN 8568) or determined by the DC/DC Controller based on operatin...";
CM_ SG_ 2566639870 DCDC1LwSdVltgBkDfltSttng "DC/DC 1 Low Side Voltage Buck Default Setting: Reports the converter active Low Side Voltage Buck Default Setting.  The default may be requested by a separate device (via SPN 9515).Note: Report Not Available (FFFFh) when no default has been set.";
CM_ SG_ 2566639870 DCDC1LwSdVltgMnmmLmtSttng "DC/DC 1 Low Side Voltage Minimum Limit Setting: Reports the active minimum limit on the low side voltage of the DC/DC Converter.  The setting may be requested by a separate device (via SPN 8566) or determined by the DC/DC Controller based on operatin...";
CM_ SG_ 2566639870 DCDC1LwSdVltgMxmmLmtSttng "DC/DC 1 Low Side Voltage Maximum Limit Setting: Reports the active maximum limit on the low side voltage of the DC/DC Converter.  The setting may be requested by a separate device (via SPN 8567) or determined by the DC/DC Controller based on operatin...";
CM_ SG_ 2566639870 DCDC1SLIBttrTmprtrMxmmLmtSttng "DC/DC 1 SLI Battery Temperature Maximum Limit Setting: Reports the active SLI Battery Temperature maximum limit.  The setting may be requested by a separate device (via SPN 8819) or determined by the DC/DC Controller based on operating conditions.";
CM_ SG_ 2566639870 DCDC1SLIBttTCCtMxLtStt "DC/DC 1 SLI Battery Terminal Charge Current Maximum Limit Setting: Reports the active SLI Battery charging current maximum limit (at the battery terminals).  The setting may be requested by a separate device (via SPN 8818) or determined by the DC/DC ...";
CM_ SG_ 2566639870 DCDC1SLIBttTVtMxLtStt "DC/DC 1 SLI Battery Terminal Voltage Maximum Limit Setting: Reports the active SLI Battery Voltage maximum limit (at the battery terminals).  The setting may be requested by a separate device (via SPN 8817) or determined by the DC/DC Controller based...";
CM_ BO_ 2566640382 "Pump Oil Message";
CM_ SG_ 2566640382 WellStimulationPumpOilDensity "Well Stimulation Pump Oil Density: Density of the well stimulation pump oil.";
CM_ SG_ 2566640382 WellStimulationPumpOilViscosity "Well Stimulation Pump Oil Viscosity: Dynamic viscosity of the well stimulation pump oil.";
CM_ SG_ 2566640382 WllStmltnPmpOlRltvDltrt "Well Stimulation Pump Oil Relative Dielectricity: Well stimulation pump oil relative dielectricity used to describe the well stimulation pump oil quality.";
CM_ SG_ 2566640382 WllStmltnPmpOlTmprtr "Well Stimulation Pump Oil Temperature: Temperature of the well stimulation pump lubricant.";
CM_ BO_ 2566641150 "Aftercooler and Oil Cooler Fluids 2";
CM_ SG_ 2566641150 AltrntrBrngHdrIntkPrssr "Alternator Bearing Header Intake Pressure: Pressure of the lube oil at the intake of alternator bearing header.";
CM_ SG_ 2566641150 AltrntrOlClrDshrgPmpPrssr "Alternator Oil Cooler Discharge Pump Pressure: Pressure of the lube oil at the alternator oil cooler discharge pump.";
CM_ SG_ 2566641150 EngnOlClrDshrgPmpPrssr "Engine Oil Cooler Discharge Pump Pressure: Pressure of the lube oil at engine oil cooler discharge pump.";
CM_ SG_ 2566641150 EngnOlClrIntkTmprtr "Engine Oil Cooler Intake Temperature: Temperature of lube oil at engine cooler intake.";
CM_ BO_ 2566641406 "Electronic Engine Controller 21";
CM_ SG_ 2566641406 EngnExhstMnfldAsltPrssr1 "Engine Exhaust Manifold Absolute Pressure 1: Absolute pressure of the exhaust gasses as measured at the engine exhaust manifold, location 1.";
CM_ SG_ 2566641406 EngnExhstMnfldAsltPrssr2 "Engine Exhaust Manifold Absolute Pressure 2: Absolute pressure of the exhaust gasses as measured at the engine exhaust manifold, location 2.";
CM_ BO_ 2566642942 "Door Control 4";
CM_ SG_ 2566642942 EnableStatusofDoor21 "Enable Status of Door 21: Enable status of bus door 21.  Enabled means the bus doors are able to be automatically opened or closed.00b = Door disabled01b = Door enabled10b = Error11b = Not available";
CM_ SG_ 2566642942 EnableStatusofDoor22 "Enable Status of Door 22: Enable status of bus door 22.  Enabled means the bus doors are able to be automatically opened or closed.00b = Door disabled01b = Door enabled10b = Error11b = Not available";
CM_ SG_ 2566642942 EnableStatusofDoor23 "Enable Status of Door 23: Enable status of bus door 23.  Enabled means the bus doors are able to be automatically opened or closed.00b = Door disabled01b = Door enabled10b = Error11b = Not available";
CM_ SG_ 2566642942 EnableStatusofDoor24 "Enable Status of Door 24: Enable status of bus door 24.  Enabled means the bus doors are able to be automatically opened or closed.00b = Door disabled01b = Door enabled10b = Error11b = Not available";
CM_ SG_ 2566642942 EnableStatusofDoor25 "Enable Status of Door 25: Enable status of bus door 25.  Enabled means the bus doors are able to be automatically opened or closed.00b = Door disabled01b = Door enabled10b = Error11b = Not available";
CM_ SG_ 2566642942 EnableStatusofDoor26 "Enable Status of Door 26: Enable status of bus door 26.  Enabled means the bus doors are able to be automatically opened or closed.00b = Door disabled01b = Door enabled10b = Error11b = Not available";
CM_ SG_ 2566642942 EnableStatusofDoor27 "Enable Status of Door 27: Enable status of bus door 27.  Enabled means the bus doors are able to be automatically opened or closed.00b = Door disabled01b = Door enabled10b = Error11b = Not available";
CM_ SG_ 2566642942 EnableStatusofDoor28 "Enable Status of Door 28: Enable status of bus door 28.  Enabled means the bus doors are able to be automatically opened or closed.00b = Door disabled01b = Door enabled10b = Error11b = Not available";
CM_ SG_ 2566642942 EnableStatusofDoor29 "Enable Status of Door 29: Enable status of bus door 29.  Enabled means the bus doors are able to be automatically opened or closed.00b = Door disabled01b = Door enabled10b = Error11b = Not available";
CM_ SG_ 2566642942 EnableStatusofDoor30 "Enable Status of Door 30: Enable status of bus door 30.  Enabled means the bus doors are able to be automatically opened or closed.00b = Door disabled01b = Door enabled10b = Error11b = Not available";
CM_ SG_ 2566642942 LockStatusofDoor21 "Lock Status of Door 21: Lock status of bus door 2100b = Unlocked01b = Locked10b = Error11b = Not available";
CM_ SG_ 2566642942 LockStatusofDoor22 "Lock Status of Door 22: Lock status of bus door 2200b = Unlocked01b = Locked10b = Error11b = Not available";
CM_ SG_ 2566642942 LockStatusofDoor23 "Lock Status of Door 23: Lock status of bus door 2300b = Unlocked01b = Locked10b = Error11b = Not available";
CM_ SG_ 2566642942 LockStatusofDoor24 "Lock Status of Door 24: Lock status of bus door 2400b = Unlocked01b = Locked10b = Error11b = Not available";
CM_ SG_ 2566642942 LockStatusofDoor25 "Lock Status of Door 25: Lock status of bus door 2500b = Unlocked01b = Locked10b = Error11b = Not available";
CM_ SG_ 2566642942 LockStatusofDoor26 "Lock Status of Door 26: Lock status of bus door 2600b = Unlocked01b = Locked10b = Error11b = Not available";
CM_ SG_ 2566642942 LockStatusofDoor27 "Lock Status of Door 27: Lock status of bus door 2700b = Unlocked01b = Locked10b = Error11b = Not available";
CM_ SG_ 2566642942 LockStatusofDoor28 "Lock Status of Door 28: Lock status of bus door 2800b = Unlocked01b = Locked10b = Error11b = Not available";
CM_ SG_ 2566642942 LockStatusofDoor29 "Lock Status of Door 29: Lock status of bus door 2900b = Unlocked01b = Locked10b = Error11b = Not available";
CM_ SG_ 2566642942 LockStatusofDoor30 "Lock Status of Door 30: Lock status of bus door 3000b = Unlocked01b = Locked10b = Error11b = Not available";
CM_ SG_ 2566642942 OpenStatusofDoor21 "Open Status of Door 21: Open status of bus door 2100b = Door closed01b = Door opened10b = Error11b = Not available";
CM_ SG_ 2566642942 OpenStatusofDoor22 "Open Status of Door 22: Open status of bus door 2200b = Door closed01b = Door opened10b = Error11b = Not available";
CM_ SG_ 2566642942 OpenStatusofDoor23 "Open Status of Door 23: Open status of bus door 2300b = Door closed01b = Door opened10b = Error11b = Not available";
CM_ SG_ 2566642942 OpenStatusofDoor24 "Open Status of Door 24: Open status of bus door 2400b = Door closed01b = Door opened10b = Error11b = Not available";
CM_ SG_ 2566642942 OpenStatusofDoor25 "Open Status of Door 25: Open status of bus door 2500b = Door closed01b = Door opened10b = Error11b = Not available";
CM_ SG_ 2566642942 OpenStatusofDoor26 "Open Status of Door 26: Open status of bus door 2600b = Door closed01b = Door opened10b = Error11b = Not available";
CM_ SG_ 2566642942 OpenStatusofDoor27 "Open Status of Door 27: Open status of bus door 2700b = Door closed01b = Door opened10b = Error11b = Not available";
CM_ SG_ 2566642942 OpenStatusofDoor28 "Open Status of Door 28: Open status of bus door 2800b = Door closed01b = Door opened10b = Error11b = Not available";
CM_ SG_ 2566642942 OpenStatusofDoor29 "Open Status of Door 29: Open status of bus door 2900b = Door closed01b = Door opened10b = Error11b = Not available";
CM_ SG_ 2566642942 OpenStatusofDoor30 "Open Status of Door 30: Open status of bus door 3000b = Door closed01b = Door opened10b = Error11b = Not available";
CM_ BO_ 2566643198 "Door Control 3";
CM_ SG_ 2566643198 EnableStatusofDoor11 "Enable Status of Door 11: Enable status of bus door 11.  Enabled means the bus doors are able to be automatically opened or closed.00b = Door disabled01b = Door enabled10b = Error11b = Not available";
CM_ SG_ 2566643198 EnableStatusofDoor12 "Enable Status of Door 12: Enable status of bus door 12.  Enabled means the bus doors are able to be automatically opened or closed.00b = Door disabled01b = Door enabled10b = Error11b = Not available";
CM_ SG_ 2566643198 EnableStatusofDoor13 "Enable Status of Door 13: Enable status of bus door 13.  Enabled means the bus doors are able to be automatically opened or closed.00b = Door disabled01b = Door enabled10b = Error11b = Not available";
CM_ SG_ 2566643198 EnableStatusofDoor14 "Enable Status of Door 14: Enable status of bus door 14.  Enabled means the bus doors are able to be automatically opened or closed.00b = Door disabled01b = Door enabled10b = Error11b = Not available";
CM_ SG_ 2566643198 EnableStatusofDoor15 "Enable Status of Door 15: Enable status of bus door 15.  Enabled means the bus doors are able to be automatically opened or closed.00b = Door disabled01b = Door enabled10b = Error11b = Not available";
CM_ SG_ 2566643198 EnableStatusofDoor16 "Enable Status of Door 16: Enable status of bus door 16.  Enabled means the bus doors are able to be automatically opened or closed.00b = Door disabled01b = Door enabled10b = Error11b = Not available";
CM_ SG_ 2566643198 EnableStatusofDoor17 "Enable Status of Door 17: Enable status of bus door 17.  Enabled means the bus doors are able to be automatically opened or closed.00b = Door disabled01b = Door enabled10b = Error11b = Not available";
CM_ SG_ 2566643198 EnableStatusofDoor18 "Enable Status of Door 18: Enable status of bus door 18.  Enabled means the bus doors are able to be automatically opened or closed.00b = Door disabled01b = Door enabled10b = Error11b = Not available";
CM_ SG_ 2566643198 EnableStatusofDoor19 "Enable Status of Door 19: Enable status of bus door 19.  Enabled means the bus doors are able to be automatically opened or closed.00b = Door disabled01b = Door enabled10b = Error11b = Not available";
CM_ SG_ 2566643198 EnableStatusofDoor20 "Enable Status of Door 20: Enable status of bus door 20.  Enabled means the bus doors are able to be automatically opened or closed.00b = Door disabled01b = Door enabled10b = Error11b = Not available";
CM_ SG_ 2566643198 LockStatusofDoor11 "Lock Status of Door 11: Lock status of bus door 1100b = Unlocked 01b = Locked10b = Error11b = Not available";
CM_ SG_ 2566643198 LockStatusofDoor12 "Lock Status of Door 12: Lock status of bus door 1200b = Unlocked01b = Locked10b = Error11b = Not available";
CM_ SG_ 2566643198 LockStatusofDoor13 "Lock Status of Door 13: Lock status of bus door 1300b = Unlocked01b = Locked10b = Error11b = Not available";
CM_ SG_ 2566643198 LockStatusofDoor14 "Lock Status of Door 14: Lock status of bus door 1400b = Unlocked01b = Locked10b = Error11b = Not available";
CM_ SG_ 2566643198 LockStatusofDoor15 "Lock Status of Door 15: Lock status of bus door 1500b = Unlocked01b = Locked10b = Error11b = Not available";
CM_ SG_ 2566643198 LockStatusofDoor16 "Lock Status of Door 16: Lock status of bus door 1600b = Unlocked01b = Locked10b = Error11b = Not available";
CM_ SG_ 2566643198 LockStatusofDoor17 "Lock Status of Door 17: Lock status of bus door 1700b = Unlocked01b = Locked10b = Error11b = Not available";
CM_ SG_ 2566643198 LockStatusofDoor18 "Lock Status of Door 18: Lock status of bus door 1800b = Unlocked01b = Locked10b = Error11b = Not available";
CM_ SG_ 2566643198 LockStatusofDoor19 "Lock Status of Door 19: Lock status of bus door 1900b = Unlocked01b = Locked10b = Error11b = Not available";
CM_ SG_ 2566643198 LockStatusofDoor20 "Lock Status of Door 20: Lock status of bus door 2000b = Unlocked01b = Locked10b = Error11b = Not available";
CM_ SG_ 2566643198 OpenStatusofDoor11 "Open Status of Door 11: Open status of bus door 1100b = Door closed01b = Door opened10b = Error11b = Not available";
CM_ SG_ 2566643198 OpenStatusofDoor12 "Open Status of Door 12: Open status of bus door 1200b = Door closed01b = Door opened10b = Error11b = Not available";
CM_ SG_ 2566643198 OpenStatusofDoor13 "Open Status of Door 13: Open status of bus door 1300b = Door closed01b = Door opened10b = Error11b = Not available";
CM_ SG_ 2566643198 OpenStatusofDoor14 "Open Status of Door 14: Open status of bus door 1400b = Door closed01b = Door opened10b = Error11b = Not available";
CM_ SG_ 2566643198 OpenStatusofDoor15 "Open Status of Door 15: Open status of bus door 1500b = Door closed01b = Door opened10b = Error11b = Not available";
CM_ SG_ 2566643198 OpenStatusofDoor16 "Open Status of Door 16: Open status of bus door 1600b = Door closed01b = Door opened10b = Error11b = Not available";
CM_ SG_ 2566643198 OpenStatusofDoor17 "Open Status of Door 17: Open status of bus door 1700b = Door closed01b = Door opened10b = Error11b = Not available";
CM_ SG_ 2566643198 OpenStatusofDoor18 "Open Status of Door 18: Open status of bus door 1800b = Door closed01b = Door opened10b = Error11b = Not available";
CM_ SG_ 2566643198 OpenStatusofDoor19 "Open Status of Door 19: Open status of bus door 1900b = Door closed01b = Door opened10b = Error11b = Not available";
CM_ SG_ 2566643198 OpenStatusofDoor20 "Open Status of Door 20: Open status of bus door 2000b = Door closed01b = Door opened10b = Error11b = Not available";
CM_ BO_ 2566643454 "Engine Temperature 6";
CM_ SG_ 2566643454 EngineIntakeCoolantTemperature "Engine Intake Coolant Temperature: Temperature of the coolant at the intake of the engine block.";
CM_ SG_ 2566643454 EngnChrgArClrIntkClntTmprtr "Engine Charge Air Cooler Intake Coolant Temperature: Temperature of the fluid in the low temperature circuit measured at the fluid intake of the charge air cooler.";
CM_ SG_ 2566643454 EngnChrgArClrOtltClntTmprtr "Engine Charge Air Cooler Outlet Coolant Temperature: Temperature of the fluid in the low temperature circuit measured at the fluid outlet of the charge air cooler.";
CM_ SG_ 2566643454 EItMdAtSdCtCtCtDtTpt "Engine Intake Manifold Air to Secondary Coolant Circuit Coolant Differential Temperature: Indicates the differential temperature between the engine intake manifold air to secondary coolant circuit coolant.";
CM_ BO_ 2566643710 "Intake/Exhaust Conditions 3";
CM_ SG_ 2566643710 EngineMixer1IntakePressure "Engine Mixer 1 Intake Pressure: The pressure at the intake of the air and fuel mixer.";
CM_ SG_ 2566643710 EngineMixer2IntakePressure "Engine Mixer 2 Intake Pressure: The pressure at the intake of the second air and fuel mixer.";
CM_ SG_ 2566643710 EngnIntkMnfld2AsltPrssrHghRsltn "Engine Intake Manifold 2 Absolute Pressure (High Resolution): The absolute pressure measurement of the air intake manifold for bank 2 or the second air intake manifold.  If there are multiple air pressure sensors in the intake stream, this is the las...";
CM_ SG_ 2566643710 DsrdEngnIntkMnfldPrssrHghLmt "Desired Engine Intake Manifold Pressure High Limit: The desired pressure high limit of the air intake manifold. This SP is a high resolution measurement.";
CM_ BO_ 2566644990 "Fuel Information 7 (Gaseous)";
CM_ SG_ 2566644990 DrvrSdFlRptl1CvrStts "Driver Side Fuel Receptacle 1 Cover Status: Indicates if the cover for the first fuel receptacle on the driver side is attached or detached.00b = Receptacle cover is detached01b = Receptacle cover is attached10b = Error11b = Not available";
CM_ SG_ 2566644990 DrvrSdFlRptl2CvrStts "Driver Side Fuel Receptacle 2 Cover Status: Indicates if the cover for the second fuel receptacle on the driver side is attached or detached.00b = Receptacle cover is detached01b = Receptacle cover is attached10b = Error11b = Not available";
CM_ SG_ 2566644990 FlStrgCmprtmnt1Tmprtr1 "Fuel Storage Compartment 1 Temperature 1: The ambient temperature in the first fuel storage compartment.  If there is more than 1 sensor, then this is the first sensor. Note that this is not the temperature of the fuel in the fuel tank.";
CM_ SG_ 2566644990 FlStrgCmprtmnt1Tmprtr2 "Fuel Storage Compartment 1 Temperature 2: The ambient temperature as measured by the second temperature sensor in the first fuel storage compartment. Note that this is not the temperature of the fuel in the fuel tank.";
CM_ SG_ 2566644990 FlStrgCmprtmnt2Tmprtr1 "Fuel Storage Compartment 2 Temperature 1: The ambient temperature in the second fuel storage compartment.  If there is more than 1 sensor, then this is the first sensor. Note that this is not the temperature of the fuel in the fuel tank.";
CM_ SG_ 2566644990 FlStrgCmprtmnt2Tmprtr2 "Fuel Storage Compartment 2 Temperature 2: The ambient temperature as measured by the second temperature sensor in the second fuel storage compartment. Note that this is not the temperature of the fuel in the fuel tank.";
CM_ SG_ 2566644990 FlStrgCmprtmnt3Tmprtr1 "Fuel Storage Compartment 3 Temperature 1: The ambient temperature in the third fuel storage compartment.  If there is more than 1 sensor, then this is the first sensor. Note that this is not the temperature of the fuel in the fuel tank.";
CM_ SG_ 2566644990 FlStrgCmprtmnt3Tmprtr2 "Fuel Storage Compartment 3 Temperature 2: The ambient temperature as measured by the second temperature sensor in the third fuel storage compartment. Note that this is not the temperature of the fuel in the fuel tank.";
CM_ SG_ 2566644990 FrontFuelReceptacleCoverStatus "Front Fuel Receptacle Cover Status: Indicates if the cover for the fuel receptacle at the front of the vehicle is attached or detached.00b = Receptacle cover is detached01b = Receptacle cover is attached10b = Error11b = Not available";
CM_ SG_ 2566644990 PssngrSdFlRptl1CvrStts "Passenger Side Fuel Receptacle 1 Cover Status: Indicates if the cover for the first fuel receptacle on the passenger side is attached or detached.00b = Receptacle cover is detached01b = Receptacle cover is attached10b = Error11b = Not available...";
CM_ SG_ 2566644990 PssngrSdFlRptl2CvrStts "Passenger Side Fuel Receptacle 2 Cover Status: Indicates if the cover for the second fuel receptacle on the passenger side is attached or detached.00b = Receptacle cover is detached01b = Receptacle cover is attached10b = Error11b = Not available...";
CM_ BO_ 2566645246 "High Voltage Energy Storage System Fan Status";
CM_ SG_ 2566645246 HVESSFanEnableStatus "HVESS Fan Enable Status: Enable and direction status of this HVES fan.00b = Fan Off01b = Fan On - Normal, Forward, or Default Direction10b = Fan On - Reverse Direction11b = Not available";
CM_ SG_ 2566645246 HVESSFanStatusReasonCode "HVESS Fan Status Reason Code: Provides the reason code describing the unique failure of this HVES fan.  If a detailed reason code is not used by the supporting application, or this reason code is Not Available, the SPN 8409 (HVESS Fan Service Indicat...";
CM_ SG_ 2566645246 HVESSFanCommandStatus "HVESS Fan Command Status: Indicates the source of the speed command to this HVES fan.00b is communicated when the fan is self-controlled (e.g. based on a temperature sensor).  01b is communicated when responding to SPN 8386  (HVESS Fan Speed Command)...";
CM_ SG_ 2566645246 HVESSFanSpeed "HVESS Fan Speed: Speed of this HVES fan. ";
CM_ SG_ 2566645246 HVESSFanMediumTemperature "HVESS Fan Medium Temperature: A temperature measured and reported by the device.  It may be used for direct or remote (e.g. by another controller) control of the pump.  For example, this may be the temperature of the fluid flowing through the pump, o...";
CM_ SG_ 2566645246 HVESSFanPower "HVESS Fan Power: Calculated electrical power consumed by this HVES fan.";
CM_ SG_ 2566645246 HVESSFanServiceIndicator "HVESS Fan Service Indicator: Indicates that service is required for this HVES fan.  An active indication may convey a need for component replacement or periodic service.  SPN 8404 (HVESS Fan Status Reason Code) may provide additional detail as to the...";
CM_ SG_ 2566645246 HVESSFanOperatingStatus "HVESS Fan Operating Status: Indicates the operating status of this HVES fan.  This parameter is used to inform other devices that this system or component is no longer performing to its operational capacity and that reduced, or no flow of the medium ...";
CM_ SG_ 2566645246 HVESSFanInstance "HVESS Fan Instance: Indicates the instance of the HVES fan that is providing status in systems controlled by a master ECU.0000b = Instance 10001b = Instance 20010b = Instance 30011b = Instance 40100b = Instance 50101b = Instance 60110b = Instance 701...";
CM_ BO_ 2566646782 "Oil Debris Monitor Counts Ferrous Bins 1 & 2";
CM_ SG_ 2566646782 OlDrsMntrFrrsBn1Cnt "Oil Debris Monitor Ferrous Bin 1 Count: Total number of particles detected in Ferrous bin 1. Bin sizes are application specific.";
CM_ SG_ 2566646782 OlDrsMntrFrrsBn2Cnt "Oil Debris Monitor Ferrous Bin 2 Count: Total number of particles detected in Ferrous bin 2. Bin sizes are application specific.";
CM_ SG_ 2566646782 OlDrsMntrFrrsBns1nd2IdntftnNmr "Oil Debris Monitor Ferrous Bins 1 and 2 Identification Number: Identification number of the Oil Debris Monitoring (ODM) sensor being reported for Ferrous bins 1 and 2. Identification numbers are application specific.";
CM_ BO_ 2566647038 "Oil Debris Monitor Counts Ferrous Bins 3 & 4";
CM_ SG_ 2566647038 OlDrsMntrFrrsBn3Cnt "Oil Debris Monitor Ferrous Bin 3 Count: Total number of particles detected in Ferrous bin 3. Bin sizes are application specific.";
CM_ SG_ 2566647038 OlDrsMntrFrrsBn4Cnt "Oil Debris Monitor Ferrous Bin 4 Count: Total number of particles detected in Ferrous bin 4. Bin sizes are application specific.";
CM_ SG_ 2566647038 OlDrsMntrFrrsBns3nd4IdntftnNmr "Oil Debris Monitor Ferrous Bins 3 and 4 Identification Number: Identification number of the Oil Debris Monitoring (ODM) sensor being reported for Ferrous bins 3 and 4. Identification numbers are application specific.";
CM_ BO_ 2566647294 "Oil Debris Monitor Counts Ferrous Bins 5 & 6";
CM_ SG_ 2566647294 OlDrsMntrFrrsBn5Cnt "Oil Debris Monitor Ferrous Bin 5 Count: Total number of particles detected in Ferrous bin 5. Bin sizes are application specific.";
CM_ SG_ 2566647294 OlDrsMntrFrrsBn6Cnt "Oil Debris Monitor Ferrous Bin 6 Count: Total number of particles detected in Ferrous bin 6. Bin sizes are application specific.";
CM_ SG_ 2566647294 OlDrsMntrFrrsBns5nd6IdntftnNmr "Oil Debris Monitor Ferrous Bins 5 and 6 Identification Number: Identification number of the Oil Debris Monitoring (ODM) sensor being reported for Ferrous bins 5 and 6. Identification numbers are application specific.";
CM_ BO_ 2566647550 "Oil Debris Monitor Counts Non-Ferrous Bins 1 & 2";
CM_ SG_ 2566647550 ODsMtNFsBs1d2IdttN "Oil Debris Monitor Non-Ferrous Bins 1 and 2 Identification Number: Identification number of the Oil Debris Monitoring (ODM) sensor being reported for Non-Ferrous bins 1 and 2.  Identification numbers are application specific.";
CM_ SG_ 2566647550 OlDrsMntrNnFrrsBn1Cnt "Oil Debris Monitor Non-Ferrous Bin 1 Count: Total number of particles detected in Non-Ferrous bin 1. Bin sizes are application specific.";
CM_ SG_ 2566647550 OlDrsMntrNnFrrsBn2Cnt "Oil Debris Monitor Non-Ferrous Bin 2 Count: Total number of particles detected in Non-Ferrous bin 2. Bin sizes are application specific.";
CM_ BO_ 2566647806 "Oil Debris Monitor Counts Non-Ferrous Bins 3 & 4";
CM_ SG_ 2566647806 ODsMtNFsBs3d4IdttN "Oil Debris Monitor Non-Ferrous Bins 3 and 4 Identification Number: Identification number of the Oil Debris Monitoring (ODM) sensor being reported for Non-Ferrous bins 3 and 4. Identification numbers are application specific.";
CM_ SG_ 2566647806 OlDrsMntrNnFrrsBn3Cnt "Oil Debris Monitor Non-Ferrous Bin 3 Count: Total number of particles detected in Non-Ferrous bin 3. Bin sizes are application specific.";
CM_ SG_ 2566647806 OlDrsMntrNnFrrsBn4Cnt "Oil Debris Monitor Non-Ferrous Bin 4 Count: Total number of particles detected in Non-Ferrous bin 4. Bin sizes are application specific.";
CM_ BO_ 2566648062 "Oil Debris Monitor Counts Non-Ferrous Bins 5 & 6";
CM_ SG_ 2566648062 ODsMtNFsBs5d6IdttN "Oil Debris Monitor Non-Ferrous Bins 5 and 6 Identification Number: Identification number of the Oil Debris Monitoring (ODM) sensor being reported for Non-Ferrous bins 5 and 6. Identification numbers are application specific.";
CM_ SG_ 2566648062 OlDrsMntrNnFrrsBn5Cnt "Oil Debris Monitor Non-Ferrous Bin 5 Count: Total number of particles detected in Non-Ferrous bin 5. Bin sizes are application specific.";
CM_ SG_ 2566648062 OlDrsMntrNnFrrsBn6Cnt "Oil Debris Monitor Non-Ferrous Bin 6 Count: Total number of particles detected in Non-Ferrous bin 6. Bin sizes are application specific.";
BA_DEF_ SG_  "SPN" INT 0 524287;
BA_DEF_ BO_  "VFrameFormat" ENUM  "StandardCAN","ExtendedCAN","reserved","J1939PG";
BA_DEF_DEF_  "SPN" 0;
BA_DEF_DEF_  "VFrameFormat" "J1939PG";
BA_ "SPN" SG_ 2565873150 MessageChecksum 3690;
BA_ "SPN" SG_ 2565873150 MessageCounter 3689;
BA_ "SPN" SG_ 2565873150 SteeringAngleSensorActiveMode 3687;
BA_ "SPN" SG_ 2565873150 SteeringAngleSensorCalibrated 3688;
BA_ "SPN" SG_ 2565873150 SteeringWheelAngle 3683;
BA_ "SPN" SG_ 2565873150 SteeringWheelAngleRange 3686;
BA_ "SPN" SG_ 2565873150 SteeringWheelAngleRangeCounter 3684;
BA_ "SPN" SG_ 2565873150 StrngWhlAnglRngCntrTp 3685;
BA_ "SPN" SG_ 2565874174 EngineSpeed1 4201;
BA_ "SPN" SG_ 2565874174 EngineSpeed2 723;
BA_ "SPN" SG_ 2565874174 EngineSpeed3 4202;
BA_ "SPN" SG_ 2565874174 EngnSpdSnsr1TmngPttrnStts 4203;
BA_ "SPN" SG_ 2565874174 EngnSpdSnsr2TmngPttrnStts 4204;
BA_ "SPN" SG_ 2565874174 EngnSpdSnsr3TmngPttrnStts 4205;
BA_ "SPN" SG_ 2565877502 EExstB1PssRtCtCd 649;
BA_ "SPN" SG_ 2565877502 EngnTrhrgrWstgtAttr1Cmmnd 5386;
BA_ "SPN" SG_ 2565877502 EngnTrhrgrWstgtAttr2Cmmnd 5387;
BA_ "SPN" SG_ 2565877502 ETCpssBwAtt1Cd 6201;
BA_ "SPN" SG_ 2565917438 DCACAssIvt1PwLtddtACSdRMSCt 9212;
BA_ "SPN" SG_ 2565917438 DCACAssIvt1PwLtddtCtTpt 9216;
BA_ "SPN" SG_ 2565917438 DCACAssIvt1PwLtddtDCSdCt 9211;
BA_ "SPN" SG_ 2565917438 DCACAssIvt1PwLtddtDCSdVtM 9213;
BA_ "SPN" SG_ 2565917438 DCACAssIvt1PwLtddtEtFtTpt 9217;
BA_ "SPN" SG_ 2565917438 DCACAssIvt1PwLtddtPwEtsTpt 9218;
BA_ "SPN" SG_ 2565917438 DCACAssIvt1PwLtddtRtCLt 9219;
BA_ "SPN" SG_ 2565917438 DCACAssIvt1PwLtddtUddRs 9220;
BA_ "SPN" SG_ 2565917438 DCACAssrInvrtr1FrqnCmmndlwMnmm 9214;
BA_ "SPN" SG_ 2565917438 DCACAssrInvrtr1FrqnCmmndxdsMxmm 9215;
BA_ "SPN" SG_ 2565918206 DCACAssIvt2PwLtddtACSdRMSCt 9242;
BA_ "SPN" SG_ 2565918206 DCACAssIvt2PwLtddtCtTpt 9246;
BA_ "SPN" SG_ 2565918206 DCACAssIvt2PwLtddtDCSdCt 9241;
BA_ "SPN" SG_ 2565918206 DCACAssIvt2PwLtddtDCSdVtM 9243;
BA_ "SPN" SG_ 2565918206 DCACAssIvt2PwLtddtEtFtTpt 9247;
BA_ "SPN" SG_ 2565918206 DCACAssIvt2PwLtddtPwEtsTpt 9248;
BA_ "SPN" SG_ 2565918206 DCACAssIvt2PwLtddtRtCLt 9249;
BA_ "SPN" SG_ 2565918206 DCACAssIvt2PwLtddtUddRs 9250;
BA_ "SPN" SG_ 2565918206 DCACAssrInvrtr2FrqnCmmndlwMnmm 9244;
BA_ "SPN" SG_ 2565918206 DCACAssrInvrtr2FrqnCmmndxdsMxmm 9245;
BA_ "SPN" SG_ 2565920510 DCACAssIvt1ACSdMtSttRMSVtRqst 9528;
BA_ "SPN" SG_ 2565920510 DCACAssrInvrtr1Dv1Stts 8334;
BA_ "SPN" SG_ 2565920510 DCACAssrInvrtr1Dv2Stts 8335;
BA_ "SPN" SG_ 2565920510 DCACAssrInvrtr1DvFrqnRtfChngLmt 8332;
BA_ "SPN" SG_ 2565920510 DCACAssrInvrtr1DvMnmmFrqn 8329;
BA_ "SPN" SG_ 2565920510 DCACAssrInvrtr1DvMxmmFrqn 8328;
BA_ "SPN" SG_ 2565920510 DCACAssrInvrtr1DvRtdFrqn 8330;
BA_ "SPN" SG_ 2565920510 DCACAssrInvrtr1DvRtdRMSVltg 8331;
BA_ "SPN" SG_ 2565920510 DCACAssrInvrtr1FrqnCmmnd 8333;
BA_ "SPN" SG_ 2565920510 DCACAssrInvrtr1OprtnlCmmnd 8336;
BA_ "SPN" SG_ 2565920766 DCACAccessoryInverter1Frequency 8337;
BA_ "SPN" SG_ 2565920766 DCACAssrInvrtr1ACSdPwr 8339;
BA_ "SPN" SG_ 2565920766 DCACAssrInvrtr1ACSdRMSCrrnt 9200;
BA_ "SPN" SG_ 2565920766 DCACAssrInvrtr1ACSdRMSVltg 8338;
BA_ "SPN" SG_ 2565920766 DCACAssrInvrtr1HVILStts 8851;
BA_ "SPN" SG_ 2565920766 DCACAssrInvrtr1LdshdRqst 8341;
BA_ "SPN" SG_ 2565920766 DCACAssrInvrtr1OprtnlStts 8340;
BA_ "SPN" SG_ 2565921534 DCACAssIvt2ACSdMtSttRMSVtRqst 9534;
BA_ "SPN" SG_ 2565921534 DCACAssrInvrtr2Dv1Stts 8348;
BA_ "SPN" SG_ 2565921534 DCACAssrInvrtr2Dv2Stts 8349;
BA_ "SPN" SG_ 2565921534 DCACAssrInvrtr2DvFrqnRtfChngLmt 8346;
BA_ "SPN" SG_ 2565921534 DCACAssrInvrtr2DvMnmmFrqn 8343;
BA_ "SPN" SG_ 2565921534 DCACAssrInvrtr2DvMxmmFrqn 8342;
BA_ "SPN" SG_ 2565921534 DCACAssrInvrtr2DvRtdFrqn 8344;
BA_ "SPN" SG_ 2565921534 DCACAssrInvrtr2DvRtdRMSVltg 8345;
BA_ "SPN" SG_ 2565921534 DCACAssrInvrtr2FrqnCmmnd 8347;
BA_ "SPN" SG_ 2565921534 DCACAssrInvrtr2OprtnlCmmnd 8350;
BA_ "SPN" SG_ 2565921790 DCACAccessoryInverter2Frequency 8351;
BA_ "SPN" SG_ 2565921790 DCACAssrInvrtr2ACSdPwr 8353;
BA_ "SPN" SG_ 2565921790 DCACAssrInvrtr2ACSdRMSCrrnt 9201;
BA_ "SPN" SG_ 2565921790 DCACAssrInvrtr2ACSdRMSVltg 8352;
BA_ "SPN" SG_ 2565921790 DCACAssrInvrtr2HVILStts 8852;
BA_ "SPN" SG_ 2565921790 DCACAssrInvrtr2LdshdRqst 8355;
BA_ "SPN" SG_ 2565921790 DCACAssrInvrtr2OprtnlStts 8354;
BA_ "SPN" SG_ 2565922558 DCACAssIvt3ACSdMtSttRMSVtRqst 9540;
BA_ "SPN" SG_ 2565922558 DCACAssrInvrtr3Dv1Stts 8362;
BA_ "SPN" SG_ 2565922558 DCACAssrInvrtr3Dv2Stts 8363;
BA_ "SPN" SG_ 2565922558 DCACAssrInvrtr3DvFrqnRtfChngLmt 8360;
BA_ "SPN" SG_ 2565922558 DCACAssrInvrtr3DvMnmmFrqn 8357;
BA_ "SPN" SG_ 2565922558 DCACAssrInvrtr3DvMxmmFrqn 8356;
BA_ "SPN" SG_ 2565922558 DCACAssrInvrtr3DvRtdFrqn 8358;
BA_ "SPN" SG_ 2565922558 DCACAssrInvrtr3DvRtdRMSVltg 8359;
BA_ "SPN" SG_ 2565922558 DCACAssrInvrtr3FrqnCmmnd 8361;
BA_ "SPN" SG_ 2565922558 DCACAssrInvrtr3OprtnlCmmnd 8364;
BA_ "SPN" SG_ 2565922814 DCACAccessoryInverter3Frequency 8365;
BA_ "SPN" SG_ 2565922814 DCACAssrInvrtr3ACSdPwr 8367;
BA_ "SPN" SG_ 2565922814 DCACAssrInvrtr3ACSdRMSCrrnt 9202;
BA_ "SPN" SG_ 2565922814 DCACAssrInvrtr3ACSdRMSVltg 8366;
BA_ "SPN" SG_ 2565922814 DCACAssrInvrtr3HVILStts 8853;
BA_ "SPN" SG_ 2565922814 DCACAssrInvrtr3LdshdRqst 8369;
BA_ "SPN" SG_ 2565922814 DCACAssrInvrtr3OprtnlStts 8368;
BA_ "SPN" SG_ 2565923582 DCACAssIvt4ACSdMtSttRMSVtRqst 9546;
BA_ "SPN" SG_ 2565923582 DCACAssrInvrtr4Dv1Stts 8376;
BA_ "SPN" SG_ 2565923582 DCACAssrInvrtr4Dv2Stts 8377;
BA_ "SPN" SG_ 2565923582 DCACAssrInvrtr4DvFrqnRtfChngLmt 8374;
BA_ "SPN" SG_ 2565923582 DCACAssrInvrtr4DvMnmmFrqn 8371;
BA_ "SPN" SG_ 2565923582 DCACAssrInvrtr4DvMxmmFrqn 8370;
BA_ "SPN" SG_ 2565923582 DCACAssrInvrtr4DvRtdFrqn 8372;
BA_ "SPN" SG_ 2565923582 DCACAssrInvrtr4DvRtdRMSVltg 8373;
BA_ "SPN" SG_ 2565923582 DCACAssrInvrtr4FrqnCmmnd 8375;
BA_ "SPN" SG_ 2565923582 DCACAssrInvrtr4OprtnlCmmnd 8378;
BA_ "SPN" SG_ 2565923838 DCACAccessoryInverter4Frequency 8379;
BA_ "SPN" SG_ 2565923838 DCACAssrInvrtr4ACSdPwr 8381;
BA_ "SPN" SG_ 2565923838 DCACAssrInvrtr4ACSdRMSCrrnt 9203;
BA_ "SPN" SG_ 2565923838 DCACAssrInvrtr4ACSdRMSVltg 8380;
BA_ "SPN" SG_ 2565923838 DCACAssrInvrtr4HVILStts 8854;
BA_ "SPN" SG_ 2565923838 DCACAssrInvrtr4LdshdRqst 8383;
BA_ "SPN" SG_ 2565923838 DCACAssrInvrtr4OprtnlStts 8382;
BA_ "SPN" SG_ 2565925374 Aftrtrtmnt1IntkGsSnsr2HtrCntrl 7656;
BA_ "SPN" SG_ 2565925374 Aftrtrtmnt1IntkGsSnsr2PwrInRng 7651;
BA_ "SPN" SG_ 2565925374 Aftrtrtmnt1IntkGsSnsr2tTmprtr 7652;
BA_ "SPN" SG_ 2565925374 Aftrtrtmnt1IntkPrntOxgn2 7650;
BA_ "SPN" SG_ 2565925374 Atttt1ItGsSs2HtPFMI 7655;
BA_ "SPN" SG_ 2565925374 Atttt1ItOxSs2PFMI 7659;
BA_ "SPN" SG_ 2565925374 Atttt1ItWdRPtOx2RdSt 7654;
BA_ "SPN" SG_ 2565925374 EngineExhaust1NOx2 7649;
BA_ "SPN" SG_ 2565925374 EngineExhaust1NOx2ReadingStable 7653;
BA_ "SPN" SG_ 2565925374 EngnExhst1NOxSnsr2PrlmnrFMI 7657;
BA_ "SPN" SG_ 2565925374 EngnExhst1NOxSnsr2SlfdgnssStts 7658;
BA_ "SPN" SG_ 2565925630 Aftertreatment1OutletNOx2 7660;
BA_ "SPN" SG_ 2565925630 Aftrtrtmnt1OtltGsSnsr2HtrCntrl 7667;
BA_ "SPN" SG_ 2565925630 Aftrtrtmnt1OtltGsSnsr2PwrInRng 7662;
BA_ "SPN" SG_ 2565925630 Aftrtrtmnt1OtltGsSnsr2tTmprtr 7663;
BA_ "SPN" SG_ 2565925630 Aftrtrtmnt1OtltNOx2RdngStl 7664;
BA_ "SPN" SG_ 2565925630 Aftrtrtmnt1OtltPrntOxgn2 7661;
BA_ "SPN" SG_ 2565925630 Atttt1OttGsSs2HtPFMI 7666;
BA_ "SPN" SG_ 2565925630 Atttt1OttNOxSs2PFMI 7668;
BA_ "SPN" SG_ 2565925630 Atttt1OttNOxSs2SdssStts 7669;
BA_ "SPN" SG_ 2565925630 Atttt1OttOxSs2PFMI 7670;
BA_ "SPN" SG_ 2565925630 Atttt1OttWdRPtOx2RdSt 7665;
BA_ "SPN" SG_ 2565925886 Aftrtrtmnt2IntkGsSnsr2HtrCntrl 7678;
BA_ "SPN" SG_ 2565925886 Aftrtrtmnt2IntkGsSnsr2PwrInRng 7673;
BA_ "SPN" SG_ 2565925886 Aftrtrtmnt2IntkGsSnsr2tTmprtr 7674;
BA_ "SPN" SG_ 2565925886 Aftrtrtmnt2IntkPrntOxgn2 7672;
BA_ "SPN" SG_ 2565925886 Atttt2ItGsSs2HtPFMI 7677;
BA_ "SPN" SG_ 2565925886 Atttt2ItOxSs2PFMI 7681;
BA_ "SPN" SG_ 2565925886 Atttt2ItWdRPtOx2RdSt 7676;
BA_ "SPN" SG_ 2565925886 EngineExhaust2NOx2 7671;
BA_ "SPN" SG_ 2565925886 EngineExhaust2NOx2ReadingStable 7675;
BA_ "SPN" SG_ 2565925886 EngnExhst2NOxSnsr2PrlmnrFMI 7679;
BA_ "SPN" SG_ 2565925886 EngnExhst2NOxSnsr2SlfdgnssStts 7680;
BA_ "SPN" SG_ 2565926142 Aftertreatment2OutletNOx2 7682;
BA_ "SPN" SG_ 2565926142 Aftrtrtmnt2OtltGsSnsr2HtrCntrl 7689;
BA_ "SPN" SG_ 2565926142 Aftrtrtmnt2OtltGsSnsr2PwrInRng 7684;
BA_ "SPN" SG_ 2565926142 Aftrtrtmnt2OtltGsSnsr2tTmprtr 7685;
BA_ "SPN" SG_ 2565926142 Aftrtrtmnt2OtltNOx2RdngStl 7686;
BA_ "SPN" SG_ 2565926142 Aftrtrtmnt2OtltPrntOxgn2 7683;
BA_ "SPN" SG_ 2565926142 Atttt2OttGsSs2HtPFMI 7688;
BA_ "SPN" SG_ 2565926142 Atttt2OttNOxSs2PFMI 7690;
BA_ "SPN" SG_ 2565926142 Atttt2OttNOxSs2SdssStts 7691;
BA_ "SPN" SG_ 2565926142 Atttt2OttOxSs2PFMI 7692;
BA_ "SPN" SG_ 2565926142 Atttt2OttWdRPtOx2RdSt 7687;
BA_ "SPN" SG_ 2565932286 EngineSpeed4 7846;
BA_ "SPN" SG_ 2565932798 WllStmltnPmpDshrgPrssr 8155;
BA_ "SPN" SG_ 2565932798 WllStmltnPmpStnPrssr 8154;
BA_ "SPN" SG_ 2565933054 WellStimulationPumpSpeed 8158;
BA_ "SPN" SG_ 2565933054 WllStmltnPmpGrBxOlPrssr 8156;
BA_ "SPN" SG_ 2565933054 WllStmltnPmpGrBxOlTmprtr 8157;
BA_ "SPN" SG_ 2565933054 WllStmltnPmpGrBxOtltOlTmprtr 12812;
BA_ "SPN" SG_ 2565934590 EngnFlVlv2DffrntlPrssr 6885;
BA_ "SPN" SG_ 2565942014 DCACAssIvt3PwLtddtACSdRMSCt 9272;
BA_ "SPN" SG_ 2565942014 DCACAssIvt3PwLtddtCtTpt 9276;
BA_ "SPN" SG_ 2565942014 DCACAssIvt3PwLtddtDCSdCt 9271;
BA_ "SPN" SG_ 2565942014 DCACAssIvt3PwLtddtDCSdVtM 9273;
BA_ "SPN" SG_ 2565942014 DCACAssIvt3PwLtddtEtFtTpt 9277;
BA_ "SPN" SG_ 2565942014 DCACAssIvt3PwLtddtPwEtsTpt 9278;
BA_ "SPN" SG_ 2565942014 DCACAssIvt3PwLtddtRtCLt 9279;
BA_ "SPN" SG_ 2565942014 DCACAssIvt3PwLtddtUddRs 9280;
BA_ "SPN" SG_ 2565942014 DCACAssrInvrtr3FrqnCmmndlwMnmm 9274;
BA_ "SPN" SG_ 2565942014 DCACAssrInvrtr3FrqnCmmndxdsMxmm 9275;
BA_ "SPN" SG_ 2565942782 DCACAssIvt4PwLtddtACSdRMSCt 9302;
BA_ "SPN" SG_ 2565942782 DCACAssIvt4PwLtddtCtTpt 9306;
BA_ "SPN" SG_ 2565942782 DCACAssIvt4PwLtddtDCSdCt 9301;
BA_ "SPN" SG_ 2565942782 DCACAssIvt4PwLtddtDCSdVtM 9303;
BA_ "SPN" SG_ 2565942782 DCACAssIvt4PwLtddtEtFtTpt 9307;
BA_ "SPN" SG_ 2565942782 DCACAssIvt4PwLtddtPwEtsTpt 9308;
BA_ "SPN" SG_ 2565942782 DCACAssIvt4PwLtddtRtCLt 9309;
BA_ "SPN" SG_ 2565942782 DCACAssIvt4PwLtddtUddRs 9310;
BA_ "SPN" SG_ 2565942782 DCACAssrInvrtr4FrqnCmmndlwMnmm 9304;
BA_ "SPN" SG_ 2565942782 DCACAssrInvrtr4FrqnCmmndxdsMxmm 9305;
BA_ "SPN" SG_ 2565943038 DCACAssIvt5ACSdMtSttRMSVtRqst 9552;
BA_ "SPN" SG_ 2565943038 DCACAssrInvrtr5Dv1Stts 9327;
BA_ "SPN" SG_ 2565943038 DCACAssrInvrtr5Dv2Stts 9328;
BA_ "SPN" SG_ 2565943038 DCACAssrInvrtr5DvFrqnRtfChngLmt 9325;
BA_ "SPN" SG_ 2565943038 DCACAssrInvrtr5DvMnmmFrqn 9322;
BA_ "SPN" SG_ 2565943038 DCACAssrInvrtr5DvMxmmFrqn 9321;
BA_ "SPN" SG_ 2565943038 DCACAssrInvrtr5DvRtdFrqn 9323;
BA_ "SPN" SG_ 2565943038 DCACAssrInvrtr5DvRtdRMSVltg 9324;
BA_ "SPN" SG_ 2565943038 DCACAssrInvrtr5FrqnCmmnd 9326;
BA_ "SPN" SG_ 2565943038 DCACAssrInvrtr5OprtnlCmmnd 9329;
BA_ "SPN" SG_ 2565943294 DCACAccessoryInverter5Frequency 9330;
BA_ "SPN" SG_ 2565943294 DCACAssrInvrtr5ACSdPwr 9332;
BA_ "SPN" SG_ 2565943294 DCACAssrInvrtr5ACSdRMSCrrnt 9333;
BA_ "SPN" SG_ 2565943294 DCACAssrInvrtr5ACSdRMSVltg 9331;
BA_ "SPN" SG_ 2565943294 DCACAssrInvrtr5HVILStts 9336;
BA_ "SPN" SG_ 2565943294 DCACAssrInvrtr5LdshdRqst 9335;
BA_ "SPN" SG_ 2565943294 DCACAssrInvrtr5OprtnlStts 9334;
BA_ "SPN" SG_ 2565944062 DCACAssIvt5PwLtddtACSdRMSCt 9348;
BA_ "SPN" SG_ 2565944062 DCACAssIvt5PwLtddtCtTpt 9352;
BA_ "SPN" SG_ 2565944062 DCACAssIvt5PwLtddtDCSdCt 9347;
BA_ "SPN" SG_ 2565944062 DCACAssIvt5PwLtddtDCSdVtM 9349;
BA_ "SPN" SG_ 2565944062 DCACAssIvt5PwLtddtEtFtTpt 9353;
BA_ "SPN" SG_ 2565944062 DCACAssIvt5PwLtddtPwEtsTpt 9354;
BA_ "SPN" SG_ 2565944062 DCACAssIvt5PwLtddtRtCLt 9355;
BA_ "SPN" SG_ 2565944062 DCACAssIvt5PwLtddtUddRs 9356;
BA_ "SPN" SG_ 2565944062 DCACAssrInvrtr5FrqnCmmndlwMnmm 9350;
BA_ "SPN" SG_ 2565944062 DCACAssrInvrtr5FrqnCmmndxdsMxmm 9351;
BA_ "SPN" SG_ 2566624510 EngnExhstGsRrltn1ClrIntkPrssr 9379;
BA_ "SPN" SG_ 2566624766 EngnIdlMngmntAtvTtlTm 9377;
BA_ "SPN" SG_ 2566625022 InstntnsEstmtdEngnPwrRtLmt 9375;
BA_ "SPN" SG_ 2566625278 SLIBttrPk1Bttr1CptSttng 9368;
BA_ "SPN" SG_ 2566625278 SLIBttrPk1Bttr2CptSttng 9369;
BA_ "SPN" SG_ 2566625278 SLIBttrPk1Bttr3CptSttng 9370;
BA_ "SPN" SG_ 2566625278 SLIBttrPk1Bttr4CptSttng 9371;
BA_ "SPN" SG_ 2566625790 DCACAssIvt1IvtEtFtTpt 9205;
BA_ "SPN" SG_ 2566625790 DCACAssrInvrtr1ClntInTmprtr 9207;
BA_ "SPN" SG_ 2566625790 DCACAssrInvrtr1ClntOtTmprtr 9208;
BA_ "SPN" SG_ 2566625790 DCACAssrInvrtr1CntrllrTmprtr 9204;
BA_ "SPN" SG_ 2566625790 DCACAssrInvrtr1PwrEltrnsTmprtr 9206;
BA_ "SPN" SG_ 2566626558 DCACAssIvt1ACSdDtFqCdStt 9533;
BA_ "SPN" SG_ 2566626558 DCACAssIvt1ACSdRMSCtMxLtStt 9228;
BA_ "SPN" SG_ 2566626558 DCACAssIvt1ACSdRMSVtMxLtStt 9227;
BA_ "SPN" SG_ 2566626558 DCACAssIvt1DCSdCtMLtStt 9532;
BA_ "SPN" SG_ 2566626558 DCACAssIvt1DCSdCtMxLtStt 9226;
BA_ "SPN" SG_ 2566626558 DCACAssIvt1DCSdVtMLtStt 9225;
BA_ "SPN" SG_ 2566626558 DCACAssIvt1DCSdVtMxLtStt 9531;
BA_ "SPN" SG_ 2566626814 DCACAssrInvrtr1TtlDCInptChrg 9229;
BA_ "SPN" SG_ 2566626814 DCACAssrInvrtr1TtlDCInptEnrg 9230;
BA_ "SPN" SG_ 2566627070 DCACAssIvt2IvtEtFtTpt 9232;
BA_ "SPN" SG_ 2566627070 DCACAssrInvrtr2ClntInTmprtr 9234;
BA_ "SPN" SG_ 2566627070 DCACAssrInvrtr2ClntOtTmprtr 9235;
BA_ "SPN" SG_ 2566627070 DCACAssrInvrtr2CntrllrTmprtr 9231;
BA_ "SPN" SG_ 2566627070 DCACAssrInvrtr2PwrEltrnsTmprtr 9233;
BA_ "SPN" SG_ 2566627838 DCACAssIvt2ACSdDtFqCdStt 9539;
BA_ "SPN" SG_ 2566627838 DCACAssIvt2ACSdRMSCtMxLtStt 9258;
BA_ "SPN" SG_ 2566627838 DCACAssIvt2ACSdRMSVtMxLtStt 9257;
BA_ "SPN" SG_ 2566627838 DCACAssIvt2DCSdCtMLtStt 9538;
BA_ "SPN" SG_ 2566627838 DCACAssIvt2DCSdCtMxLtStt 9256;
BA_ "SPN" SG_ 2566627838 DCACAssIvt2DCSdVtMLtStt 9255;
BA_ "SPN" SG_ 2566627838 DCACAssIvt2DCSdVtMxLtStt 9537;
BA_ "SPN" SG_ 2566628094 DCACAssrInvrtr2TtlDCInptChrg 9259;
BA_ "SPN" SG_ 2566628094 DCACAssrInvrtr2TtlDCInptEnrg 9260;
BA_ "SPN" SG_ 2566628350 DCACAssIvt3IvtEtFtTpt 9262;
BA_ "SPN" SG_ 2566628350 DCACAssrInvrtr3ClntInTmprtr 9264;
BA_ "SPN" SG_ 2566628350 DCACAssrInvrtr3ClntOtTmprtr 9265;
BA_ "SPN" SG_ 2566628350 DCACAssrInvrtr3CntrllrTmprtr 9261;
BA_ "SPN" SG_ 2566628350 DCACAssrInvrtr3PwrEltrnsTmprtr 9263;
BA_ "SPN" SG_ 2566629118 DCACAssIvt3ACSdDtFqCdStt 9545;
BA_ "SPN" SG_ 2566629118 DCACAssIvt3ACSdRMSCtMxLtStt 9288;
BA_ "SPN" SG_ 2566629118 DCACAssIvt3ACSdRMSVtMxLtStt 9287;
BA_ "SPN" SG_ 2566629118 DCACAssIvt3DCSdCtMLtStt 9544;
BA_ "SPN" SG_ 2566629118 DCACAssIvt3DCSdCtMxLtStt 9286;
BA_ "SPN" SG_ 2566629118 DCACAssIvt3DCSdVtMLtStt 9285;
BA_ "SPN" SG_ 2566629118 DCACAssIvt3DCSdVtMxLtStt 9543;
BA_ "SPN" SG_ 2566629374 DCACAssrInvrtr3TtlDCInptChrg 9289;
BA_ "SPN" SG_ 2566629374 DCACAssrInvrtr3TtlDCInptEnrg 9290;
BA_ "SPN" SG_ 2566629630 DCACAssIvt4IvtEtFtTpt 9292;
BA_ "SPN" SG_ 2566629630 DCACAssrInvrtr4ClntInTmprtr 9294;
BA_ "SPN" SG_ 2566629630 DCACAssrInvrtr4ClntOtTmprtr 9295;
BA_ "SPN" SG_ 2566629630 DCACAssrInvrtr4CntrllrTmprtr 9291;
BA_ "SPN" SG_ 2566629630 DCACAssrInvrtr4PwrEltrnsTmprtr 9293;
BA_ "SPN" SG_ 2566630398 DCACAssIvt4ACSdDtFqCdStt 9551;
BA_ "SPN" SG_ 2566630398 DCACAssIvt4ACSdRMSCtMxLtStt 9318;
BA_ "SPN" SG_ 2566630398 DCACAssIvt4ACSdRMSVtMxLtStt 9317;
BA_ "SPN" SG_ 2566630398 DCACAssIvt4DCSdCtMLtStt 9550;
BA_ "SPN" SG_ 2566630398 DCACAssIvt4DCSdCtMxLtStt 9316;
BA_ "SPN" SG_ 2566630398 DCACAssIvt4DCSdVtMLtStt 9315;
BA_ "SPN" SG_ 2566630398 DCACAssIvt4DCSdVtMxLtStt 9549;
BA_ "SPN" SG_ 2566630654 DCACAssrInvrtr4TtlDCInptChrg 9319;
BA_ "SPN" SG_ 2566630654 DCACAssrInvrtr4TtlDCInptEnrg 9320;
BA_ "SPN" SG_ 2566630910 DCACAssIvt5IvtEtFtTpt 9338;
BA_ "SPN" SG_ 2566630910 DCACAssrInvrtr5ClntInTmprtr 9340;
BA_ "SPN" SG_ 2566630910 DCACAssrInvrtr5ClntOtTmprtr 9341;
BA_ "SPN" SG_ 2566630910 DCACAssrInvrtr5CntrllrTmprtr 9337;
BA_ "SPN" SG_ 2566630910 DCACAssrInvrtr5PwrEltrnsTmprtr 9339;
BA_ "SPN" SG_ 2566631678 DCACAssIvt5ACSdDtFqCdStt 9557;
BA_ "SPN" SG_ 2566631678 DCACAssIvt5ACSdRMSCtMxLtStt 9364;
BA_ "SPN" SG_ 2566631678 DCACAssIvt5ACSdRMSVtMxLtStt 9363;
BA_ "SPN" SG_ 2566631678 DCACAssIvt5DCSdCtMLtStt 9556;
BA_ "SPN" SG_ 2566631678 DCACAssIvt5DCSdCtMxLtStt 9362;
BA_ "SPN" SG_ 2566631678 DCACAssIvt5DCSdVtMLtStt 9361;
BA_ "SPN" SG_ 2566631678 DCACAssIvt5DCSdVtMxLtStt 9555;
BA_ "SPN" SG_ 2566631934 DCACAssrInvrtr5TtlDCInptChrg 9365;
BA_ "SPN" SG_ 2566631934 DCACAssrInvrtr5TtlDCInptEnrg 9366;
BA_ "SPN" SG_ 2566632190 WllStmltnPmpStnPrssrClrtnStPnt 9193;
BA_ "SPN" SG_ 2566632190 WSttPpDsPssCtStPt 9195;
BA_ "SPN" SG_ 2566632190 WSttPpDsPssCtStPtStts 9196;
BA_ "SPN" SG_ 2566632190 WSttPpStPssCtStPtStts 9194;
BA_ "SPN" SG_ 2566632446 WllStmltnPmpTrpFldPmpd 9192;
BA_ "SPN" SG_ 2566632446 WllStmltnPmpTtlFldPmpd 9191;
BA_ "SPN" SG_ 2566632702 WllStmltnPmpFldEndSrlNmr 9190;
BA_ "SPN" SG_ 2566632702 WllStmltnPmpPwrEndSrlNmr 9189;
BA_ "SPN" SG_ 2566632958 WllStmltnPmpFldEndTrpHrs 9187;
BA_ "SPN" SG_ 2566632958 WllStmltnPmpPwrEndTrpHrs 9188;
BA_ "SPN" SG_ 2566633214 Aftrtrtmnt1OtltOxgnPmpngCrrnt 9178;
BA_ "SPN" SG_ 2566633214 Atttt1OttNOxSsPttAPssAst 12908;
BA_ "SPN" SG_ 2566633470 Aftrtrtmnt1IntkOxgnPmpngCrrnt 9177;
BA_ "SPN" SG_ 2566633470 Atttt1ItNOxSsPttAPssAst 12907;
BA_ "SPN" SG_ 2566633726 DCDC4TotalHighSideCharge 9032;
BA_ "SPN" SG_ 2566633726 DCDC4TotalHighSideEnergy 9030;
BA_ "SPN" SG_ 2566633726 DCDC4TotalLowSideCharge 9033;
BA_ "SPN" SG_ 2566633726 DCDC4TotalLowSideEnergy 9031;
BA_ "SPN" SG_ 2566633982 DCDC4HghSdCrrntMxmmLmtSttng 9036;
BA_ "SPN" SG_ 2566633982 DCDC4HghSdVltgMnmmLmtSttng 9034;
BA_ "SPN" SG_ 2566633982 DCDC4HghSdVltgMxmmLmtSttng 9035;
BA_ "SPN" SG_ 2566633982 DCDC4LwSdCrrntMxmmLmtSttng 9039;
BA_ "SPN" SG_ 2566633982 DCDC4LwSdVltgBkDfltSttng 9522;
BA_ "SPN" SG_ 2566633982 DCDC4LwSdVltgMnmmLmtSttng 9037;
BA_ "SPN" SG_ 2566633982 DCDC4LwSdVltgMxmmLmtSttng 9038;
BA_ "SPN" SG_ 2566633982 DCDC4SLIBttrTmprtrMxmmLmtSttng 9042;
BA_ "SPN" SG_ 2566633982 DCDC4SLIBttTCCtMxLtStt 9041;
BA_ "SPN" SG_ 2566633982 DCDC4SLIBttTVtMxLtStt 9040;
BA_ "SPN" SG_ 2566635262 DCDC3TotalHighSideCharge 8977;
BA_ "SPN" SG_ 2566635262 DCDC3TotalHighSideEnergy 8975;
BA_ "SPN" SG_ 2566635262 DCDC3TotalLowSideCharge 8978;
BA_ "SPN" SG_ 2566635262 DCDC3TotalLowSideEnergy 8976;
BA_ "SPN" SG_ 2566635518 DCDC3HghSdCrrntMxmmLmtSttng 8981;
BA_ "SPN" SG_ 2566635518 DCDC3HghSdVltgMnmmLmtSttng 8979;
BA_ "SPN" SG_ 2566635518 DCDC3HghSdVltgMxmmLmtSttng 8980;
BA_ "SPN" SG_ 2566635518 DCDC3LwSdCrrntMxmmLmtSttng 8984;
BA_ "SPN" SG_ 2566635518 DCDC3LwSdVltgBkDfltSttng 9521;
BA_ "SPN" SG_ 2566635518 DCDC3LwSdVltgMnmmLmtSttng 8982;
BA_ "SPN" SG_ 2566635518 DCDC3LwSdVltgMxmmLmtSttng 8983;
BA_ "SPN" SG_ 2566635518 DCDC3SLIBttrTmprtrMxmmLmtSttng 8987;
BA_ "SPN" SG_ 2566635518 DCDC3SLIBttTCCtMxLtStt 8986;
BA_ "SPN" SG_ 2566635518 DCDC3SLIBttTVtMxLtStt 8985;
BA_ "SPN" SG_ 2566636798 DCDC2TotalHighSideCharge 8922;
BA_ "SPN" SG_ 2566636798 DCDC2TotalHighSideEnergy 8920;
BA_ "SPN" SG_ 2566636798 DCDC2TotalLowSideCharge 8923;
BA_ "SPN" SG_ 2566636798 DCDC2TotalLowSideEnergy 8921;
BA_ "SPN" SG_ 2566637054 DCDC2HghSdCrrntMxmmLmtSttng 8926;
BA_ "SPN" SG_ 2566637054 DCDC2HghSdVltgMnmmLmtSttng 8924;
BA_ "SPN" SG_ 2566637054 DCDC2HghSdVltgMxmmLmtSttng 8925;
BA_ "SPN" SG_ 2566637054 DCDC2LwSdCrrntMxmmLmtSttng 8929;
BA_ "SPN" SG_ 2566637054 DCDC2LwSdVltgBkDfltSttng 9520;
BA_ "SPN" SG_ 2566637054 DCDC2LwSdVltgMnmmLmtSttng 8927;
BA_ "SPN" SG_ 2566637054 DCDC2LwSdVltgMxmmLmtSttng 8928;
BA_ "SPN" SG_ 2566637054 DCDC2SLIBttrTmprtrMxmmLmtSttng 8932;
BA_ "SPN" SG_ 2566637054 DCDC2SLIBttTCCtMxLtStt 8931;
BA_ "SPN" SG_ 2566637054 DCDC2SLIBttTVtMxLtStt 8930;
BA_ "SPN" SG_ 2566638590 ExhstPrtltCntrlSstmDgnstCnt 8888;
BA_ "SPN" SG_ 2566638590 ExhstPrtltCntrlSstmDgnstTm 8887;
BA_ "SPN" SG_ 2566638846 WllStmltnPmpMntnnIntrvlHrs 8882;
BA_ "SPN" SG_ 2566638846 WllStmltnPmpPkngOprtnHrs 8884;
BA_ "SPN" SG_ 2566638846 WllStmltnPmpVlvOprtnHrs 8883;
BA_ "SPN" SG_ 2566638846 WllStmltnPmpVlvStOprtnHrs 8885;
BA_ "SPN" SG_ 2566639102 WllStmltnPmpPlngrFrngOrdrSttng 8881;
BA_ "SPN" SG_ 2566639102 WllStmltnPmpRdLdHghThrshldSttng 8880;
BA_ "SPN" SG_ 2566639102 WSttPpCstSpdHTsdStt 8879;
BA_ "SPN" SG_ 2566639102 WSttPpCstSpdLwTsdStt 8878;
BA_ "SPN" SG_ 2566639102 WSttPpDsPssHTsdStt 8877;
BA_ "SPN" SG_ 2566639102 WSttPpGBxOPssHTsdStt 8872;
BA_ "SPN" SG_ 2566639102 WSttPpGBxOPssLwTsdStt 8871;
BA_ "SPN" SG_ 2566639102 WSttPpGBxOTptHTsdStt 8874;
BA_ "SPN" SG_ 2566639102 WSttPpGBxOTptLwTsdStt 8873;
BA_ "SPN" SG_ 2566639102 WSttPpStPssHTsdStt 8876;
BA_ "SPN" SG_ 2566639102 WSttPpStPssLwTsdStt 8875;
BA_ "SPN" SG_ 2566639614 DCDC1TotalHighSideCharge 8835;
BA_ "SPN" SG_ 2566639614 DCDC1TotalHighSideEnergy 8833;
BA_ "SPN" SG_ 2566639614 DCDC1TotalLowSideCharge 8836;
BA_ "SPN" SG_ 2566639614 DCDC1TotalLowSideEnergy 8834;
BA_ "SPN" SG_ 2566639870 DCDC1HghSdCrrntMxmmLmtSttng 8826;
BA_ "SPN" SG_ 2566639870 DCDC1HghSdVltgMnmmLmtSttng 8824;
BA_ "SPN" SG_ 2566639870 DCDC1HghSdVltgMxmmLmtSttng 8825;
BA_ "SPN" SG_ 2566639870 DCDC1LwSdCrrntMxmmLmtSttng 8829;
BA_ "SPN" SG_ 2566639870 DCDC1LwSdVltgBkDfltSttng 9519;
BA_ "SPN" SG_ 2566639870 DCDC1LwSdVltgMnmmLmtSttng 8827;
BA_ "SPN" SG_ 2566639870 DCDC1LwSdVltgMxmmLmtSttng 8828;
BA_ "SPN" SG_ 2566639870 DCDC1SLIBttrTmprtrMxmmLmtSttng 8832;
BA_ "SPN" SG_ 2566639870 DCDC1SLIBttTCCtMxLtStt 8831;
BA_ "SPN" SG_ 2566639870 DCDC1SLIBttTVtMxLtStt 8830;
BA_ "SPN" SG_ 2566640382 WellStimulationPumpOilDensity 8661;
BA_ "SPN" SG_ 2566640382 WellStimulationPumpOilViscosity 8660;
BA_ "SPN" SG_ 2566640382 WllStmltnPmpOlRltvDltrt 8662;
BA_ "SPN" SG_ 2566640382 WllStmltnPmpOlTmprtr 8663;
BA_ "SPN" SG_ 2566641150 AltrntrBrngHdrIntkPrssr 8635;
BA_ "SPN" SG_ 2566641150 AltrntrOlClrDshrgPmpPrssr 8636;
BA_ "SPN" SG_ 2566641150 EngnOlClrDshrgPmpPrssr 8637;
BA_ "SPN" SG_ 2566641150 EngnOlClrIntkTmprtr 8638;
BA_ "SPN" SG_ 2566641406 EngnExhstMnfldAsltPrssr1 8619;
BA_ "SPN" SG_ 2566641406 EngnExhstMnfldAsltPrssr2 8620;
BA_ "SPN" SG_ 2566642942 EnableStatusofDoor21 8527;
BA_ "SPN" SG_ 2566642942 EnableStatusofDoor22 8530;
BA_ "SPN" SG_ 2566642942 EnableStatusofDoor23 8533;
BA_ "SPN" SG_ 2566642942 EnableStatusofDoor24 8536;
BA_ "SPN" SG_ 2566642942 EnableStatusofDoor25 8539;
BA_ "SPN" SG_ 2566642942 EnableStatusofDoor26 8542;
BA_ "SPN" SG_ 2566642942 EnableStatusofDoor27 8545;
BA_ "SPN" SG_ 2566642942 EnableStatusofDoor28 8548;
BA_ "SPN" SG_ 2566642942 EnableStatusofDoor29 8551;
BA_ "SPN" SG_ 2566642942 EnableStatusofDoor30 8554;
BA_ "SPN" SG_ 2566642942 LockStatusofDoor21 8525;
BA_ "SPN" SG_ 2566642942 LockStatusofDoor22 8528;
BA_ "SPN" SG_ 2566642942 LockStatusofDoor23 8531;
BA_ "SPN" SG_ 2566642942 LockStatusofDoor24 8534;
BA_ "SPN" SG_ 2566642942 LockStatusofDoor25 8537;
BA_ "SPN" SG_ 2566642942 LockStatusofDoor26 8540;
BA_ "SPN" SG_ 2566642942 LockStatusofDoor27 8543;
BA_ "SPN" SG_ 2566642942 LockStatusofDoor28 8546;
BA_ "SPN" SG_ 2566642942 LockStatusofDoor29 8549;
BA_ "SPN" SG_ 2566642942 LockStatusofDoor30 8552;
BA_ "SPN" SG_ 2566642942 OpenStatusofDoor21 8526;
BA_ "SPN" SG_ 2566642942 OpenStatusofDoor22 8529;
BA_ "SPN" SG_ 2566642942 OpenStatusofDoor23 8532;
BA_ "SPN" SG_ 2566642942 OpenStatusofDoor24 8535;
BA_ "SPN" SG_ 2566642942 OpenStatusofDoor25 8538;
BA_ "SPN" SG_ 2566642942 OpenStatusofDoor26 8541;
BA_ "SPN" SG_ 2566642942 OpenStatusofDoor27 8544;
BA_ "SPN" SG_ 2566642942 OpenStatusofDoor28 8547;
BA_ "SPN" SG_ 2566642942 OpenStatusofDoor29 8550;
BA_ "SPN" SG_ 2566642942 OpenStatusofDoor30 8553;
BA_ "SPN" SG_ 2566643198 EnableStatusofDoor11 8497;
BA_ "SPN" SG_ 2566643198 EnableStatusofDoor12 8500;
BA_ "SPN" SG_ 2566643198 EnableStatusofDoor13 8503;
BA_ "SPN" SG_ 2566643198 EnableStatusofDoor14 8506;
BA_ "SPN" SG_ 2566643198 EnableStatusofDoor15 8509;
BA_ "SPN" SG_ 2566643198 EnableStatusofDoor16 8512;
BA_ "SPN" SG_ 2566643198 EnableStatusofDoor17 8515;
BA_ "SPN" SG_ 2566643198 EnableStatusofDoor18 8518;
BA_ "SPN" SG_ 2566643198 EnableStatusofDoor19 8521;
BA_ "SPN" SG_ 2566643198 EnableStatusofDoor20 8524;
BA_ "SPN" SG_ 2566643198 LockStatusofDoor11 8495;
BA_ "SPN" SG_ 2566643198 LockStatusofDoor12 8498;
BA_ "SPN" SG_ 2566643198 LockStatusofDoor13 8501;
BA_ "SPN" SG_ 2566643198 LockStatusofDoor14 8504;
BA_ "SPN" SG_ 2566643198 LockStatusofDoor15 8507;
BA_ "SPN" SG_ 2566643198 LockStatusofDoor16 8510;
BA_ "SPN" SG_ 2566643198 LockStatusofDoor17 8513;
BA_ "SPN" SG_ 2566643198 LockStatusofDoor18 8516;
BA_ "SPN" SG_ 2566643198 LockStatusofDoor19 8519;
BA_ "SPN" SG_ 2566643198 LockStatusofDoor20 8522;
BA_ "SPN" SG_ 2566643198 OpenStatusofDoor11 8496;
BA_ "SPN" SG_ 2566643198 OpenStatusofDoor12 8499;
BA_ "SPN" SG_ 2566643198 OpenStatusofDoor13 8502;
BA_ "SPN" SG_ 2566643198 OpenStatusofDoor14 8505;
BA_ "SPN" SG_ 2566643198 OpenStatusofDoor15 8508;
BA_ "SPN" SG_ 2566643198 OpenStatusofDoor16 8511;
BA_ "SPN" SG_ 2566643198 OpenStatusofDoor17 8514;
BA_ "SPN" SG_ 2566643198 OpenStatusofDoor18 8517;
BA_ "SPN" SG_ 2566643198 OpenStatusofDoor19 8520;
BA_ "SPN" SG_ 2566643198 OpenStatusofDoor20 8523;
BA_ "SPN" SG_ 2566643454 EngineIntakeCoolantTemperature 8489;
BA_ "SPN" SG_ 2566643454 EngnChrgArClrIntkClntTmprtr 8487;
BA_ "SPN" SG_ 2566643454 EngnChrgArClrOtltClntTmprtr 8488;
BA_ "SPN" SG_ 2566643454 EItMdAtSdCtCtCtDtTpt 12306;
BA_ "SPN" SG_ 2566643710 EngineMixer1IntakePressure 8477;
BA_ "SPN" SG_ 2566643710 EngineMixer2IntakePressure 8607;
BA_ "SPN" SG_ 2566643710 EngnIntkMnfld2AsltPrssrHghRsltn 11731;
BA_ "SPN" SG_ 2566643710 DsrdEngnIntkMnfldPrssrHghLmt 12307;
BA_ "SPN" SG_ 2566644990 DrvrSdFlRptl1CvrStts 8415;
BA_ "SPN" SG_ 2566644990 DrvrSdFlRptl2CvrStts 8416;
BA_ "SPN" SG_ 2566644990 FlStrgCmprtmnt1Tmprtr1 8420;
BA_ "SPN" SG_ 2566644990 FlStrgCmprtmnt1Tmprtr2 8421;
BA_ "SPN" SG_ 2566644990 FlStrgCmprtmnt2Tmprtr1 8422;
BA_ "SPN" SG_ 2566644990 FlStrgCmprtmnt2Tmprtr2 8423;
BA_ "SPN" SG_ 2566644990 FlStrgCmprtmnt3Tmprtr1 8424;
BA_ "SPN" SG_ 2566644990 FlStrgCmprtmnt3Tmprtr2 8425;
BA_ "SPN" SG_ 2566644990 FrontFuelReceptacleCoverStatus 8419;
BA_ "SPN" SG_ 2566644990 PssngrSdFlRptl1CvrStts 8417;
BA_ "SPN" SG_ 2566644990 PssngrSdFlRptl2CvrStts 8418;
BA_ "SPN" SG_ 2566645246 HVESSFanEnableStatus 8403;
BA_ "SPN" SG_ 2566645246 HVESSFanStatusReasonCode 8404;
BA_ "SPN" SG_ 2566645246 HVESSFanCommandStatus 8405;
BA_ "SPN" SG_ 2566645246 HVESSFanSpeed 8406;
BA_ "SPN" SG_ 2566645246 HVESSFanMediumTemperature 8407;
BA_ "SPN" SG_ 2566645246 HVESSFanPower 8408;
BA_ "SPN" SG_ 2566645246 HVESSFanServiceIndicator 8409;
BA_ "SPN" SG_ 2566645246 HVESSFanOperatingStatus 8410;
BA_ "SPN" SG_ 2566645246 HVESSFanInstance 8411;
BA_ "SPN" SG_ 2566646782 OlDrsMntrFrrsBn1Cnt 8168;
BA_ "SPN" SG_ 2566646782 OlDrsMntrFrrsBn2Cnt 8169;
BA_ "SPN" SG_ 2566646782 OlDrsMntrFrrsBns1nd2IdntftnNmr 8167;
BA_ "SPN" SG_ 2566647038 OlDrsMntrFrrsBn3Cnt 8171;
BA_ "SPN" SG_ 2566647038 OlDrsMntrFrrsBn4Cnt 8172;
BA_ "SPN" SG_ 2566647038 OlDrsMntrFrrsBns3nd4IdntftnNmr 8170;
BA_ "SPN" SG_ 2566647294 OlDrsMntrFrrsBn5Cnt 8174;
BA_ "SPN" SG_ 2566647294 OlDrsMntrFrrsBn6Cnt 8175;
BA_ "SPN" SG_ 2566647294 OlDrsMntrFrrsBns5nd6IdntftnNmr 8173;
BA_ "SPN" SG_ 2566647550 ODsMtNFsBs1d2IdttN 8176;
BA_ "SPN" SG_ 2566647550 OlDrsMntrNnFrrsBn1Cnt 8177;
BA_ "SPN" SG_ 2566647550 OlDrsMntrNnFrrsBn2Cnt 8178;
BA_ "SPN" SG_ 2566647806 ODsMtNFsBs3d4IdttN 8179;
BA_ "SPN" SG_ 2566647806 OlDrsMntrNnFrrsBn3Cnt 8180;
BA_ "SPN" SG_ 2566647806 OlDrsMntrNnFrrsBn4Cnt 8181;
BA_ "SPN" SG_ 2566648062 ODsMtNFsBs5d6IdttN 8182;
BA_ "SPN" SG_ 2566648062 OlDrsMntrNnFrrsBn5Cnt 8183;
BA_ "SPN" SG_ 2566648062 OlDrsMntrNnFrrsBn6Cnt 8184;
VAL_ 2565873150 StrngWhlAnglRngCntrTp 3 "SignalNotAvailable" 2 "NotDefined" 1 "AbsNumberOfCounts" 0 "RelativeNumberOfCounts" ;
VAL_ 2565873150 SteeringAngleSensorActiveMode 3 "NotAvailable" 2 "Reserved" 1 "NormalModeActive" 0 "ProgrammingModeActive" ;
VAL_ 2565873150 SteeringAngleSensorCalibrated 3 "NotAvailable" 2 "Reserved" 1 "SASCalibrated" 0 "SASNotCalibrated" ;
VAL_ 2565874174 EngnSpdSnsr3TmngPttrnStts 3 "NotAvailable" 2 "Error" 1 "OK" 0 "NotOK" ;
VAL_ 2565874174 EngnSpdSnsr2TmngPttrnStts 3 "NotAvailable" 2 "Error" 1 "OK" 0 "NotOK" ;
VAL_ 2565874174 EngnSpdSnsr1TmngPttrnStts 3 "NotAvailable" 2 "Error" 1 "OK" 0 "NotOK" ;
